VERSION "created by canmatrix"

NS_ :

BS_:

BU_: IPD

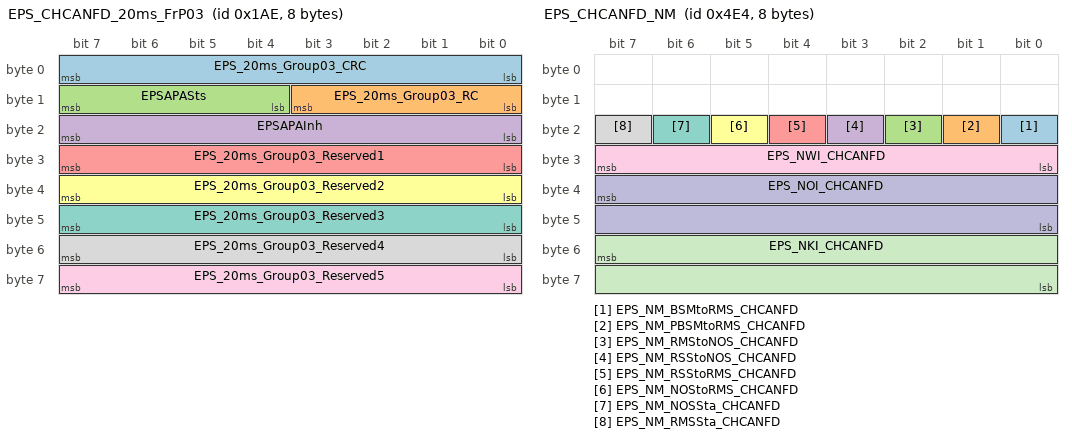
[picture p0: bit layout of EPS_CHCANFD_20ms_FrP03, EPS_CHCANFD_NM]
BO_ 430 EPS_CHCANFD_20ms_FrP03: 8 Vector__XXX
 SG_ EPS_20ms_Group03_CRC : 7|8@0+ (1,0) [0|255] "null" IPD
 SG_ EPS_20ms_Group03_RC : 11|4@0+ (1,0) [0|15] "null" IPD
 SG_ EPSAPASts : 15|4@0+ (1,0) [0|15] "null" IPD
 SG_ EPSAPAInh : 23|8@0+ (1,0) [0|255] "null" IPD
 SG_ EPS_20ms_Group03_Reserved1 : 31|8@0+ (1,0) [0|255] "null" IPD
 SG_ EPS_20ms_Group03_Reserved2 : 39|8@0+ (1,0) [0|255] "null" IPD
 SG_ EPS_20ms_Group03_Reserved3 : 47|8@0+ (1,0) [0|255] "null" IPD
 SG_ EPS_20ms_Group03_Reserved4 : 55|8@0+ (1,0) [0|255] "null" IPD
 SG_ EPS_20ms_Group03_Reserved5 : 63|8@0+ (1,0) [0|255] "null" IPD

BO_ 1681 EPS_CHCANFD_CT_Tx: 8 Vector__XXX
 SG_ EPSCTTX : 7|64@0+ (1,0) [0|18446744073709551615] "null" IPD

BO_ 1252 EPS_CHCANFD_NM: 8 Vector__XXX
 SG_ EPS_NM_BSMtoRMS_CHCANFD : 16|1@0+ (1,0) [0|1] "null" Vector__XXX
 SG_ EPS_NM_PBSMtoRMS_CHCANFD : 17|1@0+ (1,0) [0|1] "null" Vector__XXX
 SG_ EPS_NM_RMStoNOS_CHCANFD : 18|1@0+ (1,0) [0|1] "null" Vector__XXX
 SG_ EPS_NM_RSStoNOS_CHCANFD : 19|1@0+ (1,0) [0|1] "null" Vector__XXX
 SG_ EPS_NM_RSStoRMS_CHCANFD : 20|1@0+ (1,0) [0|1] "null" Vector__XXX
 SG_ EPS_NM_NOStoRMS_CHCANFD : 21|1@0+ (1,0) [0|1] "null" Vector__XXX
 SG_ EPS_NM_NOSSta_CHCANFD : 22|1@0+ (1,0) [0|1] "null" Vector__XXX
 SG_ EPS_NM_RMSSta_CHCANFD : 23|1@0+ (1,0) [0|1] "null" Vector__XXX
 SG_ EPS_NWI_CHCANFD : 31|8@0+ (1,0) [0|255] "null" Vector__XXX
 SG_ EPS_NOI_CHCANFD : 39|16@0+ (1,0) [0|65535] "null" Vector__XXX
 SG_ EPS_NKI_CHCANFD : 55|16@0+ (1,0) [0|65535] "null" Vector__XXX

BO_ 956 FVCM_BKPCANFD_100ms_FrP05: 64 IPD
 SG_ PilotSysMsg : 15|4@0+ (1,0) [0|15] "null" Vector__XXX
 SG_ Lane0_C0 : 23|12@0+ (0.00390625,-8) [-8.00000000|7.99609375] "null" Vector__XXX
 SG_ Lane0_C1 : 27|12@0+ (0.00048828125,-1) [-1.00000000000|0.99951171875] "null" Vector__XXX
 SG_ Lane0_C2 : 47|12@0+ (0.000015259,-0.03124285) [-0.031242850|0.031242755] "null" Vector__XXX
 SG_ Lane0_C3 : 51|12@0+ (4.768E-007,-2.3842E-007) [-2.3842E-007|0.00195225758] "null" Vector__XXX
 SG_ Lane1_C0 : 71|12@0+ (0.00390625,-8) [-8.00000000|7.99609375] "null" Vector__XXX
 SG_ Lane1_C1 : 75|12@0+ (0.00048828125,-1) [-1.00000000000|0.99951171875] "null" Vector__XXX
 SG_ Lane1_C2 : 95|12@0+ (0.000015259,-0.03124285) [-0.031242850|0.031242755] "null" Vector__XXX
 SG_ Lane1_C3 : 99|12@0+ (4.768E-007,-2.3842E-007) [-2.3842E-007|0.00195225758] "null" Vector__XXX
 SG_ Lane2_C0 : 119|12@0+ (0.00390625,-8) [-8.00000000|7.99609375] "null" Vector__XXX
 SG_ Lane2_C1 : 123|12@0+ (0.00048828125,-1) [-1.00000000000|0.99951171875] "null" Vector__XXX
 SG_ Lane2_C2 : 143|12@0+ (0.000015259,-0.03124285) [-0.031242850|0.031242755] "null" Vector__XXX
 SG_ Lane2_C3 : 147|12@0+ (0.0000038147,-0.0078125) [-0.0078125000|0.0078086965] "null" Vector__XXX
 SG_ Lane3_C0 : 167|12@0+ (0.00390625,-8) [-8.00000000|7.99609375] "null" Vector__XXX
 SG_ Lane3_C1 : 171|12@0+ (0.00048828125,-1) [-1.00000000000|0.99951171875] "null" Vector__XXX
 SG_ Lane3_C2 : 191|12@0+ (0.000015259,-0.03124285) [-0.031242850|0.031242755] "null" Vector__XXX
 SG_ Lane3_C3 : 195|12@0+ (0.0000038147,-0.0078125) [-0.0078125000|0.0078086965] "null" Vector__XXX
 SG_ Lane0_ViewRangeStart : 215|8@0+ (0.25,0) [0.00|63.75] "null" Vector__XXX
 SG_ Lane1_ViewRangeStart : 223|8@0+ (0.25,0) [0.00|63.75] "null" Vector__XXX
 SG_ Lane2_ViewRangeStart : 231|8@0+ (0.25,0) [0.00|63.75] "null" Vector__XXX
 SG_ Lane3_ViewRangeStart : 239|8@0+ (0.25,0) [0.00|63.75] "null" Vector__XXX
 SG_ Lane0_ViewRangeEnd : 247|9@0+ (0.25,0) [0.00|127.75] "null" Vector__XXX
 SG_ Lane1_ViewRangeEnd : 248|9@0+ (0.25,0) [0.00|127.75] "null" Vector__XXX
 SG_ Lane0_ExistPrblty : 254|6@0+ (0.015625,0) [0.000000|0.984375] "null" Vector__XXX
 SG_ Lane2_ViewRangeEnd : 271|9@0+ (0.25,0) [0.00|127.75] "null" Vector__XXX
 SG_ Lane3_ViewRangeEnd : 272|9@0+ (0.25,0) [0.00|127.75] "null" Vector__XXX
 SG_ Lane1_ExistPrblty : 278|6@0+ (0.015625,0) [0.000000|0.984375] "null" Vector__XXX
 SG_ Lane0_Part0_SyncFrameIndex : 291|4@0+ (1,0) [0|15] "null" Vector__XXX
 SG_ Lane0_ID : 295|4@0+ (1,0) [0|15] "null" Vector__XXX
 SG_ Lane1_Part0_SyncFrameIndex : 299|4@0+ (1,0) [0|15] "null" Vector__XXX
 SG_ Lane1_ID : 303|4@0+ (1,0) [0|15] "null" Vector__XXX
 SG_ Lane2_Part0_SyncFrameIndex : 307|4@0+ (1,0) [0|15] "null" Vector__XXX
 SG_ Lane2_ID : 311|4@0+ (1,0) [0|15] "null" Vector__XXX
 SG_ Lane3_Part0_SyncFrameIndex : 315|4@0+ (1,0) [0|15] "null" Vector__XXX
 SG_ Lane3_ID : 319|4@0+ (1,0) [0|15] "null" Vector__XXX
 SG_ TLRMsgReq : 321|2@0+ (1,0) [0|3] "null" Vector__XXX
 SG_ Lane0_MarkerColor : 324|3@0+ (1,0) [0|7] "null" Vector__XXX
 SG_ Lane0_location : 327|3@0+ (1,0) [0|7] "null" Vector__XXX
 SG_ TLRSysSts : 329|2@0+ (1,0) [0|3] "null" Vector__XXX
 SG_ Lane1_location : 332|3@0+ (1,0) [0|7] "null" Vector__XXX
 SG_ Lane0_MarkerType : 335|3@0+ (1,0) [0|7] "null" Vector__XXX
 SG_ Lane1_MarkerType : 340|3@0+ (1,0) [0|7] "null" Vector__XXX
 SG_ Lane1_MarkerColor : 343|3@0+ (1,0) [0|7] "null" Vector__XXX
 SG_ Lane2_ExistPrblty : 351|6@0+ (0.015625,0) [0.000000|0.984375] "null" Vector__XXX
 SG_ Lane2_MarkerColor : 356|3@0+ (1,0) [0|7] "null" Vector__XXX
 SG_ Lane2_location : 359|3@0+ (1,0) [0|7] "null" Vector__XXX
 SG_ Lane3_location : 364|3@0+ (1,0) [0|7] "null" Vector__XXX
 SG_ Lane2_MarkerType : 367|3@0+ (1,0) [0|7] "null" Vector__XXX
 SG_ Lane3_ExistPrblty : 375|6@0+ (0.015625,0) [0.000000|0.984375] "null" Vector__XXX
 SG_ Lane3_MarkerType : 380|3@0+ (1,0) [0|7] "null" Vector__XXX
 SG_ Lane3_MarkerColor : 383|3@0+ (1,0) [0|7] "null" Vector__XXX
 SG_ TLRWarning : 388|3@0+ (1,0) [0|7] "null" Vector__XXX
 SG_ TLRMdSwDspCmd : 391|3@0+ (1,0) [0|7] "null" Vector__XXX
 SG_ SpdLmtOfstSetResp : 399|6@0+ (1,-20) [-20|43] "null" Vector__XXX
 SG_ ACCDetObjHdngAng : 495|8@0+ (2,-180) [-180|330] "null" Vector__XXX
 SG_ CCSpdVcCmdCnfm : 503|3@0+ (1,0) [0|7] "null" Vector__XXX

BO_ 163 FVCM_BKPCANFD_10ms_FrP01: 12 IPD
 SG_ FVCM_10ms_Group01_CRC : 7|8@0+ (1,0) [0|255] "null" Vector__XXX
 SG_ FVCM_10ms_Group01_RC : 11|4@0+ (1,0) [0|15] "null" Vector__XXX
 SG_ LKAReqToqSts : 13|2@0+ (1,0) [0|3] "null" Vector__XXX
 SG_ LKAReqAngSts : 15|2@0+ (1,0) [0|3] "null" Vector__XXX
 SG_ LKAReqAng : 23|16@0+ (0.005,-163) [-163.000|164.675] "Degree" Vector__XXX
 SG_ LKAReqToq : 39|11@0+ (0.01,-10.24) [-10.24|10.23] "Nm" Vector__XXX
 SG_ FVCM_10ms_Group01_Reserved1 : 44|5@0+ (1,0) [0|31] "null" Vector__XXX
 SG_ FVCM_10ms_Group01_Reserved2 : 55|8@0+ (1,0) [0|255] "null" Vector__XXX
 SG_ FVCM_10ms_Group01_Reserved3 : 63|8@0+ (1,0) [0|255] "null" Vector__XXX
 SG_ FVCM_10ms_Group01_Reserved4 : 71|8@0+ (1,0) [0|255] "null" Vector__XXX
 SG_ FVCM_10ms_Group01_Reserved5 : 79|8@0+ (1,0) [0|255] "null" Vector__XXX
 SG_ FVCM_10ms_Group01_Reserved6 : 87|8@0+ (1,0) [0|255] "null" Vector__XXX
 SG_ FVCM_10ms_Group01_Reserved7 : 95|8@0+ (1,0) [0|255] "null" Vector__XXX

BO_ 988 IBS_CHCANFD_100ms_FrP15: 8 Vector__XXX
 SG_ IBS_100ms_Group15_CRC : 7|8@0+ (1,0) [0|255] "null" IPD
 SG_ IBS_100ms_Group15_RC : 11|4@0+ (1,0) [0|15] "null" IPD
 SG_ IBS_100ms_Group15_Reserved2 : 12|1@0+ (1,0) [0|1] "null" IPD
 SG_ BrkFltAlrm_GB : 13|1@0+ (1,0) [0|1] "null" IPD
 SG_ IBS_100ms_Group15_Reserved1 : 14|1@0+ (1,0) [0|1] "null" IPD
 SG_ BrkFrc_GB : 15|1@0+ (1,0) [0|1] "null" IPD
 SG_ DistRCAvgDrvnSrc : 16|1@0+ (1,0) [0|1] "null" IPD
 SG_ DistRCAvgDrvnRstOcd : 17|1@0+ (1,0) [0|1] "null" IPD
 SG_ CsbLvlSts : 20|3@0+ (1,0) [0|7] "null" IPD
 SG_ IBSABSlvlResp : 23|3@0+ (1,0) [0|7] "null" IPD
 SG_ DistRCAvgDrvn : 31|13@0+ (0.125,0) [0.000|1023.875] "m" IPD
 SG_ IBS_100ms_Group15_Reserved3 : 33|2@0+ (1,0) [0|3] "null" IPD
 SG_ DistRCAvgDrvnV : 34|1@0+ (1,0) [0|1] "null" IPD
 SG_ IBS_100ms_Group15_Reserved4 : 41|2@0+ (1,0) [0|3] "null" IPD
 SG_ IBSESPlvlResp : 44|3@0+ (1,0) [0|7] "null" IPD
 SG_ IBSTCSlvlResp : 47|3@0+ (1,0) [0|7] "null" IPD
 SG_ IBS_100ms_Group15_Reserved5 : 55|8@0+ (1,0) [0|255] "null" IPD
 SG_ IBS_100ms_Group15_Reserved6 : 63|8@0+ (1,0) [0|255] "null" IPD

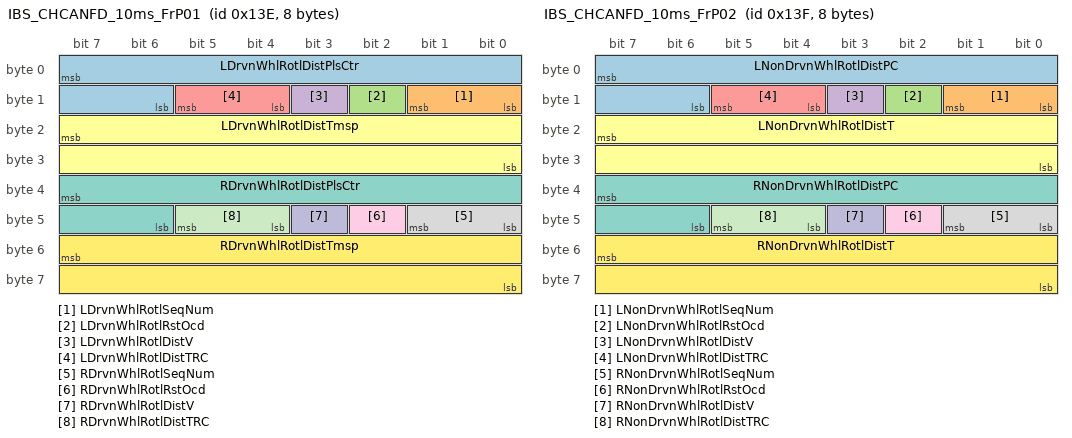
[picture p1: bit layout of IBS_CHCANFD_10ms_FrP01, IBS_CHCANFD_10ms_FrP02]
BO_ 318 IBS_CHCANFD_10ms_FrP01: 8 Vector__XXX
 SG_ LDrvnWhlRotlDistPlsCtr : 7|10@0+ (1,0) [0|1023] "null" IPD
 SG_ LDrvnWhlRotlSeqNum : 9|2@0+ (1,0) [0|3] "null" IPD
 SG_ LDrvnWhlRotlRstOcd : 10|1@0+ (1,0) [0|1] "null" IPD
 SG_ LDrvnWhlRotlDistV : 11|1@0+ (1,0) [0|1] "null" IPD
 SG_ LDrvnWhlRotlDistTRC : 13|2@0+ (1,0) [0|3] "null" IPD
 SG_ LDrvnWhlRotlDistTmsp : 23|16@0+ (1,0) [0|65535] "null" IPD
 SG_ RDrvnWhlRotlDistPlsCtr : 39|10@0+ (1,0) [0|1023] "null" IPD
 SG_ RDrvnWhlRotlSeqNum : 41|2@0+ (1,0) [0|3] "ms" IPD
 SG_ RDrvnWhlRotlRstOcd : 42|1@0+ (1,0) [0|1] "null" IPD
 SG_ RDrvnWhlRotlDistV : 43|1@0+ (1,0) [0|1] "null" IPD
 SG_ RDrvnWhlRotlDistTRC : 45|2@0+ (1,0) [0|3] "ms" IPD
 SG_ RDrvnWhlRotlDistTmsp : 55|16@0+ (1,0) [0|65535] "ms" IPD

BO_ 319 IBS_CHCANFD_10ms_FrP02: 8 Vector__XXX
 SG_ LNonDrvnWhlRotlDistPC : 7|10@0+ (1,0) [0|1023] "null" IPD
 SG_ LNonDrvnWhlRotlSeqNum : 9|2@0+ (1,0) [0|3] "null" IPD
 SG_ LNonDrvnWhlRotlRstOcd : 10|1@0+ (1,0) [0|1] "null" IPD
 SG_ LNonDrvnWhlRotlDistV : 11|1@0+ (1,0) [0|1] "null" IPD
 SG_ LNonDrvnWhlRotlDistTRC : 13|2@0+ (1,0) [0|3] "null" IPD
 SG_ LNonDrvnWhlRotlDistT : 23|16@0+ (1,0) [0|65535] "null" IPD
 SG_ RNonDrvnWhlRotlDistPC : 39|10@0+ (1,0) [0|1023] "null" IPD
 SG_ RNonDrvnWhlRotlSeqNum : 41|2@0+ (1,0) [0|3] "null" IPD
 SG_ RNonDrvnWhlRotlRstOcd : 42|1@0+ (1,0) [0|1] "null" IPD
 SG_ RNonDrvnWhlRotlDistV : 43|1@0+ (1,0) [0|1] "null" IPD
 SG_ RNonDrvnWhlRotlDistTRC : 45|2@0+ (1,0) [0|3] "null" IPD
 SG_ RNonDrvnWhlRotlDistT : 55|16@0+ (1,0) [0|65535] "null" IPD

BO_ 423 IBS_CHCANFD_20ms_FrP07: 8 Vector__XXX
 SG_ IBS_20ms_Group07_CRC : 7|8@0+ (1,0) [0|255] "null" IPD
 SG_ IBS_20ms_Group07_RC : 11|4@0+ (1,0) [0|15] "null" IPD
 SG_ HDCSysSts : 14|3@0+ (1,0) [0|7] "null" IPD
 SG_ ABSIO : 15|1@0+ (1,0) [0|1] "null" IPD
 SG_ VSESysA : 16|1@0+ (1,0) [0|1] "null" IPD
 SG_ BrkSysYlwBrkTlltReq : 17|1@0+ (1,0) [0|1] "null" IPD
 SG_ VSESts : 20|3@0+ (1,0) [0|7] "null" IPD
 SG_ VSEMd : 23|3@0+ (1,0) [0|7] "null" IPD
 SG_ MultColBrkEnbA : 24|1@0+ (1,0) [0|1] "null" IPD
 SG_ EBDFaultSt : 25|1@0+ (1,0) [0|1] "null" IPD
 SG_ TCSOpngSts : 28|3@0+ (1,0) [0|7] "null" IPD
 SG_ TCSOpngMd : 31|3@0+ (1,0) [0|7] "null" IPD
 SG_ BrkSysHillStAstAvlbl : 32|1@0+ (1,0) [0|1] "null" IPD
 SG_ RgtvBrkFnFltSts : 33|1@0+ (1,0) [0|1] "null" IPD
 SG_ MSRF : 34|1@0+ (1,0) [0|1] "null" IPD
 SG_ AutoHoldSysSts : 36|2@0+ (1,0) [0|3] "null" IPD
 SG_ AutoHoldMsg : 39|3@0+ (1,0) [0|7] "null" IPD
 SG_ EBDA : 40|1@0+ (1,0) [0|1] "null" IPD
 SG_ RgtvBrkFnSts : 41|1@0+ (1,0) [0|1] "null" IPD
 SG_ TCSEnbd : 42|1@0+ (1,0) [0|1] "null" IPD
 SG_ HBAActiveSt : 43|1@0+ (1,0) [0|1] "null" IPD
 SG_ TCSA : 44|1@0+ (1,0) [0|1] "null" IPD
 SG_ EnDragToqRducnA : 45|1@0+ (1,0) [0|1] "null" IPD
 SG_ ABSF : 46|1@0+ (1,0) [0|1] "null" IPD
 SG_ ABSA : 47|1@0+ (1,0) [0|1] "null" IPD
 SG_ HBAValidSt : 48|1@0+ (1,0) [0|1] "null" IPD
 SG_ MSRA : 49|1@0+ (1,0) [0|1] "null" IPD
 SG_ EmgcBrkAV : 50|1@0+ (1,0) [0|1] "null" IPD
 SG_ EmgcBrkA : 51|1@0+ (1,0) [0|1] "null" IPD
 SG_ BrkSysRedBrkTlltReq : 52|1@0+ (1,0) [0|1] "null" IPD
 SG_ BrkSysHillStAstSts : 55|3@0+ (1,0) [0|7] "null" IPD
 SG_ AVHSigPdlSts : 57|2@0+ (1,0) [0|3] "null" IPD
 SG_ AutoHoldMdSts : 59|2@0+ (1,0) [0|3] "null" IPD
 SG_ SoftSpSysSts : 61|2@0+ (1,0) [0|3] "null" IPD
 SG_ MulColBrkA : 62|1@0+ (1,0) [0|1] "null" IPD
 SG_ MulColBrkAvlblySts : 63|1@0+ (1,0) [0|1] "null" IPD

BO_ 342 IBS_CHCANFD_20ms_FrP08: 8 Vector__XXX
 SG_ IBS_20ms_Group08_CRC : 7|8@0+ (1,0) [0|255] "null" IPD
 SG_ IBS_20ms_Group08_RC : 11|4@0+ (1,0) [0|15] "null" IPD
 SG_ EPBSts : 13|2@0+ (1,0) [0|3] "null" IPD
 SG_ EPBAppcnSts : 15|2@0+ (1,0) [0|3] "null" IPD
 SG_ EPBCCCanclReqd : 16|1@0+ (1,0) [0|1] "null" IPD
 SG_ EPBSysStsIndReq : 18|2@0+ (1,0) [0|3] "null" IPD
 SG_ EPBSwSts : 20|2@0+ (1,0) [0|3] "null" IPD
 SG_ EPBAvlblySts : 23|3@0+ (1,0) [0|7] "null" IPD
 SG_ EPBSysAudWrnngReq : 25|2@0+ (1,0) [0|3] "null" IPD
 SG_ EPBSwStsV : 26|1@0+ (1,0) [0|1] "null" IPD
 SG_ EPBSysWrnngIndReq : 28|2@0+ (1,0) [0|3] "null" IPD
 SG_ EPBSysDspMsgReq : 31|3@0+ (1,0) [0|7] "null" IPD
 SG_ ChSysTrBrkAxleToqVal : 37|14@0+ (2,0) [0|32766] "Nm" IPD
 SG_ EPBAPAAvlbl : 38|1@0+ (1,0) [0|1] "null" IPD
 SG_ EPBFlrSts : 39|1@0+ (1,0) [0|1] "null" IPD
 SG_ ChSysSecyBrkAxleToqVal : 53|14@0+ (2,0) [0|32766] "Nm" IPD
 SG_ ChSysSecyBrkAxleToqValV : 54|1@0+ (1,0) [0|1] "null" IPD
 SG_ ChSysTrBrkAxleToqValV : 55|1@0+ (1,0) [0|1] "null" IPD

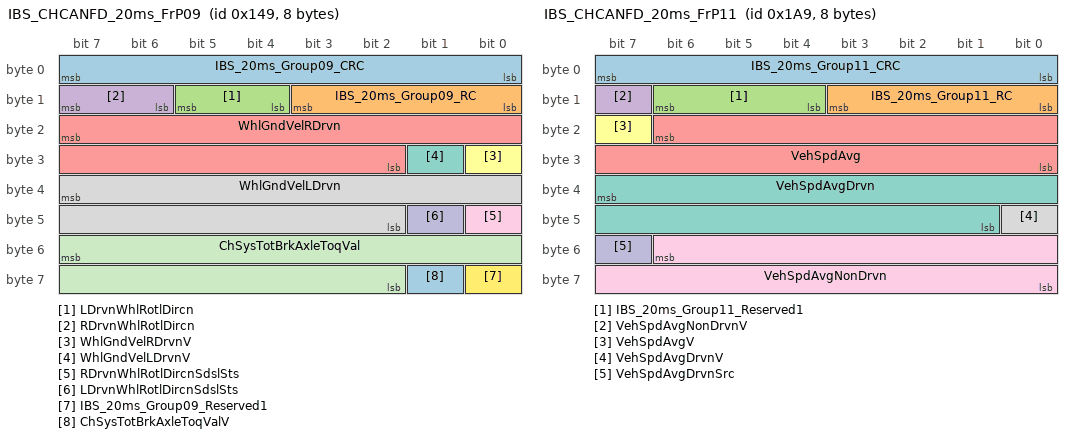
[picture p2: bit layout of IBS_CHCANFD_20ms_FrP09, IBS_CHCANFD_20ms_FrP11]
BO_ 329 IBS_CHCANFD_20ms_FrP09: 8 Vector__XXX
 SG_ IBS_20ms_Group09_CRC : 7|8@0+ (1,0) [0|255] "null" IPD
 SG_ IBS_20ms_Group09_RC : 11|4@0+ (1,0) [0|15] "null" IPD
 SG_ LDrvnWhlRotlDircn : 13|2@0+ (1,0) [0|3] "null" IPD
 SG_ RDrvnWhlRotlDircn : 15|2@0+ (1,0) [0|3] "null" IPD
 SG_ WhlGndVelRDrvn : 23|14@0+ (0.03125,0) [0.00000|511.96875] "kph" IPD
 SG_ WhlGndVelRDrvnV : 24|1@0+ (1,0) [0|1] "null" IPD
 SG_ WhlGndVelLDrvnV : 25|1@0+ (1,0) [0|1] "null" IPD
 SG_ WhlGndVelLDrvn : 39|14@0+ (0.03125,0) [0.00000|511.96875] "kph" IPD
 SG_ RDrvnWhlRotlDircnSdslSts : 40|1@0+ (1,0) [0|1] "null" IPD
 SG_ LDrvnWhlRotlDircnSdslSts : 41|1@0+ (1,0) [0|1] "null" IPD
 SG_ ChSysTotBrkAxleToqVal : 55|14@0+ (2,0) [0|32766] "Nm" IPD
 SG_ IBS_20ms_Group09_Reserved1 : 56|1@0+ (1,0) [0|1] "null" IPD
 SG_ ChSysTotBrkAxleToqValV : 57|1@0+ (1,0) [0|1] "null" IPD

BO_ 425 IBS_CHCANFD_20ms_FrP11: 8 Vector__XXX
 SG_ IBS_20ms_Group11_CRC : 7|8@0+ (1,0) [0|255] "null" IPD
 SG_ IBS_20ms_Group11_RC : 11|4@0+ (1,0) [0|15] "null" IPD
 SG_ IBS_20ms_Group11_Reserved1 : 14|3@0+ (1,0) [0|7] "null" IPD
 SG_ VehSpdAvgNonDrvnV : 15|1@0+ (1,0) [0|1] "null" IPD
 SG_ VehSpdAvg : 22|15@0+ (0.015625,0) [0.000000|511.984375] "km/h" IPD
 SG_ VehSpdAvgV : 23|1@0+ (1,0) [0|1] "null" IPD
 SG_ VehSpdAvgDrvn : 39|15@0+ (0.015625,0) [0.000000|511.984375] "km/h" IPD
 SG_ VehSpdAvgDrvnV : 40|1@0+ (1,0) [0|1] "null" IPD
 SG_ VehSpdAvgNonDrvn : 54|15@0+ (0.015625,0) [0.000000|511.984375] "km/h" IPD
 SG_ VehSpdAvgDrvnSrc : 55|1@0+ (1,0) [0|1] "null" IPD

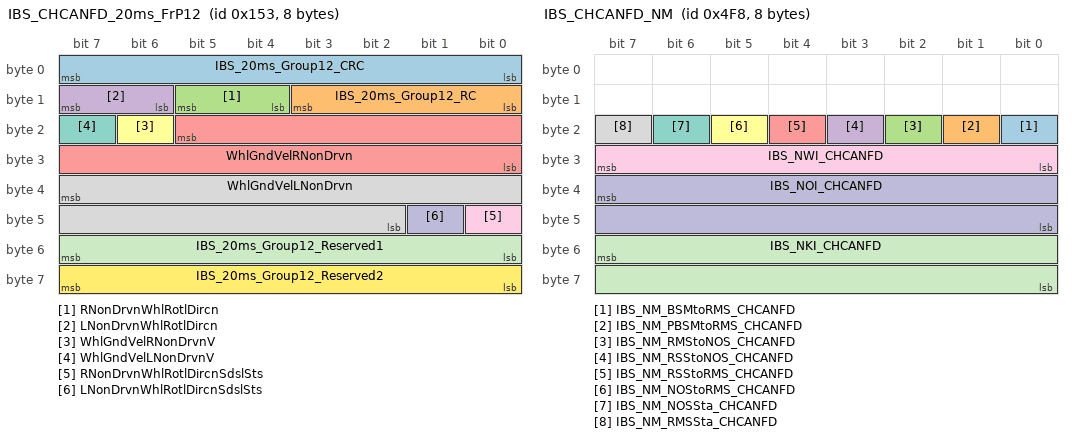
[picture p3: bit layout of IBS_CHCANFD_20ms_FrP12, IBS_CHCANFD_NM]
BO_ 339 IBS_CHCANFD_20ms_FrP12: 8 Vector__XXX
 SG_ IBS_20ms_Group12_CRC : 7|8@0+ (1,0) [0|255] "null" IPD
 SG_ IBS_20ms_Group12_RC : 11|4@0+ (1,0) [0|15] "null" IPD
 SG_ RNonDrvnWhlRotlDircn : 13|2@0+ (1,0) [0|3] "null" IPD
 SG_ LNonDrvnWhlRotlDircn : 15|2@0+ (1,0) [0|3] "null" IPD
 SG_ WhlGndVelRNonDrvn : 21|14@0+ (0.03125,0) [0.00000|511.96875] "kph" IPD
 SG_ WhlGndVelRNonDrvnV : 22|1@0+ (1,0) [0|1] "null" IPD
 SG_ WhlGndVelLNonDrvnV : 23|1@0+ (1,0) [0|1] "null" IPD
 SG_ WhlGndVelLNonDrvn : 39|14@0+ (0.03125,0) [0.00000|511.96875] "kph" IPD
 SG_ RNonDrvnWhlRotlDircnSdslSts : 40|1@0+ (1,0) [0|1] "null" IPD
 SG_ LNonDrvnWhlRotlDircnSdslSts : 41|1@0+ (1,0) [0|1] "null" IPD
 SG_ IBS_20ms_Group12_Reserved1 : 55|8@0+ (1,0) [0|255] "null" IPD
 SG_ IBS_20ms_Group12_Reserved2 : 63|8@0+ (1,0) [0|255] "null" IPD

BO_ 1272 IBS_CHCANFD_NM: 8 Vector__XXX
 SG_ IBS_NM_BSMtoRMS_CHCANFD : 16|1@0+ (1,0) [0|1] "null" Vector__XXX
 SG_ IBS_NM_PBSMtoRMS_CHCANFD : 17|1@0+ (1,0) [0|1] "null" Vector__XXX
 SG_ IBS_NM_RMStoNOS_CHCANFD : 18|1@0+ (1,0) [0|1] "null" Vector__XXX
 SG_ IBS_NM_RSStoNOS_CHCANFD : 19|1@0+ (1,0) [0|1] "null" Vector__XXX
 SG_ IBS_NM_RSStoRMS_CHCANFD : 20|1@0+ (1,0) [0|1] "null" Vector__XXX
 SG_ IBS_NM_NOStoRMS_CHCANFD : 21|1@0+ (1,0) [0|1] "null" Vector__XXX
 SG_ IBS_NM_NOSSta_CHCANFD : 22|1@0+ (1,0) [0|1] "null" Vector__XXX
 SG_ IBS_NM_RMSSta_CHCANFD : 23|1@0+ (1,0) [0|1] "null" Vector__XXX
 SG_ IBS_NWI_CHCANFD : 31|8@0+ (1,0) [0|255] "null" Vector__XXX
 SG_ IBS_NOI_CHCANFD : 39|16@0+ (1,0) [0|65535] "null" Vector__XXX
 SG_ IBS_NKI_CHCANFD : 55|16@0+ (1,0) [0|65535] "null" Vector__XXX

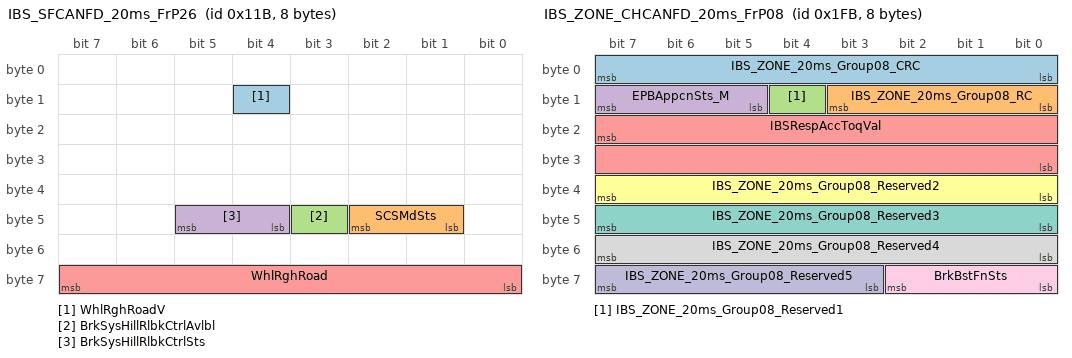
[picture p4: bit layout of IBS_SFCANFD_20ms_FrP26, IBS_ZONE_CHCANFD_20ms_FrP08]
BO_ 283 IBS_SFCANFD_20ms_FrP26: 8 Vector__XXX
 SG_ WhlRghRoadV : 12|1@0+ (1,0) [0|1] "null" IPD
 SG_ SCSMdSts : 42|2@0+ (1,0) [0|3] "null" Vector__XXX
 SG_ BrkSysHillRlbkCtrlAvlbl : 43|1@0+ (1,0) [0|1] "null" Vector__XXX
 SG_ BrkSysHillRlbkCtrlSts : 45|2@0+ (1,0) [0|3] "null" Vector__XXX
 SG_ WhlRghRoad : 63|8@0+ (0.781,0) [0.000|199.155] "null" IPD

BO_ 507 IBS_ZONE_CHCANFD_20ms_FrP08: 8 Vector__XXX
 SG_ IBS_ZONE_20ms_Group08_CRC : 7|8@0+ (1,0) [0|255] "null" IPD
 SG_ IBS_ZONE_20ms_Group08_RC : 11|4@0+ (1,0) [0|15] "null" IPD
 SG_ IBS_ZONE_20ms_Group08_Reserved1 : 12|1@0+ (1,0) [0|1] "null" IPD
 SG_ EPBAppcnSts_M : 15|3@0+ (1,0) [0|7] "null" IPD
 SG_ IBSRespAccToqVal : 23|16@0+ (1,0) [0|65535] "Nm" IPD
 SG_ IBS_ZONE_20ms_Group08_Reserved2 : 39|8@0+ (1,0) [0|255] "null" IPD
 SG_ IBS_ZONE_20ms_Group08_Reserved3 : 47|8@0+ (1,0) [0|255] "null" IPD
 SG_ IBS_ZONE_20ms_Group08_Reserved4 : 55|8@0+ (1,0) [0|255] "null" IPD
 SG_ BrkBstFnSts : 58|3@0+ (1,0) [0|7] "null" IPD
 SG_ IBS_ZONE_20ms_Group08_Reserved5 : 63|5@0+ (1,0) [0|31] "null" IPD

BO_ 382 ICBAD_BKPCANFD_20ms_FrP07: 8 IPD
 SG_ ICBAD_20ms_Group07_CRC : 7|8@0+ (1,0) [0|255] "null" Vector__XXX
 SG_ ICBAD_20ms_Group07_RC : 11|4@0+ (1,0) [0|15] "null" Vector__XXX
 SG_ ACCSdslReq : 12|1@0+ (1,0) [0|1] "null" Vector__XXX
 SG_ ACCGoReq : 13|1@0+ (1,0) [0|1] "null" Vector__XXX
 SG_ ACCAccReqSts_CH : 15|2@0+ (1,0) [0|3] "null" Vector__XXX
 SG_ ACCAccReqVal : 18|11@0+ (0.006,-10.278) [-10.278|2.004] "null" Vector__XXX
 SG_ APAEPBOPReq : 20|2@0+ (1,0) [0|3] "null" Vector__XXX
 SG_ ACCSysFltSts : 23|3@0+ (1,0) [0|7] "null" Vector__XXX
 SG_ AIPkgAPASCSAcclReqVal : 34|11@0+ (0.005,-9.22) [-9.220|1.015] "m/s^2" Vector__XXX
 SG_ ACCSysSts : 37|3@0+ (1,0) [0|7] "null" Vector__XXX
 SG_ APASCSAcclReqSts : 38|1@0+ (1,0) [0|1] "null" Vector__XXX
 SG_ APAEPBOPReqV : 39|1@0+ (1,0) [0|1] "null" Vector__XXX
 SG_ AutodDrvngSysSCSSdslReqV : 48|1@0+ (1,0) [0|1] "null" Vector__XXX
 SG_ AutodDrvngSysSCSSdslReq : 49|1@0+ (1,0) [0|1] "null" Vector__XXX
 SG_ AutodDrvngSysEmgcBrkReqV : 50|1@0+ (1,0) [0|1] "null" Vector__XXX
 SG_ AutodDrvngSysEmgcBrkReq : 51|1@0+ (1,0) [0|1] "null" Vector__XXX
 SG_ ICBAD_20ms_Group07_Reserved1 : 55|4@0+ (1,0) [0|15] "null" Vector__XXX
 SG_ AutodDrvngSysSCSDrvOffReqV : 56|1@0+ (1,0) [0|1] "null" Vector__XXX
 SG_ AutodDrvngSysSCSDrvOffReq : 57|1@0+ (1,0) [0|1] "null" Vector__XXX
 SG_ AutodDrvngSysMdReqV : 58|1@0+ (1,0) [0|1] "null" Vector__XXX
 SG_ AutodDrvngSysMdReq : 59|1@0+ (1,0) [0|1] "null" Vector__XXX
 SG_ AutodDrvngSysFlrStsV : 60|1@0+ (1,0) [0|1] "null" Vector__XXX
 SG_ AutodDrvngSysFlrSts : 63|3@0+ (1,0) [0|7] "null" Vector__XXX

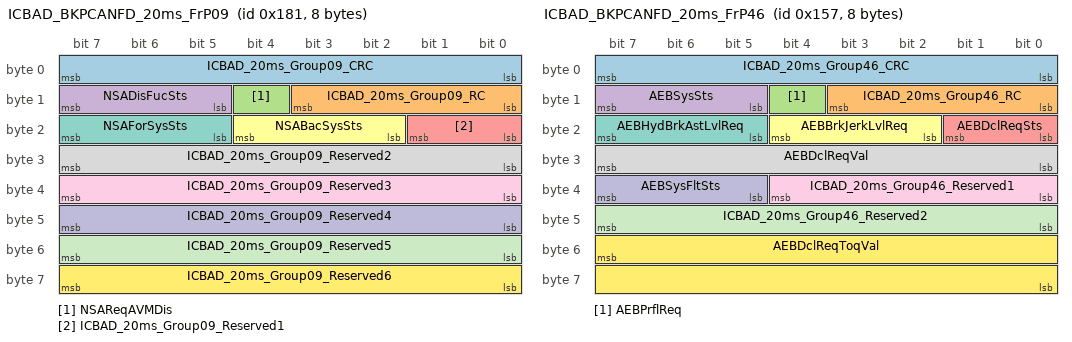
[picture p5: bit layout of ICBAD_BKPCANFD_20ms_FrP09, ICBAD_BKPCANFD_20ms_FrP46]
BO_ 385 ICBAD_BKPCANFD_20ms_FrP09: 8 IPD
 SG_ ICBAD_20ms_Group09_CRC : 7|8@0+ (1,0) [0|255] "null" Vector__XXX
 SG_ ICBAD_20ms_Group09_RC : 11|4@0+ (1,0) [0|15] "null" Vector__XXX
 SG_ NSAReqAVMDis : 12|1@0+ (1,0) [0|1] "null" Vector__XXX
 SG_ NSADisFucSts : 15|3@0+ (1,0) [0|7] "null" Vector__XXX
 SG_ ICBAD_20ms_Group09_Reserved1 : 17|2@0+ (1,0) [0|3] "null" Vector__XXX
 SG_ NSABacSysSts : 20|3@0+ (1,0) [0|7] "null" Vector__XXX
 SG_ NSAForSysSts : 23|3@0+ (1,0) [0|7] "null" Vector__XXX
 SG_ ICBAD_20ms_Group09_Reserved2 : 31|8@0+ (1,0) [0|255] "null" Vector__XXX
 SG_ ICBAD_20ms_Group09_Reserved3 : 39|8@0+ (1,0) [0|255] "null" Vector__XXX
 SG_ ICBAD_20ms_Group09_Reserved4 : 47|8@0+ (1,0) [0|255] "null" Vector__XXX
 SG_ ICBAD_20ms_Group09_Reserved5 : 55|8@0+ (1,0) [0|255] "null" Vector__XXX
 SG_ ICBAD_20ms_Group09_Reserved6 : 63|8@0+ (1,0) [0|255] "null" Vector__XXX

BO_ 343 ICBAD_BKPCANFD_20ms_FrP46: 8 IPD
 SG_ ICBAD_20ms_Group46_CRC : 7|8@0+ (1,0) [0|255] "null" Vector__XXX
 SG_ ICBAD_20ms_Group46_RC : 11|4@0+ (1,0) [0|15] "null" Vector__XXX
 SG_ AEBPrflReq : 12|1@0+ (1,0) [0|1] "null" Vector__XXX
 SG_ AEBSysSts : 15|3@0+ (1,0) [0|7] "null" Vector__XXX
 SG_ AEBDclReqSts : 17|2@0+ (1,0) [0|3] "null" Vector__XXX
 SG_ AEBBrkJerkLvlReq : 20|3@0+ (1,0) [0|7] "null" Vector__XXX
 SG_ AEBHydBrkAstLvlReq : 23|3@0+ (1,0) [0|7] "null" Vector__XXX
 SG_ AEBDclReqVal : 31|8@0+ (0.1,-12.7) [-12.7|12.8] "m/s2" Vector__XXX
 SG_ ICBAD_20ms_Group46_Reserved1 : 36|5@0+ (1,0) [0|31] "null" Vector__XXX
 SG_ AEBSysFltSts : 39|3@0+ (1,0) [0|7] "null" Vector__XXX
 SG_ ICBAD_20ms_Group46_Reserved2 : 47|8@0+ (1,0) [0|255] "null" Vector__XXX
 SG_ AEBDclReqToqVal : 55|16@0+ (1,0) [0|65535] "Nm" Vector__XXX

BO_ 102 ICBAD_CHCANFD_10ms_FrP01: 24 IPD
 SG_ ICBAD_10ms_Group01_CRC : 7|8@0+ (1,0) [0|255] "null" Vector__XXX
 SG_ ICBAD_10ms_Group01_RC : 11|4@0+ (1,0) [0|15] "null" Vector__XXX
 SG_ ICBAD_10ms_Group01_Reserved1 : 15|4@0+ (1,0) [0|15] "null" Vector__XXX
 SG_ PltEPSRdWhlAngReqStsV : 16|1@0+ (1,0) [0|1] "null" Vector__XXX
 SG_ PltEPSRdWhlAngReqSts : 19|3@0+ (1,0) [0|7] "null" Vector__XXX
 SG_ ICBAD_10ms_Group01_Reserved2 : 23|4@0+ (1,0) [0|15] "null" Vector__XXX
 SG_ ICBAD_10ms_Group01_Reserved3 : 31|8@0+ (1,0) [0|255] "null" Vector__XXX
 SG_ ICBAD_10ms_Group01_Reserved4 : 39|8@0+ (1,0) [0|255] "null" Vector__XXX
 SG_ ICBAD_10ms_Group01_Reserved5 : 47|8@0+ (1,0) [0|255] "null" Vector__XXX
 SG_ ICBAD_10ms_Group01_Reserved6 : 55|8@0+ (1,0) [0|255] "null" Vector__XXX
 SG_ ICBAD_10ms_Group01_Reserved7 : 56|1@0+ (1,0) [0|1] "null" Vector__XXX
 SG_ EPSToqAppdCoefnt : 63|7@0+ (0.01,0) [0.00|1.27] "ms" Vector__XXX
 SG_ ICBAD_10ms_Group01_Reserved8 : 71|8@0+ (1,0) [0|255] "null" Vector__XXX
 SG_ ICBAD_10ms_Group01_Reserved9 : 79|8@0+ (1,0) [0|255] "null" Vector__XXX
 SG_ ICBAD_10ms_Group01_Reserved10 : 87|8@0+ (1,0) [0|255] "null" Vector__XXX
 SG_ ICBAD_10ms_Group01_Reserved11 : 95|8@0+ (1,0) [0|255] "null" Vector__XXX
 SG_ ICBAD_10ms_Group01_Reserved12 : 103|8@0+ (1,0) [0|255] "null" Vector__XXX
 SG_ ICBAD_10ms_Group01_Reserved13 : 111|8@0+ (1,0) [0|255] "null" Vector__XXX
 SG_ ICBAD_10ms_Group01_Reserved14 : 119|8@0+ (1,0) [0|255] "null" Vector__XXX
 SG_ ICBAD_10ms_Group01_Reserved15 : 127|8@0+ (1,0) [0|255] "null" Vector__XXX
 SG_ ICBAD_10ms_Group01_Reserved16 : 135|8@0+ (1,0) [0|255] "null" Vector__XXX
 SG_ ICBAD_10ms_Group01_Reserved17 : 143|8@0+ (1,0) [0|255] "null" Vector__XXX
 SG_ ICBAD_10ms_Group01_Reserved18 : 151|8@0+ (1,0) [0|255] "null" Vector__XXX
 SG_ ICBAD_10ms_Group01_Reserved19 : 159|8@0+ (1,0) [0|255] "null" Vector__XXX
 SG_ ICBAD_10ms_Group01_Reserved20 : 167|8@0+ (1,0) [0|255] "null" Vector__XXX
 SG_ ICBAD_10ms_Group01_Reserved21 : 175|8@0+ (1,0) [0|255] "null" Vector__XXX
 SG_ ICBAD_10ms_Group01_Reserved22 : 183|8@0+ (1,0) [0|255] "null" Vector__XXX
 SG_ ICBAD_10ms_Group01_Reserved23 : 191|8@0+ (1,0) [0|255] "null" Vector__XXX

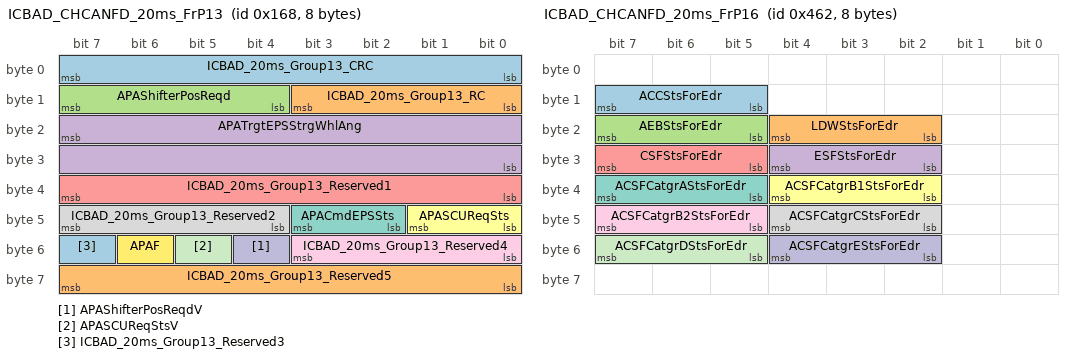
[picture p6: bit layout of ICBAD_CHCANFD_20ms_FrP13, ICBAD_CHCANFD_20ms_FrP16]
BO_ 360 ICBAD_CHCANFD_20ms_FrP13: 8 IPD
 SG_ ICBAD_20ms_Group13_CRC : 7|8@0+ (1,0) [0|255] "null" Vector__XXX
 SG_ ICBAD_20ms_Group13_RC : 11|4@0+ (1,0) [0|15] "null" Vector__XXX
 SG_ APAShifterPosReqd : 15|4@0+ (1,0) [0|15] "null" Vector__XXX
 SG_ APATrgtEPSStrgWhlAng : 23|16@0+ (0.0625,-2048) [-2048.0000|2047.9375] "percent" Vector__XXX
 SG_ ICBAD_20ms_Group13_Reserved1 : 39|8@0+ (1,0) [0|255] "null" Vector__XXX
 SG_ APASCUReqSts : 41|2@0+ (1,0) [0|3] "null" Vector__XXX
 SG_ APACmdEPSSts : 43|2@0+ (1,0) [0|3] "null" Vector__XXX
 SG_ ICBAD_20ms_Group13_Reserved2 : 47|4@0+ (1,0) [0|15] "null" Vector__XXX
 SG_ ICBAD_20ms_Group13_Reserved4 : 51|4@0+ (1,0) [0|15] "null" Vector__XXX
 SG_ APAShifterPosReqdV : 52|1@0+ (1,0) [0|1] "null" Vector__XXX
 SG_ APASCUReqStsV : 53|1@0+ (1,0) [0|1] "null" Vector__XXX
 SG_ APAF : 54|1@0+ (1,0) [0|1] "null" Vector__XXX
 SG_ ICBAD_20ms_Group13_Reserved3 : 55|1@0+ (1,0) [0|1] "null" Vector__XXX
 SG_ ICBAD_20ms_Group13_Reserved5 : 63|8@0+ (1,0) [0|255] "null" Vector__XXX

BO_ 1122 ICBAD_CHCANFD_20ms_FrP16: 8 IPD
 SG_ ACCStsForEdr : 15|3@0+ (1,0) [0|7] "null" Vector__XXX
 SG_ LDWStsForEdr : 20|3@0+ (1,0) [0|7] "null" Vector__XXX
 SG_ AEBStsForEdr : 23|3@0+ (1,0) [0|7] "null" Vector__XXX
 SG_ ESFStsForEdr : 28|3@0+ (1,0) [0|7] "null" Vector__XXX
 SG_ CSFStsForEdr : 31|3@0+ (1,0) [0|7] "null" Vector__XXX
 SG_ ACSFCatgrB1StsForEdr : 36|3@0+ (1,0) [0|7] "null" Vector__XXX
 SG_ ACSFCatgrAStsForEdr : 39|3@0+ (1,0) [0|7] "null" Vector__XXX
 SG_ ACSFCatgrCStsForEdr : 44|3@0+ (1,0) [0|7] "null" Vector__XXX
 SG_ ACSFCatgrB2StsForEdr : 47|3@0+ (1,0) [0|7] "null" Vector__XXX
 SG_ ACSFCatgrEStsForEdr : 52|3@0+ (1,0) [0|7] "null" Vector__XXX
 SG_ ACSFCatgrDStsForEdr : 55|3@0+ (1,0) [0|7] "null" Vector__XXX

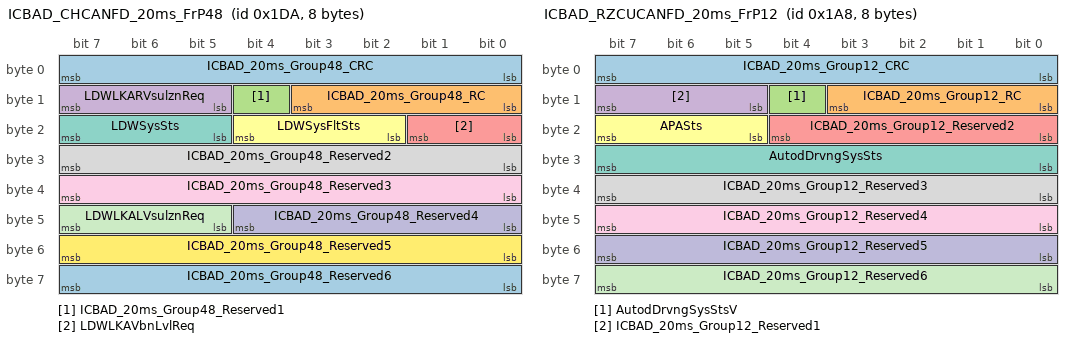
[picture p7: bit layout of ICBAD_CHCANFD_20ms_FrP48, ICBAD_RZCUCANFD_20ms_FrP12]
BO_ 474 ICBAD_CHCANFD_20ms_FrP48: 8 IPD
 SG_ ICBAD_20ms_Group48_CRC : 7|8@0+ (1,0) [0|255] "null" Vector__XXX
 SG_ ICBAD_20ms_Group48_RC : 11|4@0+ (1,0) [0|15] "null" Vector__XXX
 SG_ ICBAD_20ms_Group48_Reserved1 : 12|1@0+ (1,0) [0|1] "null" Vector__XXX
 SG_ LDWLKARVsulznReq : 15|3@0+ (1,0) [0|7] "null" Vector__XXX
 SG_ LDWLKAVbnLvlReq : 17|2@0+ (1,0) [0|3] "null" Vector__XXX
 SG_ LDWSysFltSts : 20|3@0+ (1,0) [0|7] "null" Vector__XXX
 SG_ LDWSysSts : 23|3@0+ (1,0) [0|7] "null" Vector__XXX
 SG_ ICBAD_20ms_Group48_Reserved2 : 31|8@0+ (1,0) [0|255] "null" Vector__XXX
 SG_ ICBAD_20ms_Group48_Reserved3 : 39|8@0+ (1,0) [0|255] "null" Vector__XXX
 SG_ ICBAD_20ms_Group48_Reserved4 : 44|5@0+ (1,0) [0|31] "null" Vector__XXX
 SG_ LDWLKALVsulznReq : 47|3@0+ (1,0) [0|7] "null" Vector__XXX
 SG_ ICBAD_20ms_Group48_Reserved5 : 55|8@0+ (1,0) [0|255] "null" Vector__XXX
 SG_ ICBAD_20ms_Group48_Reserved6 : 63|8@0+ (1,0) [0|255] "null" Vector__XXX

BO_ 47 ICBAD_CHCANFD_Event_FrS03: 16 IPD
 SG_ ToEPSMsgChlg : 7|64@0+ (1,0) [0|18446744073709551615] "null" Vector__XXX

BO_ 424 ICBAD_RZCUCANFD_20ms_FrP12: 8 IPD
 SG_ ICBAD_20ms_Group12_CRC : 7|8@0+ (1,0) [0|255] "null" Vector__XXX
 SG_ ICBAD_20ms_Group12_RC : 11|4@0+ (1,0) [0|15] "null" Vector__XXX
 SG_ AutodDrvngSysStsV : 12|1@0+ (1,0) [0|1] "null" Vector__XXX
 SG_ ICBAD_20ms_Group12_Reserved1 : 15|3@0+ (1,0) [0|7] "null" Vector__XXX
 SG_ ICBAD_20ms_Group12_Reserved2 : 20|5@0+ (1,0) [0|31] "null" Vector__XXX
 SG_ APASts : 23|3@0+ (1,0) [0|7] "null" Vector__XXX
 SG_ AutodDrvngSysSts : 31|8@0+ (1,0) [0|255] "null" Vector__XXX
 SG_ ICBAD_20ms_Group12_Reserved3 : 39|8@0+ (1,0) [0|255] "null" Vector__XXX
 SG_ ICBAD_20ms_Group12_Reserved4 : 47|8@0+ (1,0) [0|255] "null" Vector__XXX
 SG_ ICBAD_20ms_Group12_Reserved5 : 55|8@0+ (1,0) [0|255] "null" Vector__XXX
 SG_ ICBAD_20ms_Group12_Reserved6 : 63|8@0+ (1,0) [0|255] "null" Vector__XXX

BO_ 520 ICBAD_RZCUCANFD_50ms_FrP21: 24 IPD
 SG_ RPShockDistL : 23|10@0+ (0.02,0) [0.00|20.46] "null" Vector__XXX
 SG_ RoadProfileShockLevelL : 29|4@0+ (1,0) [0|15] "null" Vector__XXX
 SG_ RPShockDistR : 39|10@0+ (0.02,0) [0.00|20.46] "null" Vector__XXX
 SG_ RoadProfileShockLevelR : 45|4@0+ (1,0) [0|15] "null" Vector__XXX
 SG_ RoadProfileShockHeightL : 55|9@0- (0.002,0) [-0.512|0.510] "null" Vector__XXX
 SG_ RoadProfileShockDetectedL : 62|1@0+ (1,0) [0|1] "null" Vector__XXX
 SG_ RoadProfileShockHeightR : 71|9@0- (0.002,0) [-0.512|0.510] "null" Vector__XXX
 SG_ RoadProfileShockDetectedR : 78|1@0+ (1,0) [0|1] "null" Vector__XXX
 SG_ RoadProfileShockConfidenceL : 87|7@0+ (0.01,0) [0.00|1.27] "null" Vector__XXX
 SG_ RoadProfileShockConfidenceR : 95|7@0+ (0.01,0) [0.00|1.27] "null" Vector__XXX

BA_DEF_ BO_ "FrameTriggeringName" STRING;
BA_DEF_ BO_ "GenMsgCycleTime" INT 0 65535;
BA_DEF_ BO_ "GenMsgSendType" ENUM  "cyclicX","spontanX","cyclicIfActiveX","spontanWithDelay","cyclicAndSpontanX","cyclicAndSpontanWithDelay","spontanWithRepitition","cyclicIfActiveAndSpontanWD","cyclicIfActiveFast","cyclicWithRepeatOnDemand","none";
BA_DEF_ BO_ "GenMsgStartValue" STRING;
BA_DEF_ BO_ "PduName" STRING;
BA_DEF_ BO_ "VFrameFormat" ENUM  "StandardCAN","ExtendedCAN","reserved","reserved","reserved","reserved","reserved","reserved","reserved","reserved","reserved","reserved","reserved","reserved","StandardCAN_FD","ExtendedCAN_FD";
BA_DEF_ SG_ "CompuMethodName" STRING;
BA_DEF_ SG_ "GenSigStartValue" FLOAT 0 100000000000;
BA_DEF_ SG_ "ISignalName" STRING;
BA_DEF_ SG_ "LongName" STRING;
BA_DEF_ SG_ "SysSignalName" STRING;
BA_DEF_ SG_ "SystemSignalLongSymbol" STRING;
BA_DEF_ BU_ "NWM-Knoten" ENUM  "nein","ja";
BA_DEF_ BU_ "NWM-Stationsadresse" HEX 0 63;
BA_DEF_  "BusType" STRING;
BA_ "NWM-Knoten" BU_ IPD 0;
BA_ "NWM-Stationsadresse" BU_ IPD 0;

BA_ "BusType"   "CAN FD";

BA_ "FrameTriggeringName" BO_ 430 "EPS_CHCANFD_20ms_FrP03";
BA_ "GenMsgCycleTime" BO_ 430 20;
BA_ "GenMsgSendType" BO_ 430 0;
BA_ "GenMsgStartValue" BO_ 430 "007000ffffffffff";
BA_ "PduName" BO_ 430 "EPS_20ms_PDU03";
BA_ "VFrameFormat" BO_ 430 14;
BA_ "FrameTriggeringName" BO_ 1681 "EPS_CHCANFD_CT_Tx";
BA_ "GenMsgSendType" BO_ 1681 1;
BA_ "GenMsgStartValue" BO_ 1681 "0000000000000000";
BA_ "PduName" BO_ 1681 "EPS_CHCANFD_CT_Tx";
BA_ "VFrameFormat" BO_ 1681 14;
BA_ "FrameTriggeringName" BO_ 1252 "EPS_CHCANFD_NM";
BA_ "GenMsgSendType" BO_ 1252 1;
BA_ "GenMsgStartValue" BO_ 1252 "0000000000000000";
BA_ "PduName" BO_ 1252 "NmPDU_CHCANFD_EPS";
BA_ "VFrameFormat" BO_ 1252 14;
BA_ "FrameTriggeringName" BO_ 956 "FVCM_BKPCANFD_100ms_FrP05";
BA_ "GenMsgCycleTime" BO_ 956 100;
BA_ "GenMsgSendType" BO_ 956 0;
BA_ "GenMsgStartValue" BO_ 956 "00000000000000000000000000000000000000000000000000000000000000000000000000000000000000000000000000500000000000000000000000000000";
BA_ "PduName" BO_ 956 "FVCM_100ms_PDU05";
BA_ "VFrameFormat" BO_ 956 14;
BA_ "FrameTriggeringName" BO_ 163 "FVCM_BKPCANFD_10ms_FrP01";
BA_ "GenMsgCycleTime" BO_ 163 10;
BA_ "GenMsgSendType" BO_ 163 0;
BA_ "GenMsgStartValue" BO_ 163 "00007f58801fffffffffffff";
BA_ "PduName" BO_ 163 "FVCM_10ms_PDU01";
BA_ "VFrameFormat" BO_ 163 14;
BA_ "FrameTriggeringName" BO_ 988 "IBS_CHCANFD_100ms_FrP15";
BA_ "GenMsgCycleTime" BO_ 988 100;
BA_ "GenMsgSendType" BO_ 988 0;
BA_ "GenMsgStartValue" BO_ 988 "005000000303ffff";
BA_ "PduName" BO_ 988 "IBS_100ms_PDU15";
BA_ "VFrameFormat" BO_ 988 14;
BA_ "FrameTriggeringName" BO_ 318 "IBS_CHCANFD_10ms_FrP01";
BA_ "GenMsgCycleTime" BO_ 318 10;
BA_ "GenMsgSendType" BO_ 318 0;
BA_ "GenMsgStartValue" BO_ 318 "0000000000000000";
BA_ "PduName" BO_ 318 "IBS_10ms_PDU01";
BA_ "VFrameFormat" BO_ 318 14;
BA_ "FrameTriggeringName" BO_ 319 "IBS_CHCANFD_10ms_FrP02";
BA_ "GenMsgCycleTime" BO_ 319 10;
BA_ "GenMsgSendType" BO_ 319 0;
BA_ "GenMsgStartValue" BO_ 319 "0000000000000000";
BA_ "PduName" BO_ 319 "IBS_10ms_PDU02";
BA_ "VFrameFormat" BO_ 319 14;
BA_ "FrameTriggeringName" BO_ 423 "IBS_CHCANFD_20ms_FrP07";
BA_ "GenMsgCycleTime" BO_ 423 20;
BA_ "GenMsgSendType" BO_ 423 0;
BA_ "GenMsgStartValue" BO_ 423 "0000000000010200";
BA_ "PduName" BO_ 423 "IBS_20ms_PDU07";
BA_ "VFrameFormat" BO_ 423 14;
BA_ "FrameTriggeringName" BO_ 342 "IBS_CHCANFD_20ms_FrP08";
BA_ "GenMsgCycleTime" BO_ 342 20;
BA_ "GenMsgSendType" BO_ 342 0;
BA_ "GenMsgStartValue" BO_ 342 "0000000000000000";
BA_ "PduName" BO_ 342 "IBS_20ms_PDU08";
BA_ "VFrameFormat" BO_ 342 14;
BA_ "FrameTriggeringName" BO_ 329 "IBS_CHCANFD_20ms_FrP09";
BA_ "GenMsgCycleTime" BO_ 329 20;
BA_ "GenMsgSendType" BO_ 329 0;
BA_ "GenMsgStartValue" BO_ 329 "00f0000300000001";
BA_ "PduName" BO_ 329 "IBS_20ms_PDU09";
BA_ "VFrameFormat" BO_ 329 14;
BA_ "FrameTriggeringName" BO_ 425 "IBS_CHCANFD_20ms_FrP11";
BA_ "GenMsgCycleTime" BO_ 425 20;
BA_ "GenMsgSendType" BO_ 425 0;
BA_ "GenMsgStartValue" BO_ 425 "0070000000000000";
BA_ "PduName" BO_ 425 "IBS_20ms_PDU11";
BA_ "VFrameFormat" BO_ 425 14;
BA_ "FrameTriggeringName" BO_ 339 "IBS_CHCANFD_20ms_FrP12";
BA_ "GenMsgCycleTime" BO_ 339 20;
BA_ "GenMsgSendType" BO_ 339 0;
BA_ "GenMsgStartValue" BO_ 339 "00f0c0000000ffff";
BA_ "PduName" BO_ 339 "IBS_20ms_PDU12";
BA_ "VFrameFormat" BO_ 339 14;
BA_ "FrameTriggeringName" BO_ 1272 "IBS_CHCANFD_NM";
BA_ "GenMsgSendType" BO_ 1272 1;
BA_ "GenMsgStartValue" BO_ 1272 "0000000000000000";
BA_ "PduName" BO_ 1272 "NmPDU_CHCANFD_IBS";
BA_ "VFrameFormat" BO_ 1272 14;
BA_ "FrameTriggeringName" BO_ 283 "IBS_SFCANFD_20ms_FrP26";
BA_ "GenMsgCycleTime" BO_ 283 20;
BA_ "GenMsgSendType" BO_ 283 0;
BA_ "GenMsgStartValue" BO_ 283 "0000000000000000";
BA_ "PduName" BO_ 283 "IBS_20ms_PDU26";
BA_ "VFrameFormat" BO_ 283 14;
BA_ "FrameTriggeringName" BO_ 507 "IBS_ZONE_CHCANFD_20ms_FrP08";
BA_ "GenMsgCycleTime" BO_ 507 20;
BA_ "GenMsgSendType" BO_ 507 0;
BA_ "GenMsgStartValue" BO_ 507 "00500000fffffff8";
BA_ "PduName" BO_ 507 "IBS_ZONE_20ms_PDU08";
BA_ "VFrameFormat" BO_ 507 14;
BA_ "FrameTriggeringName" BO_ 382 "ICBAD_BKPCANFD_20ms_FrP07";
BA_ "GenMsgCycleTime" BO_ 382 20;
BA_ "GenMsgSendType" BO_ 382 0;
BA_ "GenMsgStartValue" BO_ 382 "000006b10000f000";
BA_ "PduName" BO_ 382 "ICBAD_20ms_PDU07";
BA_ "VFrameFormat" BO_ 382 14;
BA_ "FrameTriggeringName" BO_ 385 "ICBAD_BKPCANFD_20ms_FrP09";
BA_ "GenMsgCycleTime" BO_ 385 20;
BA_ "GenMsgSendType" BO_ 385 0;
BA_ "GenMsgStartValue" BO_ 385 "000003ffffffffff";
BA_ "PduName" BO_ 385 "ICBAD_20ms_PDU09";
BA_ "VFrameFormat" BO_ 385 14;
BA_ "FrameTriggeringName" BO_ 343 "ICBAD_BKPCANFD_20ms_FrP46";
BA_ "GenMsgCycleTime" BO_ 343 20;
BA_ "GenMsgSendType" BO_ 343 0;
BA_ "GenMsgStartValue" BO_ 343 "0020007f1fff0000";
BA_ "PduName" BO_ 343 "ICBAD_20ms_PDU46";
BA_ "VFrameFormat" BO_ 343 14;
BA_ "FrameTriggeringName" BO_ 102 "ICBAD_CHCANFD_10ms_FrP01";
BA_ "GenMsgCycleTime" BO_ 102 10;
BA_ "GenMsgSendType" BO_ 102 0;
BA_ "GenMsgStartValue" BO_ 102 "00f0f0ffffffff01ffffffffffffffffffffffffffffffff";
BA_ "PduName" BO_ 102 "ICBAD_10ms_PDU01";
BA_ "VFrameFormat" BO_ 102 14;
BA_ "FrameTriggeringName" BO_ 360 "ICBAD_CHCANFD_20ms_FrP13";
BA_ "GenMsgCycleTime" BO_ 360 20;
BA_ "GenMsgSendType" BO_ 360 0;
BA_ "GenMsgStartValue" BO_ 360 "00008000fff08fff";
BA_ "PduName" BO_ 360 "ICBAD_20ms_PDU13";
BA_ "VFrameFormat" BO_ 360 14;
BA_ "FrameTriggeringName" BO_ 1122 "ICBAD_CHCANFD_20ms_FrP16";
BA_ "GenMsgCycleTime" BO_ 1122 20;
BA_ "GenMsgSendType" BO_ 1122 0;
BA_ "GenMsgStartValue" BO_ 1122 "0000000000000000";
BA_ "PduName" BO_ 1122 "ICBAD_20ms_PDU16";
BA_ "VFrameFormat" BO_ 1122 14;
BA_ "FrameTriggeringName" BO_ 474 "ICBAD_CHCANFD_20ms_FrP48";
BA_ "GenMsgCycleTime" BO_ 474 20;
BA_ "GenMsgSendType" BO_ 474 0;
BA_ "GenMsgStartValue" BO_ 474 "001000ffff1fffff";
BA_ "PduName" BO_ 474 "ICBAD_20ms_PDU48";
BA_ "VFrameFormat" BO_ 474 14;
BA_ "FrameTriggeringName" BO_ 47 "ICBAD_CHCANFD_Event_FrS03";
BA_ "GenMsgSendType" BO_ 47 1;
BA_ "GenMsgStartValue" BO_ 47 "00000000000000000000000000000000";
BA_ "PduName" BO_ 47 "ICBAD_Sporadic_PDU03";
BA_ "VFrameFormat" BO_ 47 14;
BA_ "FrameTriggeringName" BO_ 424 "ICBAD_RZCUCANFD_20ms_FrP12";
BA_ "GenMsgCycleTime" BO_ 424 20;
BA_ "GenMsgSendType" BO_ 424 0;
BA_ "GenMsgStartValue" BO_ 424 "00e01f00ffffffff";
BA_ "PduName" BO_ 424 "ICBAD_20ms_PDU12";
BA_ "VFrameFormat" BO_ 424 14;
BA_ "FrameTriggeringName" BO_ 520 "ICBAD_RZCUCANFD_50ms_FrP21";
BA_ "GenMsgCycleTime" BO_ 520 50;
BA_ "GenMsgSendType" BO_ 520 0;
BA_ "GenMsgStartValue" BO_ 520 "000000000000000000000000000000000000000000000000";
BA_ "PduName" BO_ 520 "ICBAD_50ms_PDU21";
BA_ "VFrameFormat" BO_ 520 14;

BA_ "CompuMethodName" SG_ 430 EPS_20ms_Group03_CRC "EPS_20ms_Group03_CRC";
BA_ "ISignalName" SG_ 430 EPS_20ms_Group03_CRC "IEPS_20ms_Group03_CRC";
BA_ "SysSignalName" SG_ 430 EPS_20ms_Group03_CRC "EPS_20ms_Group03_CRC";
BA_ "CompuMethodName" SG_ 430 EPS_20ms_Group03_RC "EPS_20ms_Group03_RC";
BA_ "ISignalName" SG_ 430 EPS_20ms_Group03_RC "IEPS_20ms_Group03_RC";
BA_ "SysSignalName" SG_ 430 EPS_20ms_Group03_RC "EPS_20ms_Group03_RC";
BA_ "CompuMethodName" SG_ 430 EPSAPASts "EPSAPASts";
BA_ "GenSigStartValue" SG_ 430 EPSAPASts 7;
BA_ "ISignalName" SG_ 430 EPSAPASts "IEPSAPASts";
BA_ "LongName" SG_ 430 EPSAPASts "Electric Power Steering Advanced Park Assist Status";
BA_ "SysSignalName" SG_ 430 EPSAPASts "EPSAPASts";
BA_ "CompuMethodName" SG_ 430 EPSAPAInh "EPSAPAInh";
BA_ "ISignalName" SG_ 430 EPSAPAInh "IEPSAPAInh";
BA_ "LongName" SG_ 430 EPSAPAInh "Electric Power Steering Advanced Park Assist Inhibit";
BA_ "SysSignalName" SG_ 430 EPSAPAInh "EPSAPAInh";
BA_ "CompuMethodName" SG_ 430 EPS_20ms_Group03_Reserved1 "EPS_20ms_Group03_Reserved1";
BA_ "GenSigStartValue" SG_ 430 EPS_20ms_Group03_Reserved1 255;
BA_ "ISignalName" SG_ 430 EPS_20ms_Group03_Reserved1 "IEPS_20ms_Group03_Reserved1";
BA_ "SysSignalName" SG_ 430 EPS_20ms_Group03_Reserved1 "EPS_20ms_Group03_Reserved1";
BA_ "CompuMethodName" SG_ 430 EPS_20ms_Group03_Reserved2 "EPS_20ms_Group03_Reserved2";
BA_ "GenSigStartValue" SG_ 430 EPS_20ms_Group03_Reserved2 255;
BA_ "ISignalName" SG_ 430 EPS_20ms_Group03_Reserved2 "IEPS_20ms_Group03_Reserved2";
BA_ "SysSignalName" SG_ 430 EPS_20ms_Group03_Reserved2 "EPS_20ms_Group03_Reserved2";
BA_ "CompuMethodName" SG_ 430 EPS_20ms_Group03_Reserved3 "EPS_20ms_Group03_Reserved3";
BA_ "GenSigStartValue" SG_ 430 EPS_20ms_Group03_Reserved3 255;
BA_ "ISignalName" SG_ 430 EPS_20ms_Group03_Reserved3 "IEPS_20ms_Group03_Reserved3";
BA_ "SysSignalName" SG_ 430 EPS_20ms_Group03_Reserved3 "EPS_20ms_Group03_Reserved3";
BA_ "CompuMethodName" SG_ 430 EPS_20ms_Group03_Reserved4 "EPS_20ms_Group03_Reserved4";
BA_ "GenSigStartValue" SG_ 430 EPS_20ms_Group03_Reserved4 255;
BA_ "ISignalName" SG_ 430 EPS_20ms_Group03_Reserved4 "IEPS_20ms_Group03_Reserved4";
BA_ "SysSignalName" SG_ 430 EPS_20ms_Group03_Reserved4 "EPS_20ms_Group03_Reserved4";
BA_ "CompuMethodName" SG_ 430 EPS_20ms_Group03_Reserved5 "EPS_20ms_Group03_Reserved5";
BA_ "GenSigStartValue" SG_ 430 EPS_20ms_Group03_Reserved5 255;
BA_ "ISignalName" SG_ 430 EPS_20ms_Group03_Reserved5 "IEPS_20ms_Group03_Reserved5";
BA_ "SysSignalName" SG_ 430 EPS_20ms_Group03_Reserved5 "EPS_20ms_Group03_Reserved5";
BA_ "CompuMethodName" SG_ 1681 EPSCTTX "EPSCTTX";
BA_ "ISignalName" SG_ 1681 EPSCTTX "IEPSCTTX";
BA_ "LongName" SG_ 1681 EPSCTTX "Eps Ct Tx";
BA_ "SysSignalName" SG_ 1681 EPSCTTX "EPSCTTX";
BA_ "CompuMethodName" SG_ 1252 EPS_NM_BSMtoRMS_CHCANFD "EPS_NM_BSMtoRMS_CHCANFD";
BA_ "ISignalName" SG_ 1252 EPS_NM_BSMtoRMS_CHCANFD "IEPS_NM_BSMtoRMS_CHCANFD";
BA_ "LongName" SG_ 1252 EPS_NM_BSMtoRMS_CHCANFD "EPS_NM_BSMtoRMS_CHCANFD";
BA_ "SysSignalName" SG_ 1252 EPS_NM_BSMtoRMS_CHCANFD "EPS_NM_BSMtoRMS_CHCANFD";
BA_ "CompuMethodName" SG_ 1252 EPS_NM_PBSMtoRMS_CHCANFD "EPS_NM_PBSMtoRMS_CHCANFD";
BA_ "ISignalName" SG_ 1252 EPS_NM_PBSMtoRMS_CHCANFD "IEPS_NM_PBSMtoRMS_CHCANFD";
BA_ "LongName" SG_ 1252 EPS_NM_PBSMtoRMS_CHCANFD "EPS_NM_PBSMtoRMS_CHCANFD";
BA_ "SysSignalName" SG_ 1252 EPS_NM_PBSMtoRMS_CHCANFD "EPS_NM_PBSMtoRMS_CHCANFD";
BA_ "CompuMethodName" SG_ 1252 EPS_NM_RMStoNOS_CHCANFD "EPS_NM_RMStoNOS_CHCANFD";
BA_ "ISignalName" SG_ 1252 EPS_NM_RMStoNOS_CHCANFD "IEPS_NM_RMStoNOS_CHCANFD";
BA_ "LongName" SG_ 1252 EPS_NM_RMStoNOS_CHCANFD "EPS_NM_RMStoNOS_CHCANFD";
BA_ "SysSignalName" SG_ 1252 EPS_NM_RMStoNOS_CHCANFD "EPS_NM_RMStoNOS_CHCANFD";
BA_ "CompuMethodName" SG_ 1252 EPS_NM_RSStoNOS_CHCANFD "EPS_NM_RSStoNOS_CHCANFD";
BA_ "ISignalName" SG_ 1252 EPS_NM_RSStoNOS_CHCANFD "IEPS_NM_RSStoNOS_CHCANFD";
BA_ "LongName" SG_ 1252 EPS_NM_RSStoNOS_CHCANFD "EPS_NM_RSStoNOS_CHCANFD";
BA_ "SysSignalName" SG_ 1252 EPS_NM_RSStoNOS_CHCANFD "EPS_NM_RSStoNOS_CHCANFD";
BA_ "CompuMethodName" SG_ 1252 EPS_NM_RSStoRMS_CHCANFD "EPS_NM_RSStoRMS_CHCANFD";
BA_ "ISignalName" SG_ 1252 EPS_NM_RSStoRMS_CHCANFD "IEPS_NM_RSStoRMS_CHCANFD";
BA_ "LongName" SG_ 1252 EPS_NM_RSStoRMS_CHCANFD "EPS_NM_RSStoRMS_CHCANFD";
BA_ "SysSignalName" SG_ 1252 EPS_NM_RSStoRMS_CHCANFD "EPS_NM_RSStoRMS_CHCANFD";
BA_ "CompuMethodName" SG_ 1252 EPS_NM_NOStoRMS_CHCANFD "EPS_NM_NOStoRMS_CHCANFD";
BA_ "ISignalName" SG_ 1252 EPS_NM_NOStoRMS_CHCANFD "IEPS_NM_NOStoRMS_CHCANFD";
BA_ "LongName" SG_ 1252 EPS_NM_NOStoRMS_CHCANFD "EPS_NM_NOStoRMS_CHCANFD";
BA_ "SysSignalName" SG_ 1252 EPS_NM_NOStoRMS_CHCANFD "EPS_NM_NOStoRMS_CHCANFD";
BA_ "CompuMethodName" SG_ 1252 EPS_NM_NOSSta_CHCANFD "EPS_NM_NOSSta_CHCANFD";
BA_ "ISignalName" SG_ 1252 EPS_NM_NOSSta_CHCANFD "IEPS_NM_NOSSta_CHCANFD";
BA_ "LongName" SG_ 1252 EPS_NM_NOSSta_CHCANFD "EPS_NM_NOSSta_CHCANFD";
BA_ "SysSignalName" SG_ 1252 EPS_NM_NOSSta_CHCANFD "EPS_NM_NOSSta_CHCANFD";
BA_ "CompuMethodName" SG_ 1252 EPS_NM_RMSSta_CHCANFD "EPS_NM_RMSSta_CHCANFD";
BA_ "ISignalName" SG_ 1252 EPS_NM_RMSSta_CHCANFD "IEPS_NM_RMSSta_CHCANFD";
BA_ "LongName" SG_ 1252 EPS_NM_RMSSta_CHCANFD "EPS_NM_RMSSta_CHCANFD";
BA_ "SysSignalName" SG_ 1252 EPS_NM_RMSSta_CHCANFD "EPS_NM_RMSSta_CHCANFD";
BA_ "CompuMethodName" SG_ 1252 EPS_NWI_CHCANFD "EPS_NWI_CHCANFD";
BA_ "ISignalName" SG_ 1252 EPS_NWI_CHCANFD "IEPS_NWI_CHCANFD";
BA_ "LongName" SG_ 1252 EPS_NWI_CHCANFD "EPS CHCANFD Network_Wakeup_Indication";
BA_ "SysSignalName" SG_ 1252 EPS_NWI_CHCANFD "EPS_NWI_CHCANFD";
BA_ "CompuMethodName" SG_ 1252 EPS_NOI_CHCANFD "EPS_NOI_CHCANFD";
BA_ "ISignalName" SG_ 1252 EPS_NOI_CHCANFD "IEPS_NOI_CHCANFD";
BA_ "LongName" SG_ 1252 EPS_NOI_CHCANFD "EPS CHCANFD Network Operation Indication";
BA_ "SysSignalName" SG_ 1252 EPS_NOI_CHCANFD "EPS_NOI_CHCANFD";
BA_ "CompuMethodName" SG_ 1252 EPS_NKI_CHCANFD "EPS_NKI_CHCANFD";
BA_ "ISignalName" SG_ 1252 EPS_NKI_CHCANFD "IEPS_NKI_CHCANFD";
BA_ "LongName" SG_ 1252 EPS_NKI_CHCANFD "EPS CHCANFD Network Keep Indication";
BA_ "SysSignalName" SG_ 1252 EPS_NKI_CHCANFD "EPS_NKI_CHCANFD";
BA_ "CompuMethodName" SG_ 956 PilotSysMsg "PilotSysMsg";
BA_ "ISignalName" SG_ 956 PilotSysMsg "IPilotSysMsg";
BA_ "LongName" SG_ 956 PilotSysMsg "Pilot System Message";
BA_ "SysSignalName" SG_ 956 PilotSysMsg "PilotSysMsg";
BA_ "CompuMethodName" SG_ 956 Lane0_C0 "Lane0_C0";
BA_ "ISignalName" SG_ 956 Lane0_C0 "ILane0_C0";
BA_ "LongName" SG_ 956 Lane0_C0 "Lane_0_Curve_Parameter_C0";
BA_ "SysSignalName" SG_ 956 Lane0_C0 "Lane0_C0";
BA_ "CompuMethodName" SG_ 956 Lane0_C1 "Lane0_C1";
BA_ "ISignalName" SG_ 956 Lane0_C1 "ILane0_C1";
BA_ "LongName" SG_ 956 Lane0_C1 "Lane_0_Curve_Parameter_C1";
BA_ "SysSignalName" SG_ 956 Lane0_C1 "Lane0_C1";
BA_ "CompuMethodName" SG_ 956 Lane0_C2 "Lane0_C2";
BA_ "ISignalName" SG_ 956 Lane0_C2 "ILane0_C2";
BA_ "LongName" SG_ 956 Lane0_C2 "Lane_0_Curve_Parameter_C2";
BA_ "SysSignalName" SG_ 956 Lane0_C2 "Lane0_C2";
BA_ "CompuMethodName" SG_ 956 Lane0_C3 "Lane0_C3";
BA_ "ISignalName" SG_ 956 Lane0_C3 "ILane0_C3";
BA_ "LongName" SG_ 956 Lane0_C3 "Lane_0_Curve_Parameter_C3";
BA_ "SysSignalName" SG_ 956 Lane0_C3 "Lane0_C3";
BA_ "CompuMethodName" SG_ 956 Lane1_C0 "Lane1_C0";
BA_ "ISignalName" SG_ 956 Lane1_C0 "ILane1_C0";
BA_ "LongName" SG_ 956 Lane1_C0 "Lane_1_Curve_Parameter_C0";
BA_ "SysSignalName" SG_ 956 Lane1_C0 "Lane1_C0";
BA_ "CompuMethodName" SG_ 956 Lane1_C1 "Lane1_C1";
BA_ "ISignalName" SG_ 956 Lane1_C1 "ILane1_C1";
BA_ "LongName" SG_ 956 Lane1_C1 "Lane_1_Curve_Parameter_C1";
BA_ "SysSignalName" SG_ 956 Lane1_C1 "Lane1_C1";
BA_ "CompuMethodName" SG_ 956 Lane1_C2 "Lane1_C2";
BA_ "ISignalName" SG_ 956 Lane1_C2 "ILane1_C2";
BA_ "LongName" SG_ 956 Lane1_C2 "Lane_1_Curve_Parameter_C2";
BA_ "SysSignalName" SG_ 956 Lane1_C2 "Lane1_C2";
BA_ "CompuMethodName" SG_ 956 Lane1_C3 "Lane1_C3";
BA_ "ISignalName" SG_ 956 Lane1_C3 "ILane1_C3";
BA_ "LongName" SG_ 956 Lane1_C3 "Lane_1_Curve_Parameter_C3";
BA_ "SysSignalName" SG_ 956 Lane1_C3 "Lane1_C3";
BA_ "CompuMethodName" SG_ 956 Lane2_C0 "Lane2_C0";
BA_ "ISignalName" SG_ 956 Lane2_C0 "ILane2_C0";
BA_ "LongName" SG_ 956 Lane2_C0 "Lane_2_Curve_Parameter_C0";
BA_ "SysSignalName" SG_ 956 Lane2_C0 "Lane2_C0";
BA_ "CompuMethodName" SG_ 956 Lane2_C1 "Lane2_C1";
BA_ "ISignalName" SG_ 956 Lane2_C1 "ILane2_C1";
BA_ "LongName" SG_ 956 Lane2_C1 "Lane_2_Curve_Parameter_C1";
BA_ "SysSignalName" SG_ 956 Lane2_C1 "Lane2_C1";
BA_ "CompuMethodName" SG_ 956 Lane2_C2 "Lane2_C2";
BA_ "ISignalName" SG_ 956 Lane2_C2 "ILane2_C2";
BA_ "LongName" SG_ 956 Lane2_C2 "Lane_2_Curve_Parameter_C2";
BA_ "SysSignalName" SG_ 956 Lane2_C2 "Lane2_C2";
BA_ "CompuMethodName" SG_ 956 Lane2_C3 "Lane2_C3";
BA_ "ISignalName" SG_ 956 Lane2_C3 "ILane2_C3";
BA_ "LongName" SG_ 956 Lane2_C3 "Lane_2_Curve_Parameter_C3";
BA_ "SysSignalName" SG_ 956 Lane2_C3 "Lane2_C3";
BA_ "CompuMethodName" SG_ 956 Lane3_C0 "Lane3_C0";
BA_ "ISignalName" SG_ 956 Lane3_C0 "ILane3_C0";
BA_ "LongName" SG_ 956 Lane3_C0 "Lane_3_Curve_Parameter_C0";
BA_ "SysSignalName" SG_ 956 Lane3_C0 "Lane3_C0";
BA_ "CompuMethodName" SG_ 956 Lane3_C1 "Lane3_C1";
BA_ "ISignalName" SG_ 956 Lane3_C1 "ILane3_C1";
BA_ "LongName" SG_ 956 Lane3_C1 "Lane_3_Curve_Parameter_C1";
BA_ "SysSignalName" SG_ 956 Lane3_C1 "Lane3_C1";
BA_ "CompuMethodName" SG_ 956 Lane3_C2 "Lane3_C2";
BA_ "ISignalName" SG_ 956 Lane3_C2 "ILane3_C2";
BA_ "LongName" SG_ 956 Lane3_C2 "Lane_3_Curve_Parameter_C2";
BA_ "SysSignalName" SG_ 956 Lane3_C2 "Lane3_C2";
BA_ "CompuMethodName" SG_ 956 Lane3_C3 "Lane3_C3";
BA_ "ISignalName" SG_ 956 Lane3_C3 "ILane3_C3";
BA_ "LongName" SG_ 956 Lane3_C3 "Lane_3_Curve_Parameter_C3";
BA_ "SysSignalName" SG_ 956 Lane3_C3 "Lane3_C3";
BA_ "CompuMethodName" SG_ 956 Lane0_ViewRangeStart "Lane0_ViewRangeStart";
BA_ "ISignalName" SG_ 956 Lane0_ViewRangeStart "ILane0_ViewRangeStart";
BA_ "LongName" SG_ 956 Lane0_ViewRangeStart "Lane_0_Curve_Longitudinal_Distance_Start";
BA_ "SysSignalName" SG_ 956 Lane0_ViewRangeStart "Lane0_ViewRangeStart";
BA_ "CompuMethodName" SG_ 956 Lane1_ViewRangeStart "Lane1_ViewRangeStart";
BA_ "ISignalName" SG_ 956 Lane1_ViewRangeStart "ILane1_ViewRangeStart";
BA_ "LongName" SG_ 956 Lane1_ViewRangeStart "Lane_1_Curve_Longitudinal_Distance_Start";
BA_ "SysSignalName" SG_ 956 Lane1_ViewRangeStart "Lane1_ViewRangeStart";
BA_ "CompuMethodName" SG_ 956 Lane2_ViewRangeStart "Lane2_ViewRangeStart";
BA_ "ISignalName" SG_ 956 Lane2_ViewRangeStart "ILane2_ViewRangeStart";
BA_ "LongName" SG_ 956 Lane2_ViewRangeStart "Lane_2_Curve_Longitudinal_Distance_Start";
BA_ "SysSignalName" SG_ 956 Lane2_ViewRangeStart "Lane2_ViewRangeStart";
BA_ "CompuMethodName" SG_ 956 Lane3_ViewRangeStart "Lane3_ViewRangeStart";
BA_ "ISignalName" SG_ 956 Lane3_ViewRangeStart "ILane3_ViewRangeStart";
BA_ "LongName" SG_ 956 Lane3_ViewRangeStart "Lane_3_Curve_Longitudinal_Distance_Start";
BA_ "SysSignalName" SG_ 956 Lane3_ViewRangeStart "Lane3_ViewRangeStart";
BA_ "CompuMethodName" SG_ 956 Lane0_ViewRangeEnd "Lane0_ViewRangeEnd";
BA_ "ISignalName" SG_ 956 Lane0_ViewRangeEnd "ILane0_ViewRangeEnd";
BA_ "LongName" SG_ 956 Lane0_ViewRangeEnd "Lane_0_Curve_Longitudinal_Distance_Stop";
BA_ "SysSignalName" SG_ 956 Lane0_ViewRangeEnd "Lane0_ViewRangeEnd";
BA_ "CompuMethodName" SG_ 956 Lane1_ViewRangeEnd "Lane1_ViewRangeEnd";
BA_ "ISignalName" SG_ 956 Lane1_ViewRangeEnd "ILane1_ViewRangeEnd";
BA_ "LongName" SG_ 956 Lane1_ViewRangeEnd "Lane_1_Curve_Longitudinal_Distance_Stop";
BA_ "SysSignalName" SG_ 956 Lane1_ViewRangeEnd "Lane1_ViewRangeEnd";
BA_ "CompuMethodName" SG_ 956 Lane0_ExistPrblty "Lane0_ExistPrblty";
BA_ "ISignalName" SG_ 956 Lane0_ExistPrblty "ILane0_ExistPrblty";
BA_ "LongName" SG_ 956 Lane0_ExistPrblty "Lane_0_Exist_Probability";
BA_ "SysSignalName" SG_ 956 Lane0_ExistPrblty "Lane0_ExistPrblty";
BA_ "CompuMethodName" SG_ 956 Lane2_ViewRangeEnd "Lane2_ViewRangeEnd";
BA_ "ISignalName" SG_ 956 Lane2_ViewRangeEnd "ILane2_ViewRangeEnd";
BA_ "LongName" SG_ 956 Lane2_ViewRangeEnd "Lane_2_Curve_Longitudinal_Distance_Stop";
BA_ "SysSignalName" SG_ 956 Lane2_ViewRangeEnd "Lane2_ViewRangeEnd";
BA_ "CompuMethodName" SG_ 956 Lane3_ViewRangeEnd "Lane3_ViewRangeEnd";
BA_ "ISignalName" SG_ 956 Lane3_ViewRangeEnd "ILane3_ViewRangeEnd";
BA_ "LongName" SG_ 956 Lane3_ViewRangeEnd "Lane_3_Curve_Longitudinal_Distance_Stop";
BA_ "SysSignalName" SG_ 956 Lane3_ViewRangeEnd "Lane3_ViewRangeEnd";
BA_ "CompuMethodName" SG_ 956 Lane1_ExistPrblty "Lane1_ExistPrblty";
BA_ "ISignalName" SG_ 956 Lane1_ExistPrblty "ILane1_ExistPrblty";
BA_ "LongName" SG_ 956 Lane1_ExistPrblty "Lane_1_Exist_Probability";
BA_ "SysSignalName" SG_ 956 Lane1_ExistPrblty "Lane1_ExistPrblty";
BA_ "CompuMethodName" SG_ 956 Lane0_Part0_SyncFrameIndex "Lane0_Part0_SyncFrameIndex";
BA_ "ISignalName" SG_ 956 Lane0_Part0_SyncFrameIndex "ILane0_Part0_SyncFrameIndex";
BA_ "LongName" SG_ 956 Lane0_Part0_SyncFrameIndex "Lane_0_Synchronize_Counter";
BA_ "SysSignalName" SG_ 956 Lane0_Part0_SyncFrameIndex "Lane0_Part0_SyncFrameIndex";
BA_ "CompuMethodName" SG_ 956 Lane0_ID "Lane0_ID";
BA_ "ISignalName" SG_ 956 Lane0_ID "ILane0_ID";
BA_ "LongName" SG_ 956 Lane0_ID "Lane_0_Identifier";
BA_ "SysSignalName" SG_ 956 Lane0_ID "Lane0_ID";
BA_ "CompuMethodName" SG_ 956 Lane1_Part0_SyncFrameIndex "Lane1_Part0_SyncFrameIndex";
BA_ "ISignalName" SG_ 956 Lane1_Part0_SyncFrameIndex "ILane1_Part0_SyncFrameIndex";
BA_ "LongName" SG_ 956 Lane1_Part0_SyncFrameIndex "Lane_1_Synchronize_Counter";
BA_ "SysSignalName" SG_ 956 Lane1_Part0_SyncFrameIndex "Lane1_Part0_SyncFrameIndex";
BA_ "CompuMethodName" SG_ 956 Lane1_ID "Lane1_ID";
BA_ "ISignalName" SG_ 956 Lane1_ID "ILane1_ID";
BA_ "LongName" SG_ 956 Lane1_ID "Lane_1_Identifier";
BA_ "SysSignalName" SG_ 956 Lane1_ID "Lane1_ID";
BA_ "CompuMethodName" SG_ 956 Lane2_Part0_SyncFrameIndex "Lane2_Part0_SyncFrameIndex";
BA_ "ISignalName" SG_ 956 Lane2_Part0_SyncFrameIndex "ILane2_Part0_SyncFrameIndex";
BA_ "LongName" SG_ 956 Lane2_Part0_SyncFrameIndex "Lane_2_Synchronize_Counter";
BA_ "SysSignalName" SG_ 956 Lane2_Part0_SyncFrameIndex "Lane2_Part0_SyncFrameIndex";
BA_ "CompuMethodName" SG_ 956 Lane2_ID "Lane2_ID";
BA_ "ISignalName" SG_ 956 Lane2_ID "ILane2_ID";
BA_ "LongName" SG_ 956 Lane2_ID "Lane_2_Identifier";
BA_ "SysSignalName" SG_ 956 Lane2_ID "Lane2_ID";
BA_ "CompuMethodName" SG_ 956 Lane3_Part0_SyncFrameIndex "Lane3_Part0_SyncFrameIndex";
BA_ "ISignalName" SG_ 956 Lane3_Part0_SyncFrameIndex "ILane3_Part0_SyncFrameIndex";
BA_ "LongName" SG_ 956 Lane3_Part0_SyncFrameIndex "Lane_3_Synchronize_Counter";
BA_ "SysSignalName" SG_ 956 Lane3_Part0_SyncFrameIndex "Lane3_Part0_SyncFrameIndex";
BA_ "CompuMethodName" SG_ 956 Lane3_ID "Lane3_ID";
BA_ "ISignalName" SG_ 956 Lane3_ID "ILane3_ID";
BA_ "LongName" SG_ 956 Lane3_ID "Lane_3_Identifier";
BA_ "SysSignalName" SG_ 956 Lane3_ID "Lane3_ID";
BA_ "CompuMethodName" SG_ 956 TLRMsgReq "TLRMsgReq";
BA_ "ISignalName" SG_ 956 TLRMsgReq "ITLRMsgReq";
BA_ "LongName" SG_ 956 TLRMsgReq "Traffic_lights_recognition_Message_Request";
BA_ "SysSignalName" SG_ 956 TLRMsgReq "TLRMsgReq";
BA_ "CompuMethodName" SG_ 956 Lane0_MarkerColor "Lane0_MarkerColor";
BA_ "ISignalName" SG_ 956 Lane0_MarkerColor "ILane0_MarkerColor";
BA_ "LongName" SG_ 956 Lane0_MarkerColor "Lane_0_Line_Color";
BA_ "SysSignalName" SG_ 956 Lane0_MarkerColor "Lane0_MarkerColor";
BA_ "CompuMethodName" SG_ 956 Lane0_location "Lane0_location";
BA_ "ISignalName" SG_ 956 Lane0_location "ILane0_location";
BA_ "LongName" SG_ 956 Lane0_location "Lane_0_Position";
BA_ "SysSignalName" SG_ 956 Lane0_location "Lane0_location";
BA_ "CompuMethodName" SG_ 956 TLRSysSts "TLRSysSts";
BA_ "ISignalName" SG_ 956 TLRSysSts "ITLRSysSts";
BA_ "LongName" SG_ 956 TLRSysSts "Traffic_lights_recognition_System_Status";
BA_ "SysSignalName" SG_ 956 TLRSysSts "TLRSysSts";
BA_ "CompuMethodName" SG_ 956 Lane1_location "Lane1_location";
BA_ "ISignalName" SG_ 956 Lane1_location "ILane1_location";
BA_ "LongName" SG_ 956 Lane1_location "Lane_1_Position";
BA_ "SysSignalName" SG_ 956 Lane1_location "Lane1_location";
BA_ "CompuMethodName" SG_ 956 Lane0_MarkerType "Lane0_MarkerType";
BA_ "ISignalName" SG_ 956 Lane0_MarkerType "ILane0_MarkerType";
BA_ "LongName" SG_ 956 Lane0_MarkerType "Lane_0_Marker_Type";
BA_ "SysSignalName" SG_ 956 Lane0_MarkerType "Lane0_MarkerType";
BA_ "CompuMethodName" SG_ 956 Lane1_MarkerType "Lane1_MarkerType";
BA_ "ISignalName" SG_ 956 Lane1_MarkerType "ILane1_MarkerType";
BA_ "LongName" SG_ 956 Lane1_MarkerType "Lane_1_Marker_Type";
BA_ "SysSignalName" SG_ 956 Lane1_MarkerType "Lane1_MarkerType";
BA_ "CompuMethodName" SG_ 956 Lane1_MarkerColor "Lane1_MarkerColor";
BA_ "ISignalName" SG_ 956 Lane1_MarkerColor "ILane1_MarkerColor";
BA_ "LongName" SG_ 956 Lane1_MarkerColor "Lane_1_Line_Color";
BA_ "SysSignalName" SG_ 956 Lane1_MarkerColor "Lane1_MarkerColor";
BA_ "CompuMethodName" SG_ 956 Lane2_ExistPrblty "Lane2_ExistPrblty";
BA_ "ISignalName" SG_ 956 Lane2_ExistPrblty "ILane2_ExistPrblty";
BA_ "LongName" SG_ 956 Lane2_ExistPrblty "Lane_2_Exist_Probability";
BA_ "SysSignalName" SG_ 956 Lane2_ExistPrblty "Lane2_ExistPrblty";
BA_ "CompuMethodName" SG_ 956 Lane2_MarkerColor "Lane2_MarkerColor";
BA_ "ISignalName" SG_ 956 Lane2_MarkerColor "ILane2_MarkerColor";
BA_ "LongName" SG_ 956 Lane2_MarkerColor "Lane_2_Line_Color";
BA_ "SysSignalName" SG_ 956 Lane2_MarkerColor "Lane2_MarkerColor";
BA_ "CompuMethodName" SG_ 956 Lane2_location "Lane2_location";
BA_ "ISignalName" SG_ 956 Lane2_location "ILane2_location";
BA_ "LongName" SG_ 956 Lane2_location "Lane_2_Position";
BA_ "SysSignalName" SG_ 956 Lane2_location "Lane2_location";
BA_ "CompuMethodName" SG_ 956 Lane3_location "Lane3_location";
BA_ "ISignalName" SG_ 956 Lane3_location "ILane3_location";
BA_ "LongName" SG_ 956 Lane3_location "Lane_3_Position";
BA_ "SysSignalName" SG_ 956 Lane3_location "Lane3_location";
BA_ "CompuMethodName" SG_ 956 Lane2_MarkerType "Lane2_MarkerType";
BA_ "ISignalName" SG_ 956 Lane2_MarkerType "ILane2_MarkerType";
BA_ "LongName" SG_ 956 Lane2_MarkerType "Lane_2_Marker_Type";
BA_ "SysSignalName" SG_ 956 Lane2_MarkerType "Lane2_MarkerType";
BA_ "CompuMethodName" SG_ 956 Lane3_ExistPrblty "Lane3_ExistPrblty";
BA_ "ISignalName" SG_ 956 Lane3_ExistPrblty "ILane3_ExistPrblty";
BA_ "LongName" SG_ 956 Lane3_ExistPrblty "Lane_3_Exist_Probability";
BA_ "SysSignalName" SG_ 956 Lane3_ExistPrblty "Lane3_ExistPrblty";
BA_ "CompuMethodName" SG_ 956 Lane3_MarkerType "Lane3_MarkerType";
BA_ "ISignalName" SG_ 956 Lane3_MarkerType "ILane3_MarkerType";
BA_ "LongName" SG_ 956 Lane3_MarkerType "Lane_3_Marker_Type";
BA_ "SysSignalName" SG_ 956 Lane3_MarkerType "Lane3_MarkerType";
BA_ "CompuMethodName" SG_ 956 Lane3_MarkerColor "Lane3_MarkerColor";
BA_ "ISignalName" SG_ 956 Lane3_MarkerColor "ILane3_MarkerColor";
BA_ "LongName" SG_ 956 Lane3_MarkerColor "Lane_3_Line_Color";
BA_ "SysSignalName" SG_ 956 Lane3_MarkerColor "Lane3_MarkerColor";
BA_ "CompuMethodName" SG_ 956 TLRWarning "TLRWarning";
BA_ "ISignalName" SG_ 956 TLRWarning "ITLRWarning";
BA_ "LongName" SG_ 956 TLRWarning "Traffic_lights_recognition_Warning";
BA_ "SysSignalName" SG_ 956 TLRWarning "TLRWarning";
BA_ "CompuMethodName" SG_ 956 TLRMdSwDspCmd "TLRMdSwDspCmd";
BA_ "ISignalName" SG_ 956 TLRMdSwDspCmd "ITLRMdSwDspCmd";
BA_ "LongName" SG_ 956 TLRMdSwDspCmd "Traffic_lights_recognition_Mode_Switch_Display_Command";
BA_ "SysSignalName" SG_ 956 TLRMdSwDspCmd "TLRMdSwDspCmd";
BA_ "CompuMethodName" SG_ 956 SpdLmtOfstSetResp "SpdLmtOfstSetResp";
BA_ "GenSigStartValue" SG_ 956 SpdLmtOfstSetResp 20;
BA_ "ISignalName" SG_ 956 SpdLmtOfstSetResp "ISpdLmtOfstSetResp";
BA_ "LongName" SG_ 956 SpdLmtOfstSetResp "Speed Limit Offset Set Response";
BA_ "SysSignalName" SG_ 956 SpdLmtOfstSetResp "SpdLmtOfstSetResp";
BA_ "CompuMethodName" SG_ 956 ACCDetObjHdngAng "ACCDetObjHdngAng";
BA_ "ISignalName" SG_ 956 ACCDetObjHdngAng "IACCDetObjHdngAng";
BA_ "LongName" SG_ 956 ACCDetObjHdngAng "Adaptive Cruise Control Detected Object Heading Angle";
BA_ "SysSignalName" SG_ 956 ACCDetObjHdngAng "ACCDetObjHdngAng";
BA_ "CompuMethodName" SG_ 956 CCSpdVcCmdCnfm "CCSpdVcCmdCnfm";
BA_ "ISignalName" SG_ 956 CCSpdVcCmdCnfm "ICCSpdVcCmdCnfm";
BA_ "LongName" SG_ 956 CCSpdVcCmdCnfm "Cruise_Control_Speed_Voice_Command_Confirm";
BA_ "SysSignalName" SG_ 956 CCSpdVcCmdCnfm "CCSpdVcCmdCnfm";
BA_ "CompuMethodName" SG_ 163 FVCM_10ms_Group01_CRC "FVCM_10ms_Group01_CRC";
BA_ "ISignalName" SG_ 163 FVCM_10ms_Group01_CRC "IFVCM_10ms_Group01_CRC";
BA_ "LongName" SG_ 163 FVCM_10ms_Group01_CRC "FVCM_10ms_Group01_CRC";
BA_ "SysSignalName" SG_ 163 FVCM_10ms_Group01_CRC "FVCM_10ms_Group01_CRC";
BA_ "CompuMethodName" SG_ 163 FVCM_10ms_Group01_RC "FVCM_10ms_Group01_RC";
BA_ "ISignalName" SG_ 163 FVCM_10ms_Group01_RC "IFVCM_10ms_Group01_RC";
BA_ "LongName" SG_ 163 FVCM_10ms_Group01_RC "FVCM_10ms_Group01_RC";
BA_ "SysSignalName" SG_ 163 FVCM_10ms_Group01_RC "FVCM_10ms_Group01_RC";
BA_ "CompuMethodName" SG_ 163 LKAReqToqSts "LKAReqToqSts";
BA_ "ISignalName" SG_ 163 LKAReqToqSts "ILKAReqToqSts";
BA_ "LongName" SG_ 163 LKAReqToqSts "Lane_Keeping_Assist_Required_Torque_Status";
BA_ "SysSignalName" SG_ 163 LKAReqToqSts "LKAReqToqSts";
BA_ "CompuMethodName" SG_ 163 LKAReqAngSts "LKAReqAngSts";
BA_ "ISignalName" SG_ 163 LKAReqAngSts "ILKAReqAngSts";
BA_ "LongName" SG_ 163 LKAReqAngSts "Lane_Keeping_Assist_Required_Angle_Status";
BA_ "SysSignalName" SG_ 163 LKAReqAngSts "LKAReqAngSts";
BA_ "CompuMethodName" SG_ 163 LKAReqAng "LKAReqAng";
BA_ "GenSigStartValue" SG_ 163 LKAReqAng 32600;
BA_ "ISignalName" SG_ 163 LKAReqAng "ILKAReqAng";
BA_ "LongName" SG_ 163 LKAReqAng "Lane_Keeping_Assist_Required_Angle";
BA_ "SysSignalName" SG_ 163 LKAReqAng "LKAReqAng";
BA_ "CompuMethodName" SG_ 163 LKAReqToq "LKAReqToq";
BA_ "GenSigStartValue" SG_ 163 LKAReqToq 1024;
BA_ "ISignalName" SG_ 163 LKAReqToq "ILKAReqToq";
BA_ "LongName" SG_ 163 LKAReqToq "Lane_Keeping_Assist_Required_Torque";
BA_ "SysSignalName" SG_ 163 LKAReqToq "LKAReqToq";
BA_ "CompuMethodName" SG_ 163 FVCM_10ms_Group01_Reserved1 "FVCM_10ms_Group01_Reserved1";
BA_ "GenSigStartValue" SG_ 163 FVCM_10ms_Group01_Reserved1 31;
BA_ "ISignalName" SG_ 163 FVCM_10ms_Group01_Reserved1 "IFVCM_10ms_Group01_Reserved1";
BA_ "SysSignalName" SG_ 163 FVCM_10ms_Group01_Reserved1 "FVCM_10ms_Group01_Reserved1";
BA_ "CompuMethodName" SG_ 163 FVCM_10ms_Group01_Reserved2 "FVCM_10ms_Group01_Reserved2";
BA_ "GenSigStartValue" SG_ 163 FVCM_10ms_Group01_Reserved2 255;
BA_ "ISignalName" SG_ 163 FVCM_10ms_Group01_Reserved2 "IFVCM_10ms_Group01_Reserved2";
BA_ "SysSignalName" SG_ 163 FVCM_10ms_Group01_Reserved2 "FVCM_10ms_Group01_Reserved2";
BA_ "CompuMethodName" SG_ 163 FVCM_10ms_Group01_Reserved3 "FVCM_10ms_Group01_Reserved3";
BA_ "GenSigStartValue" SG_ 163 FVCM_10ms_Group01_Reserved3 255;
BA_ "ISignalName" SG_ 163 FVCM_10ms_Group01_Reserved3 "IFVCM_10ms_Group01_Reserved3";
BA_ "SysSignalName" SG_ 163 FVCM_10ms_Group01_Reserved3 "FVCM_10ms_Group01_Reserved3";
BA_ "CompuMethodName" SG_ 163 FVCM_10ms_Group01_Reserved4 "FVCM_10ms_Group01_Reserved4";
BA_ "GenSigStartValue" SG_ 163 FVCM_10ms_Group01_Reserved4 255;
BA_ "ISignalName" SG_ 163 FVCM_10ms_Group01_Reserved4 "IFVCM_10ms_Group01_Reserved4";
BA_ "SysSignalName" SG_ 163 FVCM_10ms_Group01_Reserved4 "FVCM_10ms_Group01_Reserved4";
BA_ "CompuMethodName" SG_ 163 FVCM_10ms_Group01_Reserved5 "FVCM_10ms_Group01_Reserved5";
BA_ "GenSigStartValue" SG_ 163 FVCM_10ms_Group01_Reserved5 255;
BA_ "ISignalName" SG_ 163 FVCM_10ms_Group01_Reserved5 "IFVCM_10ms_Group01_Reserved5";
BA_ "SysSignalName" SG_ 163 FVCM_10ms_Group01_Reserved5 "FVCM_10ms_Group01_Reserved5";
BA_ "CompuMethodName" SG_ 163 FVCM_10ms_Group01_Reserved6 "FVCM_10ms_Group01_Reserved6";
BA_ "GenSigStartValue" SG_ 163 FVCM_10ms_Group01_Reserved6 255;
BA_ "ISignalName" SG_ 163 FVCM_10ms_Group01_Reserved6 "IFVCM_10ms_Group01_Reserved6";
BA_ "SysSignalName" SG_ 163 FVCM_10ms_Group01_Reserved6 "FVCM_10ms_Group01_Reserved6";
BA_ "CompuMethodName" SG_ 163 FVCM_10ms_Group01_Reserved7 "FVCM_10ms_Group01_Reserved7";
BA_ "GenSigStartValue" SG_ 163 FVCM_10ms_Group01_Reserved7 255;
BA_ "ISignalName" SG_ 163 FVCM_10ms_Group01_Reserved7 "IFVCM_10ms_Group01_Reserved7";
BA_ "SysSignalName" SG_ 163 FVCM_10ms_Group01_Reserved7 "FVCM_10ms_Group01_Reserved7";
BA_ "CompuMethodName" SG_ 988 IBS_100ms_Group15_CRC "IBS_100ms_Group15_CRC";
BA_ "ISignalName" SG_ 988 IBS_100ms_Group15_CRC "IIBS_100ms_Group15_CRC";
BA_ "LongName" SG_ 988 IBS_100ms_Group15_CRC "IBS_100ms_Group15_CRC";
BA_ "SysSignalName" SG_ 988 IBS_100ms_Group15_CRC "IBS_100ms_Group15_CRC";
BA_ "CompuMethodName" SG_ 988 IBS_100ms_Group15_RC "IBS_100ms_Group15_RC";
BA_ "ISignalName" SG_ 988 IBS_100ms_Group15_RC "IIBS_100ms_Group15_RC";
BA_ "LongName" SG_ 988 IBS_100ms_Group15_RC "IBS_100ms_Group15_RC";
BA_ "SysSignalName" SG_ 988 IBS_100ms_Group15_RC "IBS_100ms_Group15_RC";
BA_ "CompuMethodName" SG_ 988 IBS_100ms_Group15_Reserved2 "IBS_100ms_Group15_Reserved2";
BA_ "GenSigStartValue" SG_ 988 IBS_100ms_Group15_Reserved2 1;
BA_ "ISignalName" SG_ 988 IBS_100ms_Group15_Reserved2 "IIBS_100ms_Group15_Reserved2";
BA_ "SysSignalName" SG_ 988 IBS_100ms_Group15_Reserved2 "IBS_100ms_Group15_Reserved2";
BA_ "CompuMethodName" SG_ 988 BrkFltAlrm_GB "BrkFltAlrm_GB";
BA_ "ISignalName" SG_ 988 BrkFltAlrm_GB "IBrkFltAlrm_GB";
BA_ "LongName" SG_ 988 BrkFltAlrm_GB "Brake system Alarm GB";
BA_ "SysSignalName" SG_ 988 BrkFltAlrm_GB "BrkFltAlrm_GB";
BA_ "CompuMethodName" SG_ 988 IBS_100ms_Group15_Reserved1 "IBS_100ms_Group15_Reserved1";
BA_ "GenSigStartValue" SG_ 988 IBS_100ms_Group15_Reserved1 1;
BA_ "ISignalName" SG_ 988 IBS_100ms_Group15_Reserved1 "IIBS_100ms_Group15_Reserved1";
BA_ "SysSignalName" SG_ 988 IBS_100ms_Group15_Reserved1 "IBS_100ms_Group15_Reserved1";
BA_ "CompuMethodName" SG_ 988 BrkFrc_GB "BrkFrc_GB";
BA_ "ISignalName" SG_ 988 BrkFrc_GB "IBrkFrc_GB";
BA_ "LongName" SG_ 988 BrkFrc_GB "Brake system Force status GB";
BA_ "SysSignalName" SG_ 988 BrkFrc_GB "BrkFrc_GB";
BA_ "CompuMethodName" SG_ 988 DistRCAvgDrvnSrc "DistRCAvgDrvnSrc";
BA_ "ISignalName" SG_ 988 DistRCAvgDrvnSrc "IDistRCAvgDrvnSrc";
BA_ "LongName" SG_ 988 DistRCAvgDrvnSrc "Distance Rolling Count Average Driven Source";
BA_ "SysSignalName" SG_ 988 DistRCAvgDrvnSrc "DistRCAvgDrvnSrc";
BA_ "CompuMethodName" SG_ 988 DistRCAvgDrvnRstOcd "DistRCAvgDrvnRstOcd";
BA_ "ISignalName" SG_ 988 DistRCAvgDrvnRstOcd "IDistRCAvgDrvnRstOcd";
BA_ "LongName" SG_ 988 DistRCAvgDrvnRstOcd "Distance Rolling Count Average Driven Reset Occurred";
BA_ "SysSignalName" SG_ 988 DistRCAvgDrvnRstOcd "DistRCAvgDrvnRstOcd";
BA_ "CompuMethodName" SG_ 988 CsbLvlSts "CsbLvlSts";
BA_ "ISignalName" SG_ 988 CsbLvlSts "ICsbLvlSts";
BA_ "LongName" SG_ 988 CsbLvlSts "Comfort Stop Brake Level Status";
BA_ "SysSignalName" SG_ 988 CsbLvlSts "CsbLvlSts";
BA_ "CompuMethodName" SG_ 988 IBSABSlvlResp "IBSABSlvlResp";
BA_ "ISignalName" SG_ 988 IBSABSlvlResp "IIBSABSlvlResp";
BA_ "LongName" SG_ 988 IBSABSlvlResp "Integrated Brake Sysytem Anti-Brake Sysytem level Response";
BA_ "SysSignalName" SG_ 988 IBSABSlvlResp "IBSABSlvlResp";
BA_ "CompuMethodName" SG_ 988 DistRCAvgDrvn "DistRCAvgDrvn";
BA_ "ISignalName" SG_ 988 DistRCAvgDrvn "IDistRCAvgDrvn";
BA_ "LongName" SG_ 988 DistRCAvgDrvn "Distance Rolling Count Average Driven";
BA_ "SysSignalName" SG_ 988 DistRCAvgDrvn "DistRCAvgDrvn";
BA_ "CompuMethodName" SG_ 988 IBS_100ms_Group15_Reserved3 "IBS_100ms_Group15_Reserved3";
BA_ "GenSigStartValue" SG_ 988 IBS_100ms_Group15_Reserved3 3;
BA_ "ISignalName" SG_ 988 IBS_100ms_Group15_Reserved3 "IIBS_100ms_Group15_Reserved3";
BA_ "SysSignalName" SG_ 988 IBS_100ms_Group15_Reserved3 "IBS_100ms_Group15_Reserved3";
BA_ "CompuMethodName" SG_ 988 DistRCAvgDrvnV "DistRCAvgDrvnV";
BA_ "ISignalName" SG_ 988 DistRCAvgDrvnV "IDistRCAvgDrvnV";
BA_ "LongName" SG_ 988 DistRCAvgDrvnV "Distance Rolling Count Average Driven Validity";
BA_ "SysSignalName" SG_ 988 DistRCAvgDrvnV "DistRCAvgDrvnV";
BA_ "CompuMethodName" SG_ 988 IBS_100ms_Group15_Reserved4 "IBS_100ms_Group15_Reserved4";
BA_ "GenSigStartValue" SG_ 988 IBS_100ms_Group15_Reserved4 3;
BA_ "ISignalName" SG_ 988 IBS_100ms_Group15_Reserved4 "IIBS_100ms_Group15_Reserved4";
BA_ "SysSignalName" SG_ 988 IBS_100ms_Group15_Reserved4 "IBS_100ms_Group15_Reserved4";
BA_ "CompuMethodName" SG_ 988 IBSESPlvlResp "IBSESPlvlResp";
BA_ "ISignalName" SG_ 988 IBSESPlvlResp "IIBSESPlvlResp";
BA_ "LongName" SG_ 988 IBSESPlvlResp "Integrated Brake Sysytem Electic Stability Program level Response";
BA_ "SysSignalName" SG_ 988 IBSESPlvlResp "IBSESPlvlResp";
BA_ "CompuMethodName" SG_ 988 IBSTCSlvlResp "IBSTCSlvlResp";
BA_ "ISignalName" SG_ 988 IBSTCSlvlResp "IIBSTCSlvlResp";
BA_ "LongName" SG_ 988 IBSTCSlvlResp "Integrated Brake Sysytem Traction Control System level Response";
BA_ "SysSignalName" SG_ 988 IBSTCSlvlResp "IBSTCSlvlResp";
BA_ "CompuMethodName" SG_ 988 IBS_100ms_Group15_Reserved5 "IBS_100ms_Group15_Reserved5";
BA_ "GenSigStartValue" SG_ 988 IBS_100ms_Group15_Reserved5 255;
BA_ "ISignalName" SG_ 988 IBS_100ms_Group15_Reserved5 "IIBS_100ms_Group15_Reserved5";
BA_ "SysSignalName" SG_ 988 IBS_100ms_Group15_Reserved5 "IBS_100ms_Group15_Reserved5";
BA_ "CompuMethodName" SG_ 988 IBS_100ms_Group15_Reserved6 "IBS_100ms_Group15_Reserved6";
BA_ "GenSigStartValue" SG_ 988 IBS_100ms_Group15_Reserved6 255;
BA_ "ISignalName" SG_ 988 IBS_100ms_Group15_Reserved6 "IIBS_100ms_Group15_Reserved6";
BA_ "SysSignalName" SG_ 988 IBS_100ms_Group15_Reserved6 "IBS_100ms_Group15_Reserved6";
BA_ "CompuMethodName" SG_ 318 LDrvnWhlRotlDistPlsCtr "LDrvnWhlRotlDistPlsCtr";
BA_ "ISignalName" SG_ 318 LDrvnWhlRotlDistPlsCtr "ILDrvnWhlRotlDistPlsCtr";
BA_ "LongName" SG_ 318 LDrvnWhlRotlDistPlsCtr "Left Driven Wheel Rotational Distance Pulse Counter";
BA_ "SysSignalName" SG_ 318 LDrvnWhlRotlDistPlsCtr "LDrvnWhlRotlDistPlsCtr";
BA_ "CompuMethodName" SG_ 318 LDrvnWhlRotlSeqNum "LDrvnWhlRotlSeqNum";
BA_ "ISignalName" SG_ 318 LDrvnWhlRotlSeqNum "ILDrvnWhlRotlSeqNum";
BA_ "LongName" SG_ 318 LDrvnWhlRotlSeqNum "Left Driven Wheel Rotational Sequence Number";
BA_ "SysSignalName" SG_ 318 LDrvnWhlRotlSeqNum "LDrvnWhlRotlSeqNum";
BA_ "CompuMethodName" SG_ 318 LDrvnWhlRotlRstOcd "LDrvnWhlRotlRstOcd";
BA_ "ISignalName" SG_ 318 LDrvnWhlRotlRstOcd "ILDrvnWhlRotlRstOcd";
BA_ "LongName" SG_ 318 LDrvnWhlRotlRstOcd "Left Driven Wheel Rotational Reset Occurred";
BA_ "SysSignalName" SG_ 318 LDrvnWhlRotlRstOcd "LDrvnWhlRotlRstOcd";
BA_ "CompuMethodName" SG_ 318 LDrvnWhlRotlDistV "LDrvnWhlRotlDistV";
BA_ "ISignalName" SG_ 318 LDrvnWhlRotlDistV "ILDrvnWhlRotlDistV";
BA_ "LongName" SG_ 318 LDrvnWhlRotlDistV "Left Driven Wheel Rotational Distance Validity";
BA_ "SysSignalName" SG_ 318 LDrvnWhlRotlDistV "LDrvnWhlRotlDistV";
BA_ "CompuMethodName" SG_ 318 LDrvnWhlRotlDistTRC "LDrvnWhlRotlDistTRC";
BA_ "ISignalName" SG_ 318 LDrvnWhlRotlDistTRC "ILDrvnWhlRotlDistTRC";
BA_ "LongName" SG_ 318 LDrvnWhlRotlDistTRC "Left Driven Wheel Rotational Distance Timestamp Rollover Counter";
BA_ "SysSignalName" SG_ 318 LDrvnWhlRotlDistTRC "LDrvnWhlRotlDistTRC";
BA_ "CompuMethodName" SG_ 318 LDrvnWhlRotlDistTmsp "LDrvnWhlRotlDistTmsp";
BA_ "ISignalName" SG_ 318 LDrvnWhlRotlDistTmsp "ILDrvnWhlRotlDistTmsp";
BA_ "LongName" SG_ 318 LDrvnWhlRotlDistTmsp "Left Driven Wheel Rotational Distance Timestamp";
BA_ "SysSignalName" SG_ 318 LDrvnWhlRotlDistTmsp "LDrvnWhlRotlDistTmsp";
BA_ "CompuMethodName" SG_ 318 RDrvnWhlRotlDistPlsCtr "RDrvnWhlRotlDistPlsCtr";
BA_ "ISignalName" SG_ 318 RDrvnWhlRotlDistPlsCtr "IRDrvnWhlRotlDistPlsCtr";
BA_ "LongName" SG_ 318 RDrvnWhlRotlDistPlsCtr "Right Driven Wheel Rotational Distance Pulse Counter";
BA_ "SysSignalName" SG_ 318 RDrvnWhlRotlDistPlsCtr "RDrvnWhlRotlDistPlsCtr";
BA_ "CompuMethodName" SG_ 318 RDrvnWhlRotlSeqNum "RDrvnWhlRotlSeqNum";
BA_ "ISignalName" SG_ 318 RDrvnWhlRotlSeqNum "IRDrvnWhlRotlSeqNum";
BA_ "LongName" SG_ 318 RDrvnWhlRotlSeqNum "Right Driven Wheel Rotational Sequence Number";
BA_ "SysSignalName" SG_ 318 RDrvnWhlRotlSeqNum "RDrvnWhlRotlSeqNum";
BA_ "CompuMethodName" SG_ 318 RDrvnWhlRotlRstOcd "RDrvnWhlRotlRstOcd";
BA_ "ISignalName" SG_ 318 RDrvnWhlRotlRstOcd "IRDrvnWhlRotlRstOcd";
BA_ "LongName" SG_ 318 RDrvnWhlRotlRstOcd "Right Driven Wheel Rotational Reset Occurred";
BA_ "SysSignalName" SG_ 318 RDrvnWhlRotlRstOcd "RDrvnWhlRotlRstOcd";
BA_ "CompuMethodName" SG_ 318 RDrvnWhlRotlDistV "RDrvnWhlRotlDistV";
BA_ "ISignalName" SG_ 318 RDrvnWhlRotlDistV "IRDrvnWhlRotlDistV";
BA_ "LongName" SG_ 318 RDrvnWhlRotlDistV "Right Driven Wheel Rotational Distance Validity";
BA_ "SysSignalName" SG_ 318 RDrvnWhlRotlDistV "RDrvnWhlRotlDistV";
BA_ "CompuMethodName" SG_ 318 RDrvnWhlRotlDistTRC "RDrvnWhlRotlDistTRC";
BA_ "ISignalName" SG_ 318 RDrvnWhlRotlDistTRC "IRDrvnWhlRotlDistTRC";
BA_ "LongName" SG_ 318 RDrvnWhlRotlDistTRC "Right Driven Wheel Rotational Distance Timestamp Rollover Counter";
BA_ "SysSignalName" SG_ 318 RDrvnWhlRotlDistTRC "RDrvnWhlRotlDistTRC";
BA_ "CompuMethodName" SG_ 318 RDrvnWhlRotlDistTmsp "RDrvnWhlRotlDistTmsp";
BA_ "ISignalName" SG_ 318 RDrvnWhlRotlDistTmsp "IRDrvnWhlRotlDistTmsp";
BA_ "LongName" SG_ 318 RDrvnWhlRotlDistTmsp "Right Driven Wheel Rotational Distance Timestamp";
BA_ "SysSignalName" SG_ 318 RDrvnWhlRotlDistTmsp "RDrvnWhlRotlDistTmsp";
BA_ "CompuMethodName" SG_ 319 LNonDrvnWhlRotlDistPC "LNonDrvnWhlRotlDistPC";
BA_ "ISignalName" SG_ 319 LNonDrvnWhlRotlDistPC "ILNonDrvnWhlRotlDistPC";
BA_ "LongName" SG_ 319 LNonDrvnWhlRotlDistPC "Left Non Driven Wheel Rotational Distance Pulse Counter";
BA_ "SysSignalName" SG_ 319 LNonDrvnWhlRotlDistPC "LNonDrvnWhlRotlDistPC";
BA_ "CompuMethodName" SG_ 319 LNonDrvnWhlRotlSeqNum "LNonDrvnWhlRotlSeqNum";
BA_ "ISignalName" SG_ 319 LNonDrvnWhlRotlSeqNum "ILNonDrvnWhlRotlSeqNum";
BA_ "LongName" SG_ 319 LNonDrvnWhlRotlSeqNum "Left Non Driven Wheel Rotational Sequence Number";
BA_ "SysSignalName" SG_ 319 LNonDrvnWhlRotlSeqNum "LNonDrvnWhlRotlSeqNum";
BA_ "CompuMethodName" SG_ 319 LNonDrvnWhlRotlRstOcd "LNonDrvnWhlRotlRstOcd";
BA_ "ISignalName" SG_ 319 LNonDrvnWhlRotlRstOcd "ILNonDrvnWhlRotlRstOcd";
BA_ "LongName" SG_ 319 LNonDrvnWhlRotlRstOcd "Left Non Driven Wheel Rotational Reset Occurred";
BA_ "SysSignalName" SG_ 319 LNonDrvnWhlRotlRstOcd "LNonDrvnWhlRotlRstOcd";
BA_ "CompuMethodName" SG_ 319 LNonDrvnWhlRotlDistV "LNonDrvnWhlRotlDistV";
BA_ "ISignalName" SG_ 319 LNonDrvnWhlRotlDistV "ILNonDrvnWhlRotlDistV";
BA_ "LongName" SG_ 319 LNonDrvnWhlRotlDistV "Left Non Driven Wheel Rotational Distance Validity";
BA_ "SysSignalName" SG_ 319 LNonDrvnWhlRotlDistV "LNonDrvnWhlRotlDistV";
BA_ "CompuMethodName" SG_ 319 LNonDrvnWhlRotlDistTRC "LNonDrvnWhlRotlDistTRC";
BA_ "ISignalName" SG_ 319 LNonDrvnWhlRotlDistTRC "ILNonDrvnWhlRotlDistTRC";
BA_ "LongName" SG_ 319 LNonDrvnWhlRotlDistTRC "Left Non Driven Wheel Rotational Distance Timestamp Rollover Counter";
BA_ "SysSignalName" SG_ 319 LNonDrvnWhlRotlDistTRC "LNonDrvnWhlRotlDistTRC";
BA_ "CompuMethodName" SG_ 319 LNonDrvnWhlRotlDistT "LNonDrvnWhlRotlDistT";
BA_ "ISignalName" SG_ 319 LNonDrvnWhlRotlDistT "ILNonDrvnWhlRotlDistT";
BA_ "LongName" SG_ 319 LNonDrvnWhlRotlDistT "Left Non Driven Wheel Rotational Distance Timestamp";
BA_ "SysSignalName" SG_ 319 LNonDrvnWhlRotlDistT "LNonDrvnWhlRotlDistT";
BA_ "CompuMethodName" SG_ 319 RNonDrvnWhlRotlDistPC "RNonDrvnWhlRotlDistPC";
BA_ "ISignalName" SG_ 319 RNonDrvnWhlRotlDistPC "IRNonDrvnWhlRotlDistPC";
BA_ "LongName" SG_ 319 RNonDrvnWhlRotlDistPC "Right Non Driven Wheel Rotational Distance Pulse Counter";
BA_ "SysSignalName" SG_ 319 RNonDrvnWhlRotlDistPC "RNonDrvnWhlRotlDistPC";
BA_ "CompuMethodName" SG_ 319 RNonDrvnWhlRotlSeqNum "RNonDrvnWhlRotlSeqNum";
BA_ "ISignalName" SG_ 319 RNonDrvnWhlRotlSeqNum "IRNonDrvnWhlRotlSeqNum";
BA_ "LongName" SG_ 319 RNonDrvnWhlRotlSeqNum "Right Non Driven Wheel Rotational Sequence Number";
BA_ "SysSignalName" SG_ 319 RNonDrvnWhlRotlSeqNum "RNonDrvnWhlRotlSeqNum";
BA_ "CompuMethodName" SG_ 319 RNonDrvnWhlRotlRstOcd "RNonDrvnWhlRotlRstOcd";
BA_ "ISignalName" SG_ 319 RNonDrvnWhlRotlRstOcd "IRNonDrvnWhlRotlRstOcd";
BA_ "LongName" SG_ 319 RNonDrvnWhlRotlRstOcd "Right Non Driven Wheel Rotational Reset Occurred";
BA_ "SysSignalName" SG_ 319 RNonDrvnWhlRotlRstOcd "RNonDrvnWhlRotlRstOcd";
BA_ "CompuMethodName" SG_ 319 RNonDrvnWhlRotlDistV "RNonDrvnWhlRotlDistV";
BA_ "ISignalName" SG_ 319 RNonDrvnWhlRotlDistV "IRNonDrvnWhlRotlDistV";
BA_ "LongName" SG_ 319 RNonDrvnWhlRotlDistV "Right Non Driven Wheel Rotational Distance Validity";
BA_ "SysSignalName" SG_ 319 RNonDrvnWhlRotlDistV "RNonDrvnWhlRotlDistV";
BA_ "CompuMethodName" SG_ 319 RNonDrvnWhlRotlDistTRC "RNonDrvnWhlRotlDistTRC";
BA_ "ISignalName" SG_ 319 RNonDrvnWhlRotlDistTRC "IRNonDrvnWhlRotlDistTRC";
BA_ "LongName" SG_ 319 RNonDrvnWhlRotlDistTRC "Right Non Driven Wheel Rotational Distance Timestamp Rollover Counter";
BA_ "SysSignalName" SG_ 319 RNonDrvnWhlRotlDistTRC "RNonDrvnWhlRotlDistTRC";
BA_ "CompuMethodName" SG_ 319 RNonDrvnWhlRotlDistT "RNonDrvnWhlRotlDistT";
BA_ "ISignalName" SG_ 319 RNonDrvnWhlRotlDistT "IRNonDrvnWhlRotlDistT";
BA_ "LongName" SG_ 319 RNonDrvnWhlRotlDistT "Right Non Driven Wheel Rotational Distance Timestamp";
BA_ "SysSignalName" SG_ 319 RNonDrvnWhlRotlDistT "RNonDrvnWhlRotlDistT";
BA_ "CompuMethodName" SG_ 423 IBS_20ms_Group07_CRC "IBS_20ms_Group07_CRC";
BA_ "ISignalName" SG_ 423 IBS_20ms_Group07_CRC "IIBS_20ms_Group07_CRC";
BA_ "LongName" SG_ 423 IBS_20ms_Group07_CRC "IBS_20ms_Group07_CRC";
BA_ "SysSignalName" SG_ 423 IBS_20ms_Group07_CRC "IBS_20ms_Group07_CRC";
BA_ "CompuMethodName" SG_ 423 IBS_20ms_Group07_RC "IBS_20ms_Group07_RC";
BA_ "ISignalName" SG_ 423 IBS_20ms_Group07_RC "IIBS_20ms_Group07_RC";
BA_ "LongName" SG_ 423 IBS_20ms_Group07_RC "IBS_20ms_Group07_RC";
BA_ "SysSignalName" SG_ 423 IBS_20ms_Group07_RC "IBS_20ms_Group07_RC";
BA_ "CompuMethodName" SG_ 423 HDCSysSts "HDCSysSts";
BA_ "ISignalName" SG_ 423 HDCSysSts "IHDCSysSts";
BA_ "LongName" SG_ 423 HDCSysSts "Hill Descent Control System Status";
BA_ "SysSignalName" SG_ 423 HDCSysSts "HDCSysSts";
BA_ "CompuMethodName" SG_ 423 ABSIO "ABSIO";
BA_ "ISignalName" SG_ 423 ABSIO "IABSIO";
BA_ "LongName" SG_ 423 ABSIO "Antilock Brake System Indication On";
BA_ "SysSignalName" SG_ 423 ABSIO "ABSIO";
BA_ "CompuMethodName" SG_ 423 VSESysA "VSESysA";
BA_ "ISignalName" SG_ 423 VSESysA "IVSESysA";
BA_ "LongName" SG_ 423 VSESysA "Vehicle Stability Enhancement System Active";
BA_ "SysSignalName" SG_ 423 VSESysA "VSESysA";
BA_ "CompuMethodName" SG_ 423 BrkSysYlwBrkTlltReq "BrkSysYlwBrkTlltReq";
BA_ "ISignalName" SG_ 423 BrkSysYlwBrkTlltReq "IBrkSysYlwBrkTlltReq";
BA_ "LongName" SG_ 423 BrkSysYlwBrkTlltReq "Brake System Yellow Brake Telltale Request";
BA_ "SysSignalName" SG_ 423 BrkSysYlwBrkTlltReq "BrkSysYlwBrkTlltReq";
BA_ "CompuMethodName" SG_ 423 VSESts "VSESts";
BA_ "ISignalName" SG_ 423 VSESts "IVSESts";
BA_ "LongName" SG_ 423 VSESts "Vehicle Stability Enhancement Status";
BA_ "SysSignalName" SG_ 423 VSESts "VSESts";
BA_ "CompuMethodName" SG_ 423 VSEMd "VSEMd";
BA_ "ISignalName" SG_ 423 VSEMd "IVSEMd";
BA_ "LongName" SG_ 423 VSEMd "Vehicle Stability Enhancement Mode";
BA_ "SysSignalName" SG_ 423 VSEMd "VSEMd";
BA_ "CompuMethodName" SG_ 423 MultColBrkEnbA "MultColBrkEnbA";
BA_ "ISignalName" SG_ 423 MultColBrkEnbA "IMultColBrkEnbA";
BA_ "LongName" SG_ 423 MultColBrkEnbA "Multiturn Collision Brake Enable Active";
BA_ "SysSignalName" SG_ 423 MultColBrkEnbA "MultColBrkEnbA";
BA_ "CompuMethodName" SG_ 423 EBDFaultSt "EBDFaultSt";
BA_ "ISignalName" SG_ 423 EBDFaultSt "IEBDFaultSt";
BA_ "LongName" SG_ 423 EBDFaultSt "Electronic Brake Distribution Fault Status";
BA_ "SysSignalName" SG_ 423 EBDFaultSt "EBDFaultSt";
BA_ "CompuMethodName" SG_ 423 TCSOpngSts "TCSOpngSts";
BA_ "ISignalName" SG_ 423 TCSOpngSts "ITCSOpngSts";
BA_ "LongName" SG_ 423 TCSOpngSts "Traction Control System Operating Status";
BA_ "SysSignalName" SG_ 423 TCSOpngSts "TCSOpngSts";
BA_ "CompuMethodName" SG_ 423 TCSOpngMd "TCSOpngMd";
BA_ "ISignalName" SG_ 423 TCSOpngMd "ITCSOpngMd";
BA_ "LongName" SG_ 423 TCSOpngMd "Traction Control System Operating Mode";
BA_ "SysSignalName" SG_ 423 TCSOpngMd "TCSOpngMd";
BA_ "CompuMethodName" SG_ 423 BrkSysHillStAstAvlbl "BrkSysHillStAstAvlbl";
BA_ "ISignalName" SG_ 423 BrkSysHillStAstAvlbl "IBrkSysHillStAstAvlbl";
BA_ "LongName" SG_ 423 BrkSysHillStAstAvlbl "Brake System Hill Start Assist Available";
BA_ "SysSignalName" SG_ 423 BrkSysHillStAstAvlbl "BrkSysHillStAstAvlbl";
BA_ "CompuMethodName" SG_ 423 RgtvBrkFnFltSts "RgtvBrkFnFltSts";
BA_ "ISignalName" SG_ 423 RgtvBrkFnFltSts "IRgtvBrkFnFltSts";
BA_ "LongName" SG_ 423 RgtvBrkFnFltSts "Regenerative Brake Function Fault Status";
BA_ "SysSignalName" SG_ 423 RgtvBrkFnFltSts "RgtvBrkFnFltSts";
BA_ "CompuMethodName" SG_ 423 MSRF "MSRF";
BA_ "ISignalName" SG_ 423 MSRF "IMSRF";
BA_ "LongName" SG_ 423 MSRF "Motor Slide Retainer Fault";
BA_ "SysSignalName" SG_ 423 MSRF "MSRF";
BA_ "CompuMethodName" SG_ 423 AutoHoldSysSts "AutoHoldSysSts";
BA_ "ISignalName" SG_ 423 AutoHoldSysSts "IAutoHoldSysSts";
BA_ "LongName" SG_ 423 AutoHoldSysSts "Auto Hold System Status";
BA_ "SysSignalName" SG_ 423 AutoHoldSysSts "AutoHoldSysSts";
BA_ "CompuMethodName" SG_ 423 AutoHoldMsg "AutoHoldMsg";
BA_ "ISignalName" SG_ 423 AutoHoldMsg "IAutoHoldMsg";
BA_ "LongName" SG_ 423 AutoHoldMsg "Auto Hold Message";
BA_ "SysSignalName" SG_ 423 AutoHoldMsg "AutoHoldMsg";
BA_ "CompuMethodName" SG_ 423 EBDA "EBDA";
BA_ "GenSigStartValue" SG_ 423 EBDA 1;
BA_ "ISignalName" SG_ 423 EBDA "IEBDA";
BA_ "LongName" SG_ 423 EBDA "Electronic Brake Distribution Active";
BA_ "SysSignalName" SG_ 423 EBDA "EBDA";
BA_ "CompuMethodName" SG_ 423 RgtvBrkFnSts "RgtvBrkFnSts";
BA_ "ISignalName" SG_ 423 RgtvBrkFnSts "IRgtvBrkFnSts";
BA_ "LongName" SG_ 423 RgtvBrkFnSts "Regenerative Brake Function Status";
BA_ "SysSignalName" SG_ 423 RgtvBrkFnSts "RgtvBrkFnSts";
BA_ "CompuMethodName" SG_ 423 TCSEnbd "TCSEnbd";
BA_ "ISignalName" SG_ 423 TCSEnbd "ITCSEnbd";
BA_ "LongName" SG_ 423 TCSEnbd "Traction Control System Enabled";
BA_ "SysSignalName" SG_ 423 TCSEnbd "TCSEnbd";
BA_ "CompuMethodName" SG_ 423 HBAActiveSt "HBAActiveSt";
BA_ "ISignalName" SG_ 423 HBAActiveSt "IHBAActiveSt";
BA_ "LongName" SG_ 423 HBAActiveSt "Hydraulic Brake Assist Active Status";
BA_ "SysSignalName" SG_ 423 HBAActiveSt "HBAActiveSt";
BA_ "CompuMethodName" SG_ 423 TCSA "TCSA";
BA_ "ISignalName" SG_ 423 TCSA "ITCSA";
BA_ "LongName" SG_ 423 TCSA "Traction Control System Active";
BA_ "SysSignalName" SG_ 423 TCSA "TCSA";
BA_ "CompuMethodName" SG_ 423 EnDragToqRducnA "EnDragToqRducnA";
BA_ "ISignalName" SG_ 423 EnDragToqRducnA "IEnDragToqRducnA";
BA_ "LongName" SG_ 423 EnDragToqRducnA "Engine Drag Torque Reduction Active";
BA_ "SysSignalName" SG_ 423 EnDragToqRducnA "EnDragToqRducnA";
BA_ "CompuMethodName" SG_ 423 ABSF "ABSF";
BA_ "ISignalName" SG_ 423 ABSF "IABSF";
BA_ "LongName" SG_ 423 ABSF "Antilock Brake System Fault";
BA_ "SysSignalName" SG_ 423 ABSF "ABSF";
BA_ "CompuMethodName" SG_ 423 ABSA "ABSA";
BA_ "ISignalName" SG_ 423 ABSA "IABSA";
BA_ "LongName" SG_ 423 ABSA "Antilock Brake System Active";
BA_ "SysSignalName" SG_ 423 ABSA "ABSA";
BA_ "CompuMethodName" SG_ 423 HBAValidSt "HBAValidSt";
BA_ "ISignalName" SG_ 423 HBAValidSt "IHBAValidSt";
BA_ "LongName" SG_ 423 HBAValidSt "Hydraulic Brake Assist Validity Status";
BA_ "SysSignalName" SG_ 423 HBAValidSt "HBAValidSt";
BA_ "CompuMethodName" SG_ 423 MSRA "MSRA";
BA_ "GenSigStartValue" SG_ 423 MSRA 1;
BA_ "ISignalName" SG_ 423 MSRA "IMSRA";
BA_ "LongName" SG_ 423 MSRA "Motor Slide Retainer Active";
BA_ "SysSignalName" SG_ 423 MSRA "MSRA";
BA_ "CompuMethodName" SG_ 423 EmgcBrkAV "EmgcBrkAV";
BA_ "ISignalName" SG_ 423 EmgcBrkAV "IEmgcBrkAV";
BA_ "LongName" SG_ 423 EmgcBrkAV "Emergency Brake Active Validity";
BA_ "SysSignalName" SG_ 423 EmgcBrkAV "EmgcBrkAV";
BA_ "CompuMethodName" SG_ 423 EmgcBrkA "EmgcBrkA";
BA_ "ISignalName" SG_ 423 EmgcBrkA "IEmgcBrkA";
BA_ "LongName" SG_ 423 EmgcBrkA "Emergency Brake Active";
BA_ "SysSignalName" SG_ 423 EmgcBrkA "EmgcBrkA";
BA_ "CompuMethodName" SG_ 423 BrkSysRedBrkTlltReq "BrkSysRedBrkTlltReq";
BA_ "ISignalName" SG_ 423 BrkSysRedBrkTlltReq "IBrkSysRedBrkTlltReq";
BA_ "LongName" SG_ 423 BrkSysRedBrkTlltReq "Brake System Red Brake Telltale Request";
BA_ "SysSignalName" SG_ 423 BrkSysRedBrkTlltReq "BrkSysRedBrkTlltReq";
BA_ "CompuMethodName" SG_ 423 BrkSysHillStAstSts "BrkSysHillStAstSts";
BA_ "ISignalName" SG_ 423 BrkSysHillStAstSts "IBrkSysHillStAstSts";
BA_ "LongName" SG_ 423 BrkSysHillStAstSts "Brake System Hill Start Assist Status";
BA_ "SysSignalName" SG_ 423 BrkSysHillStAstSts "BrkSysHillStAstSts";
BA_ "CompuMethodName" SG_ 423 AVHSigPdlSts "AVHSigPdlSts";
BA_ "ISignalName" SG_ 423 AVHSigPdlSts "IAVHSigPdlSts";
BA_ "LongName" SG_ 423 AVHSigPdlSts "AVH Signal Pedal Status";
BA_ "SysSignalName" SG_ 423 AVHSigPdlSts "AVHSigPdlSts";
BA_ "CompuMethodName" SG_ 423 AutoHoldMdSts "AutoHoldMdSts";
BA_ "ISignalName" SG_ 423 AutoHoldMdSts "IAutoHoldMdSts";
BA_ "LongName" SG_ 423 AutoHoldMdSts "Auto Hold Mode Status";
BA_ "SysSignalName" SG_ 423 AutoHoldMdSts "AutoHoldMdSts";
BA_ "CompuMethodName" SG_ 423 SoftSpSysSts "SoftSpSysSts";
BA_ "ISignalName" SG_ 423 SoftSpSysSts "ISoftSpSysSts";
BA_ "LongName" SG_ 423 SoftSpSysSts "Soft Stop System Status";
BA_ "SysSignalName" SG_ 423 SoftSpSysSts "SoftSpSysSts";
BA_ "CompuMethodName" SG_ 423 MulColBrkA "MulColBrkA";
BA_ "ISignalName" SG_ 423 MulColBrkA "IMulColBrkA";
BA_ "LongName" SG_ 423 MulColBrkA "Multi Collision Brake Active";
BA_ "SysSignalName" SG_ 423 MulColBrkA "MulColBrkA";
BA_ "CompuMethodName" SG_ 423 MulColBrkAvlblySts "MulColBrkAvlblySts";
BA_ "ISignalName" SG_ 423 MulColBrkAvlblySts "IMulColBrkAvlblySts";
BA_ "LongName" SG_ 423 MulColBrkAvlblySts "Multi Collision Brake Availability Status";
BA_ "SysSignalName" SG_ 423 MulColBrkAvlblySts "MulColBrkAvlblySts";
BA_ "CompuMethodName" SG_ 342 IBS_20ms_Group08_CRC "IBS_20ms_Group08_CRC";
BA_ "ISignalName" SG_ 342 IBS_20ms_Group08_CRC "IIBS_20ms_Group08_CRC";
BA_ "LongName" SG_ 342 IBS_20ms_Group08_CRC "IBS_20ms_Group08_CRC";
BA_ "SysSignalName" SG_ 342 IBS_20ms_Group08_CRC "IBS_20ms_Group08_CRC";
BA_ "CompuMethodName" SG_ 342 IBS_20ms_Group08_RC "IBS_20ms_Group08_RC";
BA_ "ISignalName" SG_ 342 IBS_20ms_Group08_RC "IIBS_20ms_Group08_RC";
BA_ "LongName" SG_ 342 IBS_20ms_Group08_RC "IBS_20ms_Group08_RC";
BA_ "SysSignalName" SG_ 342 IBS_20ms_Group08_RC "IBS_20ms_Group08_RC";
BA_ "CompuMethodName" SG_ 342 EPBSts "EPBSts";
BA_ "ISignalName" SG_ 342 EPBSts "IEPBSts";
BA_ "LongName" SG_ 342 EPBSts "Electric Park Brake Status";
BA_ "SysSignalName" SG_ 342 EPBSts "EPBSts";
BA_ "CompuMethodName" SG_ 342 EPBAppcnSts "EPBAppcnSts";
BA_ "ISignalName" SG_ 342 EPBAppcnSts "IEPBAppcnSts";
BA_ "LongName" SG_ 342 EPBAppcnSts "Electric Park Brake Application Status";
BA_ "SysSignalName" SG_ 342 EPBAppcnSts "EPBAppcnSts";
BA_ "CompuMethodName" SG_ 342 EPBCCCanclReqd "EPBCCCanclReqd";
BA_ "ISignalName" SG_ 342 EPBCCCanclReqd "IEPBCCCanclReqd";
BA_ "LongName" SG_ 342 EPBCCCanclReqd "Electric Park Brake Cruise Control Cancel Requested";
BA_ "SysSignalName" SG_ 342 EPBCCCanclReqd "EPBCCCanclReqd";
BA_ "CompuMethodName" SG_ 342 EPBSysStsIndReq "EPBSysStsIndReq";
BA_ "ISignalName" SG_ 342 EPBSysStsIndReq "IEPBSysStsIndReq";
BA_ "LongName" SG_ 342 EPBSysStsIndReq "Electric Park Brake System Status Indication Request";
BA_ "SysSignalName" SG_ 342 EPBSysStsIndReq "EPBSysStsIndReq";
BA_ "CompuMethodName" SG_ 342 EPBSwSts "EPBSwSts";
BA_ "ISignalName" SG_ 342 EPBSwSts "IEPBSwSts";
BA_ "LongName" SG_ 342 EPBSwSts "Electric Park Brake Switch Status";
BA_ "SysSignalName" SG_ 342 EPBSwSts "EPBSwSts";
BA_ "CompuMethodName" SG_ 342 EPBAvlblySts "EPBAvlblySts";
BA_ "ISignalName" SG_ 342 EPBAvlblySts "IEPBAvlblySts";
BA_ "LongName" SG_ 342 EPBAvlblySts "Electric Park Brake Availability Status";
BA_ "SysSignalName" SG_ 342 EPBAvlblySts "EPBAvlblySts";
BA_ "CompuMethodName" SG_ 342 EPBSysAudWrnngReq "EPBSysAudWrnngReq";
BA_ "ISignalName" SG_ 342 EPBSysAudWrnngReq "IEPBSysAudWrnngReq";
BA_ "LongName" SG_ 342 EPBSysAudWrnngReq "Electric Park Brake System Audible Warning Request";
BA_ "SysSignalName" SG_ 342 EPBSysAudWrnngReq "EPBSysAudWrnngReq";
BA_ "CompuMethodName" SG_ 342 EPBSwStsV "EPBSwStsV";
BA_ "ISignalName" SG_ 342 EPBSwStsV "IEPBSwStsV";
BA_ "LongName" SG_ 342 EPBSwStsV "Electric Park Brake Switch Status Validity";
BA_ "SysSignalName" SG_ 342 EPBSwStsV "EPBSwStsV";
BA_ "CompuMethodName" SG_ 342 EPBSysWrnngIndReq "EPBSysWrnngIndReq";
BA_ "ISignalName" SG_ 342 EPBSysWrnngIndReq "IEPBSysWrnngIndReq";
BA_ "LongName" SG_ 342 EPBSysWrnngIndReq "Electric Park Brake System Warning Indication Request";
BA_ "SysSignalName" SG_ 342 EPBSysWrnngIndReq "EPBSysWrnngIndReq";
BA_ "CompuMethodName" SG_ 342 EPBSysDspMsgReq "EPBSysDspMsgReq";
BA_ "ISignalName" SG_ 342 EPBSysDspMsgReq "IEPBSysDspMsgReq";
BA_ "LongName" SG_ 342 EPBSysDspMsgReq "Electric Park Brake System Display Message Request";
BA_ "SysSignalName" SG_ 342 EPBSysDspMsgReq "EPBSysDspMsgReq";
BA_ "CompuMethodName" SG_ 342 ChSysTrBrkAxleToqVal "ChSysTrBrkAxleToqVal";
BA_ "ISignalName" SG_ 342 ChSysTrBrkAxleToqVal "IChSysTrBrkAxleToqVal";
BA_ "LongName" SG_ 342 ChSysTrBrkAxleToqVal "Chassis System transmission Brake Axle Torque Value";
BA_ "SysSignalName" SG_ 342 ChSysTrBrkAxleToqVal "ChSysTrBrkAxleToqVal";
BA_ "CompuMethodName" SG_ 342 EPBAPAAvlbl "EPBAPAAvlbl";
BA_ "ISignalName" SG_ 342 EPBAPAAvlbl "IEPBAPAAvlbl";
BA_ "LongName" SG_ 342 EPBAPAAvlbl "Electric Park Brake Auto Parking Assist Available";
BA_ "SysSignalName" SG_ 342 EPBAPAAvlbl "EPBAPAAvlbl";
BA_ "CompuMethodName" SG_ 342 EPBFlrSts "EPBFlrSts";
BA_ "ISignalName" SG_ 342 EPBFlrSts "IEPBFlrSts";
BA_ "LongName" SG_ 342 EPBFlrSts "Electric Park Brake Failure Status";
BA_ "SysSignalName" SG_ 342 EPBFlrSts "EPBFlrSts";
BA_ "CompuMethodName" SG_ 342 ChSysSecyBrkAxleToqVal "ChSysSecyBrkAxleToqVal";
BA_ "ISignalName" SG_ 342 ChSysSecyBrkAxleToqVal "IChSysSecyBrkAxleToqVal";
BA_ "LongName" SG_ 342 ChSysSecyBrkAxleToqVal "Chassis System Secondly Brake Axle Torque Value";
BA_ "SysSignalName" SG_ 342 ChSysSecyBrkAxleToqVal "ChSysSecyBrkAxleToqVal";
BA_ "CompuMethodName" SG_ 342 ChSysSecyBrkAxleToqValV "ChSysSecyBrkAxleToqValV";
BA_ "ISignalName" SG_ 342 ChSysSecyBrkAxleToqValV "IChSysSecyBrkAxleToqValV";
BA_ "LongName" SG_ 342 ChSysSecyBrkAxleToqValV "Chassis System Secondly Brake Axle Torque Value Valid";
BA_ "SysSignalName" SG_ 342 ChSysSecyBrkAxleToqValV "ChSysSecyBrkAxleToqValV";
BA_ "CompuMethodName" SG_ 342 ChSysTrBrkAxleToqValV "ChSysTrBrkAxleToqValV";
BA_ "ISignalName" SG_ 342 ChSysTrBrkAxleToqValV "IChSysTrBrkAxleToqValV";
BA_ "LongName" SG_ 342 ChSysTrBrkAxleToqValV "Chassis System transmission Brake Axle Torque Value Valid";
BA_ "SysSignalName" SG_ 342 ChSysTrBrkAxleToqValV "ChSysTrBrkAxleToqValV";
BA_ "CompuMethodName" SG_ 329 IBS_20ms_Group09_CRC "IBS_20ms_Group09_CRC";
BA_ "ISignalName" SG_ 329 IBS_20ms_Group09_CRC "IIBS_20ms_Group09_CRC";
BA_ "LongName" SG_ 329 IBS_20ms_Group09_CRC "IBS_20ms_Group09_CRC";
BA_ "SysSignalName" SG_ 329 IBS_20ms_Group09_CRC "IBS_20ms_Group09_CRC";
BA_ "CompuMethodName" SG_ 329 IBS_20ms_Group09_RC "IBS_20ms_Group09_RC";
BA_ "ISignalName" SG_ 329 IBS_20ms_Group09_RC "IIBS_20ms_Group09_RC";
BA_ "LongName" SG_ 329 IBS_20ms_Group09_RC "IBS_20ms_Group09_RC";
BA_ "SysSignalName" SG_ 329 IBS_20ms_Group09_RC "IBS_20ms_Group09_RC";
BA_ "CompuMethodName" SG_ 329 LDrvnWhlRotlDircn "LDrvnWhlRotlDircn";
BA_ "GenSigStartValue" SG_ 329 LDrvnWhlRotlDircn 3;
BA_ "ISignalName" SG_ 329 LDrvnWhlRotlDircn "ILDrvnWhlRotlDircn";
BA_ "LongName" SG_ 329 LDrvnWhlRotlDircn "Left Driven Wheel Rotational Direction";
BA_ "SysSignalName" SG_ 329 LDrvnWhlRotlDircn "LDrvnWhlRotlDircn";
BA_ "CompuMethodName" SG_ 329 RDrvnWhlRotlDircn "RDrvnWhlRotlDircn";
BA_ "GenSigStartValue" SG_ 329 RDrvnWhlRotlDircn 3;
BA_ "ISignalName" SG_ 329 RDrvnWhlRotlDircn "IRDrvnWhlRotlDircn";
BA_ "LongName" SG_ 329 RDrvnWhlRotlDircn "Right Driven Wheel Rotational Direction";
BA_ "SysSignalName" SG_ 329 RDrvnWhlRotlDircn "RDrvnWhlRotlDircn";
BA_ "CompuMethodName" SG_ 329 WhlGndVelRDrvn "WhlGndVelRDrvn";
BA_ "ISignalName" SG_ 329 WhlGndVelRDrvn "IWhlGndVelRDrvn";
BA_ "LongName" SG_ 329 WhlGndVelRDrvn "Wheel_Ground_Velocity_Right_Driven";
BA_ "SysSignalName" SG_ 329 WhlGndVelRDrvn "WhlGndVelRDrvn";
BA_ "CompuMethodName" SG_ 329 WhlGndVelRDrvnV "WhlGndVelRDrvnV";
BA_ "GenSigStartValue" SG_ 329 WhlGndVelRDrvnV 1;
BA_ "ISignalName" SG_ 329 WhlGndVelRDrvnV "IWhlGndVelRDrvnV";
BA_ "LongName" SG_ 329 WhlGndVelRDrvnV "Wheel_Ground_Velocity_Right_Driven_Validity";
BA_ "SysSignalName" SG_ 329 WhlGndVelRDrvnV "WhlGndVelRDrvnV";
BA_ "CompuMethodName" SG_ 329 WhlGndVelLDrvnV "WhlGndVelLDrvnV";
BA_ "GenSigStartValue" SG_ 329 WhlGndVelLDrvnV 1;
BA_ "ISignalName" SG_ 329 WhlGndVelLDrvnV "IWhlGndVelLDrvnV";
BA_ "LongName" SG_ 329 WhlGndVelLDrvnV "Wheel_Ground_Velocity_Left_Driven_Validity";
BA_ "SysSignalName" SG_ 329 WhlGndVelLDrvnV "WhlGndVelLDrvnV";
BA_ "CompuMethodName" SG_ 329 WhlGndVelLDrvn "WhlGndVelLDrvn";
BA_ "ISignalName" SG_ 329 WhlGndVelLDrvn "IWhlGndVelLDrvn";
BA_ "LongName" SG_ 329 WhlGndVelLDrvn "Wheel_Ground_Velocity_Left_Driven";
BA_ "SysSignalName" SG_ 329 WhlGndVelLDrvn "WhlGndVelLDrvn";
BA_ "CompuMethodName" SG_ 329 RDrvnWhlRotlDircnSdslSts "RDrvnWhlRotlDircnSdslSts";
BA_ "ISignalName" SG_ 329 RDrvnWhlRotlDircnSdslSts "IRDrvnWhlRotlDircnSdslSts";
BA_ "LongName" SG_ 329 RDrvnWhlRotlDircnSdslSts "Right Driven Wheel Rotational Direction Standstill Status";
BA_ "SysSignalName" SG_ 329 RDrvnWhlRotlDircnSdslSts "RDrvnWhlRotlDircnSdslSts";
BA_ "CompuMethodName" SG_ 329 LDrvnWhlRotlDircnSdslSts "LDrvnWhlRotlDircnSdslSts";
BA_ "ISignalName" SG_ 329 LDrvnWhlRotlDircnSdslSts "ILDrvnWhlRotlDircnSdslSts";
BA_ "LongName" SG_ 329 LDrvnWhlRotlDircnSdslSts "Left Driven Wheel Rotational Direction Standstill Status";
BA_ "SysSignalName" SG_ 329 LDrvnWhlRotlDircnSdslSts "LDrvnWhlRotlDircnSdslSts";
BA_ "CompuMethodName" SG_ 329 ChSysTotBrkAxleToqVal "ChSysTotBrkAxleToqVal";
BA_ "ISignalName" SG_ 329 ChSysTotBrkAxleToqVal "IChSysTotBrkAxleToqVal";
BA_ "LongName" SG_ 329 ChSysTotBrkAxleToqVal "Chassis System Total Brake Axle Torque Value";
BA_ "SysSignalName" SG_ 329 ChSysTotBrkAxleToqVal "ChSysTotBrkAxleToqVal";
BA_ "CompuMethodName" SG_ 329 IBS_20ms_Group09_Reserved1 "IBS_20ms_Group09_Reserved1";
BA_ "GenSigStartValue" SG_ 329 IBS_20ms_Group09_Reserved1 1;
BA_ "ISignalName" SG_ 329 IBS_20ms_Group09_Reserved1 "IIBS_20ms_Group09_Reserved1";
BA_ "SysSignalName" SG_ 329 IBS_20ms_Group09_Reserved1 "IBS_20ms_Group09_Reserved1";
BA_ "CompuMethodName" SG_ 329 ChSysTotBrkAxleToqValV "ChSysTotBrkAxleToqValV";
BA_ "ISignalName" SG_ 329 ChSysTotBrkAxleToqValV "IChSysTotBrkAxleToqValV";
BA_ "LongName" SG_ 329 ChSysTotBrkAxleToqValV "Chassis System Total Brake Axle Torque Value Valid";
BA_ "SysSignalName" SG_ 329 ChSysTotBrkAxleToqValV "ChSysTotBrkAxleToqValV";
BA_ "CompuMethodName" SG_ 425 IBS_20ms_Group11_CRC "IBS_20ms_Group11_CRC";
BA_ "ISignalName" SG_ 425 IBS_20ms_Group11_CRC "IIBS_20ms_Group11_CRC";
BA_ "LongName" SG_ 425 IBS_20ms_Group11_CRC "IBS_20ms_Group11_CRC";
BA_ "SysSignalName" SG_ 425 IBS_20ms_Group11_CRC "IBS_20ms_Group11_CRC";
BA_ "CompuMethodName" SG_ 425 IBS_20ms_Group11_RC "IBS_20ms_Group11_RC";
BA_ "ISignalName" SG_ 425 IBS_20ms_Group11_RC "IIBS_20ms_Group11_RC";
BA_ "LongName" SG_ 425 IBS_20ms_Group11_RC "IBS_20ms_Group11_RC";
BA_ "SysSignalName" SG_ 425 IBS_20ms_Group11_RC "IBS_20ms_Group11_RC";
BA_ "CompuMethodName" SG_ 425 IBS_20ms_Group11_Reserved1 "IBS_20ms_Group11_Reserved1";
BA_ "GenSigStartValue" SG_ 425 IBS_20ms_Group11_Reserved1 7;
BA_ "ISignalName" SG_ 425 IBS_20ms_Group11_Reserved1 "IIBS_20ms_Group11_Reserved1";
BA_ "SysSignalName" SG_ 425 IBS_20ms_Group11_Reserved1 "IBS_20ms_Group11_Reserved1";
BA_ "CompuMethodName" SG_ 425 VehSpdAvgNonDrvnV "VehSpdAvgNonDrvnV";
BA_ "ISignalName" SG_ 425 VehSpdAvgNonDrvnV "IVehSpdAvgNonDrvnV";
BA_ "LongName" SG_ 425 VehSpdAvgNonDrvnV "Vehicle Speed Average Non Driven Validity";
BA_ "SysSignalName" SG_ 425 VehSpdAvgNonDrvnV "VehSpdAvgNonDrvnV";
BA_ "CompuMethodName" SG_ 425 VehSpdAvg "VehSpdAvg";
BA_ "ISignalName" SG_ 425 VehSpdAvg "IVehSpdAvg";
BA_ "LongName" SG_ 425 VehSpdAvg "Vehicle_Speed_Average";
BA_ "SysSignalName" SG_ 425 VehSpdAvg "VehSpdAvg";
BA_ "CompuMethodName" SG_ 425 VehSpdAvgV "VehSpdAvgV";
BA_ "ISignalName" SG_ 425 VehSpdAvgV "IVehSpdAvgV";
BA_ "LongName" SG_ 425 VehSpdAvgV "Vehicle_Speed_Average_Validity";
BA_ "SysSignalName" SG_ 425 VehSpdAvgV "VehSpdAvgV";
BA_ "CompuMethodName" SG_ 425 VehSpdAvgDrvn "VehSpdAvgDrvn";
BA_ "ISignalName" SG_ 425 VehSpdAvgDrvn "IVehSpdAvgDrvn";
BA_ "LongName" SG_ 425 VehSpdAvgDrvn "Vehicle Speed Average Driven";
BA_ "SysSignalName" SG_ 425 VehSpdAvgDrvn "VehSpdAvgDrvn";
BA_ "CompuMethodName" SG_ 425 VehSpdAvgDrvnV "VehSpdAvgDrvnV";
BA_ "ISignalName" SG_ 425 VehSpdAvgDrvnV "IVehSpdAvgDrvnV";
BA_ "LongName" SG_ 425 VehSpdAvgDrvnV "Vehicle Speed Average Driven Validity";
BA_ "SysSignalName" SG_ 425 VehSpdAvgDrvnV "VehSpdAvgDrvnV";
BA_ "CompuMethodName" SG_ 425 VehSpdAvgNonDrvn "VehSpdAvgNonDrvn";
BA_ "ISignalName" SG_ 425 VehSpdAvgNonDrvn "IVehSpdAvgNonDrvn";
BA_ "LongName" SG_ 425 VehSpdAvgNonDrvn "Vehicle Speed Average Non Driven";
BA_ "SysSignalName" SG_ 425 VehSpdAvgNonDrvn "VehSpdAvgNonDrvn";
BA_ "CompuMethodName" SG_ 425 VehSpdAvgDrvnSrc "VehSpdAvgDrvnSrc";
BA_ "ISignalName" SG_ 425 VehSpdAvgDrvnSrc "IVehSpdAvgDrvnSrc";
BA_ "LongName" SG_ 425 VehSpdAvgDrvnSrc "Vehicle Speed Average Driven Source";
BA_ "SysSignalName" SG_ 425 VehSpdAvgDrvnSrc "VehSpdAvgDrvnSrc";
BA_ "CompuMethodName" SG_ 339 IBS_20ms_Group12_CRC "IBS_20ms_Group12_CRC";
BA_ "ISignalName" SG_ 339 IBS_20ms_Group12_CRC "IIBS_20ms_Group12_CRC";
BA_ "LongName" SG_ 339 IBS_20ms_Group12_CRC "IBS_20ms_Group12_CRC";
BA_ "SysSignalName" SG_ 339 IBS_20ms_Group12_CRC "IBS_20ms_Group12_CRC";
BA_ "CompuMethodName" SG_ 339 IBS_20ms_Group12_RC "IBS_20ms_Group12_RC";
BA_ "ISignalName" SG_ 339 IBS_20ms_Group12_RC "IIBS_20ms_Group12_RC";
BA_ "LongName" SG_ 339 IBS_20ms_Group12_RC "IBS_20ms_Group12_RC";
BA_ "SysSignalName" SG_ 339 IBS_20ms_Group12_RC "IBS_20ms_Group12_RC";
BA_ "CompuMethodName" SG_ 339 RNonDrvnWhlRotlDircn "RNonDrvnWhlRotlDircn";
BA_ "GenSigStartValue" SG_ 339 RNonDrvnWhlRotlDircn 3;
BA_ "ISignalName" SG_ 339 RNonDrvnWhlRotlDircn "IRNonDrvnWhlRotlDircn";
BA_ "LongName" SG_ 339 RNonDrvnWhlRotlDircn "Right Non Driven Wheel Rotational Direction";
BA_ "SysSignalName" SG_ 339 RNonDrvnWhlRotlDircn "RNonDrvnWhlRotlDircn";
BA_ "CompuMethodName" SG_ 339 LNonDrvnWhlRotlDircn "LNonDrvnWhlRotlDircn";
BA_ "GenSigStartValue" SG_ 339 LNonDrvnWhlRotlDircn 3;
BA_ "ISignalName" SG_ 339 LNonDrvnWhlRotlDircn "ILNonDrvnWhlRotlDircn";
BA_ "LongName" SG_ 339 LNonDrvnWhlRotlDircn "Left Non Driven Wheel Rotational Direction";
BA_ "SysSignalName" SG_ 339 LNonDrvnWhlRotlDircn "LNonDrvnWhlRotlDircn";
BA_ "CompuMethodName" SG_ 339 WhlGndVelRNonDrvn "WhlGndVelRNonDrvn";
BA_ "ISignalName" SG_ 339 WhlGndVelRNonDrvn "IWhlGndVelRNonDrvn";
BA_ "LongName" SG_ 339 WhlGndVelRNonDrvn "Wheel_Ground_Velocity_Right_Non_Driven";
BA_ "SysSignalName" SG_ 339 WhlGndVelRNonDrvn "WhlGndVelRNonDrvn";
BA_ "CompuMethodName" SG_ 339 WhlGndVelRNonDrvnV "WhlGndVelRNonDrvnV";
BA_ "GenSigStartValue" SG_ 339 WhlGndVelRNonDrvnV 1;
BA_ "ISignalName" SG_ 339 WhlGndVelRNonDrvnV "IWhlGndVelRNonDrvnV";
BA_ "LongName" SG_ 339 WhlGndVelRNonDrvnV "Wheel_Ground_Velocity_Right_Non_Driven_Validity";
BA_ "SysSignalName" SG_ 339 WhlGndVelRNonDrvnV "WhlGndVelRNonDrvnV";
BA_ "CompuMethodName" SG_ 339 WhlGndVelLNonDrvnV "WhlGndVelLNonDrvnV";
BA_ "GenSigStartValue" SG_ 339 WhlGndVelLNonDrvnV 1;
BA_ "ISignalName" SG_ 339 WhlGndVelLNonDrvnV "IWhlGndVelLNonDrvnV";
BA_ "LongName" SG_ 339 WhlGndVelLNonDrvnV "Wheel_Ground_Velocity_Left_Non_Driven_Validity";
BA_ "SysSignalName" SG_ 339 WhlGndVelLNonDrvnV "WhlGndVelLNonDrvnV";
BA_ "CompuMethodName" SG_ 339 WhlGndVelLNonDrvn "WhlGndVelLNonDrvn";
BA_ "ISignalName" SG_ 339 WhlGndVelLNonDrvn "IWhlGndVelLNonDrvn";
BA_ "LongName" SG_ 339 WhlGndVelLNonDrvn "Wheel_Ground_Velocity_Left_Non_Driven";
BA_ "SysSignalName" SG_ 339 WhlGndVelLNonDrvn "WhlGndVelLNonDrvn";
BA_ "CompuMethodName" SG_ 339 RNonDrvnWhlRotlDircnSdslSts "RNonDrvnWhlRotlDircnSdslSts";
BA_ "ISignalName" SG_ 339 RNonDrvnWhlRotlDircnSdslSts "IRNonDrvnWhlRotlDircnSdslSts";
BA_ "LongName" SG_ 339 RNonDrvnWhlRotlDircnSdslSts "Right Non Driven Wheel Rotational Direction Standstill Status";
BA_ "SysSignalName" SG_ 339 RNonDrvnWhlRotlDircnSdslSts "RNonDrvnWhlRotlDircnSdslSts";
BA_ "CompuMethodName" SG_ 339 LNonDrvnWhlRotlDircnSdslSts "LNonDrvnWhlRotlDircnSdslSts";
BA_ "ISignalName" SG_ 339 LNonDrvnWhlRotlDircnSdslSts "ILNonDrvnWhlRotlDircnSdslSts";
BA_ "LongName" SG_ 339 LNonDrvnWhlRotlDircnSdslSts "Left Non Driven Wheel Rotational Direction Standstill Status";
BA_ "SysSignalName" SG_ 339 LNonDrvnWhlRotlDircnSdslSts "LNonDrvnWhlRotlDircnSdslSts";
BA_ "CompuMethodName" SG_ 339 IBS_20ms_Group12_Reserved1 "IBS_20ms_Group12_Reserved1";
BA_ "GenSigStartValue" SG_ 339 IBS_20ms_Group12_Reserved1 255;
BA_ "ISignalName" SG_ 339 IBS_20ms_Group12_Reserved1 "IIBS_20ms_Group12_Reserved1";
BA_ "SysSignalName" SG_ 339 IBS_20ms_Group12_Reserved1 "IBS_20ms_Group12_Reserved1";
BA_ "CompuMethodName" SG_ 339 IBS_20ms_Group12_Reserved2 "IBS_20ms_Group12_Reserved2";
BA_ "GenSigStartValue" SG_ 339 IBS_20ms_Group12_Reserved2 255;
BA_ "ISignalName" SG_ 339 IBS_20ms_Group12_Reserved2 "IIBS_20ms_Group12_Reserved2";
BA_ "SysSignalName" SG_ 339 IBS_20ms_Group12_Reserved2 "IBS_20ms_Group12_Reserved2";
BA_ "CompuMethodName" SG_ 1272 IBS_NM_BSMtoRMS_CHCANFD "IBS_NM_BSMtoRMS_CHCANFD";
BA_ "ISignalName" SG_ 1272 IBS_NM_BSMtoRMS_CHCANFD "IIBS_NM_BSMtoRMS_CHCANFD";
BA_ "LongName" SG_ 1272 IBS_NM_BSMtoRMS_CHCANFD "IBS_NM_BSMtoRMS_CHCANFD";
BA_ "SysSignalName" SG_ 1272 IBS_NM_BSMtoRMS_CHCANFD "IBS_NM_BSMtoRMS_CHCANFD";
BA_ "CompuMethodName" SG_ 1272 IBS_NM_PBSMtoRMS_CHCANFD "IBS_NM_PBSMtoRMS_CHCANFD";
BA_ "ISignalName" SG_ 1272 IBS_NM_PBSMtoRMS_CHCANFD "IIBS_NM_PBSMtoRMS_CHCANFD";
BA_ "LongName" SG_ 1272 IBS_NM_PBSMtoRMS_CHCANFD "IBS_NM_PBSMtoRMS_CHCANFD";
BA_ "SysSignalName" SG_ 1272 IBS_NM_PBSMtoRMS_CHCANFD "IBS_NM_PBSMtoRMS_CHCANFD";
BA_ "CompuMethodName" SG_ 1272 IBS_NM_RMStoNOS_CHCANFD "IBS_NM_RMStoNOS_CHCANFD";
BA_ "ISignalName" SG_ 1272 IBS_NM_RMStoNOS_CHCANFD "IIBS_NM_RMStoNOS_CHCANFD";
BA_ "LongName" SG_ 1272 IBS_NM_RMStoNOS_CHCANFD "IBS_NM_RMStoNOS_CHCANFD";
BA_ "SysSignalName" SG_ 1272 IBS_NM_RMStoNOS_CHCANFD "IBS_NM_RMStoNOS_CHCANFD";
BA_ "CompuMethodName" SG_ 1272 IBS_NM_RSStoNOS_CHCANFD "IBS_NM_RSStoNOS_CHCANFD";
BA_ "ISignalName" SG_ 1272 IBS_NM_RSStoNOS_CHCANFD "IIBS_NM_RSStoNOS_CHCANFD";
BA_ "LongName" SG_ 1272 IBS_NM_RSStoNOS_CHCANFD "IBS_NM_RSStoNOS_CHCANFD";
BA_ "SysSignalName" SG_ 1272 IBS_NM_RSStoNOS_CHCANFD "IBS_NM_RSStoNOS_CHCANFD";
BA_ "CompuMethodName" SG_ 1272 IBS_NM_RSStoRMS_CHCANFD "IBS_NM_RSStoRMS_CHCANFD";
BA_ "ISignalName" SG_ 1272 IBS_NM_RSStoRMS_CHCANFD "IIBS_NM_RSStoRMS_CHCANFD";
BA_ "LongName" SG_ 1272 IBS_NM_RSStoRMS_CHCANFD "IBS_NM_RSStoRMS_CHCANFD";
BA_ "SysSignalName" SG_ 1272 IBS_NM_RSStoRMS_CHCANFD "IBS_NM_RSStoRMS_CHCANFD";
BA_ "CompuMethodName" SG_ 1272 IBS_NM_NOStoRMS_CHCANFD "IBS_NM_NOStoRMS_CHCANFD";
BA_ "ISignalName" SG_ 1272 IBS_NM_NOStoRMS_CHCANFD "IIBS_NM_NOStoRMS_CHCANFD";
BA_ "LongName" SG_ 1272 IBS_NM_NOStoRMS_CHCANFD "IBS_NM_NOStoRMS_CHCANFD";
BA_ "SysSignalName" SG_ 1272 IBS_NM_NOStoRMS_CHCANFD "IBS_NM_NOStoRMS_CHCANFD";
BA_ "CompuMethodName" SG_ 1272 IBS_NM_NOSSta_CHCANFD "IBS_NM_NOSSta_CHCANFD";
BA_ "ISignalName" SG_ 1272 IBS_NM_NOSSta_CHCANFD "IIBS_NM_NOSSta_CHCANFD";
BA_ "LongName" SG_ 1272 IBS_NM_NOSSta_CHCANFD "IBS_NM_NOSSta_CHCANFD";
BA_ "SysSignalName" SG_ 1272 IBS_NM_NOSSta_CHCANFD "IBS_NM_NOSSta_CHCANFD";
BA_ "CompuMethodName" SG_ 1272 IBS_NM_RMSSta_CHCANFD "IBS_NM_RMSSta_CHCANFD";
BA_ "ISignalName" SG_ 1272 IBS_NM_RMSSta_CHCANFD "IIBS_NM_RMSSta_CHCANFD";
BA_ "LongName" SG_ 1272 IBS_NM_RMSSta_CHCANFD "IBS_NM_RMSSta_CHCANFD";
BA_ "SysSignalName" SG_ 1272 IBS_NM_RMSSta_CHCANFD "IBS_NM_RMSSta_CHCANFD";
BA_ "CompuMethodName" SG_ 1272 IBS_NWI_CHCANFD "IBS_NWI_CHCANFD";
BA_ "ISignalName" SG_ 1272 IBS_NWI_CHCANFD "IIBS_NWI_CHCANFD";
BA_ "LongName" SG_ 1272 IBS_NWI_CHCANFD "IBS CHCANFD Network_Wakeup_Indication";
BA_ "SysSignalName" SG_ 1272 IBS_NWI_CHCANFD "IBS_NWI_CHCANFD";
BA_ "CompuMethodName" SG_ 1272 IBS_NOI_CHCANFD "IBS_NOI_CHCANFD";
BA_ "ISignalName" SG_ 1272 IBS_NOI_CHCANFD "IIBS_NOI_CHCANFD";
BA_ "LongName" SG_ 1272 IBS_NOI_CHCANFD "IBS CHCANFD Network Operation Indication";
BA_ "SysSignalName" SG_ 1272 IBS_NOI_CHCANFD "IBS_NOI_CHCANFD";
BA_ "CompuMethodName" SG_ 1272 IBS_NKI_CHCANFD "IBS_NKI_CHCANFD";
BA_ "ISignalName" SG_ 1272 IBS_NKI_CHCANFD "IIBS_NKI_CHCANFD";
BA_ "LongName" SG_ 1272 IBS_NKI_CHCANFD "IBS CHCANFD Network Keep Indication";
BA_ "SysSignalName" SG_ 1272 IBS_NKI_CHCANFD "IBS_NKI_CHCANFD";
BA_ "CompuMethodName" SG_ 283 WhlRghRoadV "WhlRghRoadV";
BA_ "ISignalName" SG_ 283 WhlRghRoadV "IWhlRghRoadV";
BA_ "LongName" SG_ 283 WhlRghRoadV "Wheel Rough Road Validity";
BA_ "SysSignalName" SG_ 283 WhlRghRoadV "WhlRghRoadV";
BA_ "CompuMethodName" SG_ 283 SCSMdSts "SCSMdSts";
BA_ "ISignalName" SG_ 283 SCSMdSts "ISCSMdSts";
BA_ "SysSignalName" SG_ 283 SCSMdSts "SCSMdSts";
BA_ "CompuMethodName" SG_ 283 BrkSysHillRlbkCtrlAvlbl "BrkSysHillRlbkCtrlAvlbl";
BA_ "ISignalName" SG_ 283 BrkSysHillRlbkCtrlAvlbl "IBrkSysHillRlbkCtrlAvlbl";
BA_ "LongName" SG_ 283 BrkSysHillRlbkCtrlAvlbl "Brake System Hill Rollback Control Available";
BA_ "SysSignalName" SG_ 283 BrkSysHillRlbkCtrlAvlbl "BrkSysHillRlbkCtrlAvlbl";
BA_ "CompuMethodName" SG_ 283 BrkSysHillRlbkCtrlSts "BrkSysHillRlbkCtrlSts";
BA_ "ISignalName" SG_ 283 BrkSysHillRlbkCtrlSts "IBrkSysHillRlbkCtrlSts";
BA_ "LongName" SG_ 283 BrkSysHillRlbkCtrlSts "Brake System Hill Rollback Control Status";
BA_ "SysSignalName" SG_ 283 BrkSysHillRlbkCtrlSts "BrkSysHillRlbkCtrlSts";
BA_ "CompuMethodName" SG_ 283 WhlRghRoad "WhlRghRoad";
BA_ "ISignalName" SG_ 283 WhlRghRoad "IWhlRghRoad";
BA_ "LongName" SG_ 283 WhlRghRoad "Wheel Rough Road";
BA_ "SysSignalName" SG_ 283 WhlRghRoad "WhlRghRoad";
BA_ "CompuMethodName" SG_ 507 IBS_ZONE_20ms_Group08_CRC "IBS_ZONE_20ms_Group08_CRC";
BA_ "ISignalName" SG_ 507 IBS_ZONE_20ms_Group08_CRC "IIBS_ZONE_20ms_Group08_CRC";
BA_ "LongName" SG_ 507 IBS_ZONE_20ms_Group08_CRC "IBS_ZONE_20ms_Group08_CRC";
BA_ "SysSignalName" SG_ 507 IBS_ZONE_20ms_Group08_CRC "IBS_ZONE_20ms_Group08_CRC";
BA_ "CompuMethodName" SG_ 507 IBS_ZONE_20ms_Group08_RC "IBS_ZONE_20ms_Group08_RC";
BA_ "ISignalName" SG_ 507 IBS_ZONE_20ms_Group08_RC "IIBS_ZONE_20ms_Group08_RC";
BA_ "LongName" SG_ 507 IBS_ZONE_20ms_Group08_RC "IBS_ZONE_20ms_Group08_RC";
BA_ "SysSignalName" SG_ 507 IBS_ZONE_20ms_Group08_RC "IBS_ZONE_20ms_Group08_RC";
BA_ "CompuMethodName" SG_ 507 IBS_ZONE_20ms_Group08_Reserved1 "IBS_ZONE_20ms_Group08_Reserved1";
BA_ "GenSigStartValue" SG_ 507 IBS_ZONE_20ms_Group08_Reserved1 1;
BA_ "ISignalName" SG_ 507 IBS_ZONE_20ms_Group08_Reserved1 "IIBS_ZONE_20ms_Group08_Reserved1";
BA_ "SysSignalName" SG_ 507 IBS_ZONE_20ms_Group08_Reserved1 "IBS_ZONE_20ms_Group08_Reserved1";
BA_ "CompuMethodName" SG_ 507 EPBAppcnSts_M "EPBAppcnSts_M";
BA_ "GenSigStartValue" SG_ 507 EPBAppcnSts_M 2;
BA_ "ISignalName" SG_ 507 EPBAppcnSts_M "IEPBAppcnSts_M";
BA_ "LongName" SG_ 507 EPBAppcnSts_M "Electric Park Brake Application Status Master";
BA_ "SysSignalName" SG_ 507 EPBAppcnSts_M "EPBAppcnSts_M";
BA_ "CompuMethodName" SG_ 507 IBSRespAccToqVal "IBSRespAccToqVal";
BA_ "ISignalName" SG_ 507 IBSRespAccToqVal "IIBSRespAccToqVal";
BA_ "LongName" SG_ 507 IBSRespAccToqVal "IBS Response Acceleration Request Torque Value";
BA_ "SysSignalName" SG_ 507 IBSRespAccToqVal "IBSRespAccToqVal";
BA_ "CompuMethodName" SG_ 507 IBS_ZONE_20ms_Group08_Reserved2 "IBS_ZONE_20ms_Group08_Reserved2";
BA_ "GenSigStartValue" SG_ 507 IBS_ZONE_20ms_Group08_Reserved2 255;
BA_ "ISignalName" SG_ 507 IBS_ZONE_20ms_Group08_Reserved2 "IIBS_ZONE_20ms_Group08_Reserved2";
BA_ "SysSignalName" SG_ 507 IBS_ZONE_20ms_Group08_Reserved2 "IBS_ZONE_20ms_Group08_Reserved2";
BA_ "CompuMethodName" SG_ 507 IBS_ZONE_20ms_Group08_Reserved3 "IBS_ZONE_20ms_Group08_Reserved3";
BA_ "GenSigStartValue" SG_ 507 IBS_ZONE_20ms_Group08_Reserved3 255;
BA_ "ISignalName" SG_ 507 IBS_ZONE_20ms_Group08_Reserved3 "IIBS_ZONE_20ms_Group08_Reserved3";
BA_ "SysSignalName" SG_ 507 IBS_ZONE_20ms_Group08_Reserved3 "IBS_ZONE_20ms_Group08_Reserved3";
BA_ "CompuMethodName" SG_ 507 IBS_ZONE_20ms_Group08_Reserved4 "IBS_ZONE_20ms_Group08_Reserved4";
BA_ "GenSigStartValue" SG_ 507 IBS_ZONE_20ms_Group08_Reserved4 255;
BA_ "ISignalName" SG_ 507 IBS_ZONE_20ms_Group08_Reserved4 "IIBS_ZONE_20ms_Group08_Reserved4";
BA_ "SysSignalName" SG_ 507 IBS_ZONE_20ms_Group08_Reserved4 "IBS_ZONE_20ms_Group08_Reserved4";
BA_ "CompuMethodName" SG_ 507 BrkBstFnSts "BrkBstFnSts";
BA_ "ISignalName" SG_ 507 BrkBstFnSts "IBrkBstFnSts";
BA_ "LongName" SG_ 507 BrkBstFnSts "Brake Boost Function Status";
BA_ "SysSignalName" SG_ 507 BrkBstFnSts "BrkBstFnSts";
BA_ "CompuMethodName" SG_ 507 IBS_ZONE_20ms_Group08_Reserved5 "IBS_ZONE_20ms_Group08_Reserved5";
BA_ "GenSigStartValue" SG_ 507 IBS_ZONE_20ms_Group08_Reserved5 31;
BA_ "ISignalName" SG_ 507 IBS_ZONE_20ms_Group08_Reserved5 "IIBS_ZONE_20ms_Group08_Reserved5";
BA_ "SysSignalName" SG_ 507 IBS_ZONE_20ms_Group08_Reserved5 "IBS_ZONE_20ms_Group08_Reserved5";
BA_ "CompuMethodName" SG_ 382 ICBAD_20ms_Group07_CRC "ICBAD_20ms_Group07_CRC";
BA_ "ISignalName" SG_ 382 ICBAD_20ms_Group07_CRC "IICBAD_20ms_Group07_CRC";
BA_ "LongName" SG_ 382 ICBAD_20ms_Group07_CRC "ICBAD_20ms_Group07_CRC";
BA_ "SysSignalName" SG_ 382 ICBAD_20ms_Group07_CRC "ICBAD_20ms_Group07_CRC";
BA_ "CompuMethodName" SG_ 382 ICBAD_20ms_Group07_RC "ICBAD_20ms_Group07_RC";
BA_ "ISignalName" SG_ 382 ICBAD_20ms_Group07_RC "IICBAD_20ms_Group07_RC";
BA_ "LongName" SG_ 382 ICBAD_20ms_Group07_RC "ICBAD_20ms_Group07_RC";
BA_ "SysSignalName" SG_ 382 ICBAD_20ms_Group07_RC "ICBAD_20ms_Group07_RC";
BA_ "CompuMethodName" SG_ 382 ACCSdslReq "ACCSdslReq";
BA_ "ISignalName" SG_ 382 ACCSdslReq "IACCSdslReq";
BA_ "LongName" SG_ 382 ACCSdslReq "Adaptive Cruise Control Standstill Request";
BA_ "SysSignalName" SG_ 382 ACCSdslReq "ACCSdslReq";
BA_ "CompuMethodName" SG_ 382 ACCGoReq "ACCGoReq";
BA_ "ISignalName" SG_ 382 ACCGoReq "IACCGoReq";
BA_ "LongName" SG_ 382 ACCGoReq "Adaptive Cruise Control Go Request";
BA_ "SysSignalName" SG_ 382 ACCGoReq "ACCGoReq";
BA_ "CompuMethodName" SG_ 382 ACCAccReqSts_CH "ACCAccReqSts_CH";
BA_ "ISignalName" SG_ 382 ACCAccReqSts_CH "IACCAccReqSts_CH";
BA_ "LongName" SG_ 382 ACCAccReqSts_CH "Adaptive Cruise Control Acceleration Request Status";
BA_ "SysSignalName" SG_ 382 ACCAccReqSts_CH "ACCAccReqSts_CH";
BA_ "CompuMethodName" SG_ 382 ACCAccReqVal "ACCAccReqVal";
BA_ "GenSigStartValue" SG_ 382 ACCAccReqVal 1713;
BA_ "ISignalName" SG_ 382 ACCAccReqVal "IACCAccReqVal";
BA_ "LongName" SG_ 382 ACCAccReqVal "Adaptive Cruise Control Acceleration Request Value";
BA_ "SysSignalName" SG_ 382 ACCAccReqVal "ACCAccReqVal";
BA_ "CompuMethodName" SG_ 382 APAEPBOPReq "APAEPBOPReq";
BA_ "ISignalName" SG_ 382 APAEPBOPReq "IAPAEPBOPReq";
BA_ "LongName" SG_ 382 APAEPBOPReq "Advanced Park Assist Electric Park Brake Operation Request";
BA_ "SysSignalName" SG_ 382 APAEPBOPReq "APAEPBOPReq";
BA_ "CompuMethodName" SG_ 382 ACCSysFltSts "ACCSysFltSts";
BA_ "ISignalName" SG_ 382 ACCSysFltSts "IACCSysFltSts";
BA_ "LongName" SG_ 382 ACCSysFltSts "Adaptive Cruise Control System Fault Status";
BA_ "SysSignalName" SG_ 382 ACCSysFltSts "ACCSysFltSts";
BA_ "CompuMethodName" SG_ 382 AIPkgAPASCSAcclReqVal "AIPkgAPASCSAcclReqVal";
BA_ "ISignalName" SG_ 382 AIPkgAPASCSAcclReqVal "IAIPkgAPASCSAcclReqVal";
BA_ "LongName" SG_ 382 AIPkgAPASCSAcclReqVal "Ai Parking APA Acceleration Request Value";
BA_ "SysSignalName" SG_ 382 AIPkgAPASCSAcclReqVal "AIPkgAPASCSAcclReqVal";
BA_ "CompuMethodName" SG_ 382 ACCSysSts "ACCSysSts";
BA_ "ISignalName" SG_ 382 ACCSysSts "IACCSysSts";
BA_ "LongName" SG_ 382 ACCSysSts "Adaptive Cruise Control System Status";
BA_ "SysSignalName" SG_ 382 ACCSysSts "ACCSysSts";
BA_ "CompuMethodName" SG_ 382 APASCSAcclReqSts "APASCSAcclReqSts";
BA_ "ISignalName" SG_ 382 APASCSAcclReqSts "IAPASCSAcclReqSts";
BA_ "LongName" SG_ 382 APASCSAcclReqSts "Advanced Park Assist Stability Control System Acceleration Request Status";
BA_ "SysSignalName" SG_ 382 APASCSAcclReqSts "APASCSAcclReqSts";
BA_ "CompuMethodName" SG_ 382 APAEPBOPReqV "APAEPBOPReqV";
BA_ "ISignalName" SG_ 382 APAEPBOPReqV "IAPAEPBOPReqV";
BA_ "LongName" SG_ 382 APAEPBOPReqV "Advanced Park Assist Electric Park Brake Operation Request Validity";
BA_ "SysSignalName" SG_ 382 APAEPBOPReqV "APAEPBOPReqV";
BA_ "CompuMethodName" SG_ 382 AutodDrvngSysSCSSdslReqV "AutodDrvngSysSCSSdslReqV";
BA_ "ISignalName" SG_ 382 AutodDrvngSysSCSSdslReqV "IAutodDrvngSysSCSSdslReqV";
BA_ "LongName" SG_ 382 AutodDrvngSysSCSSdslReqV "Automated Driving System Stability Control System Standstill Request Validity";
BA_ "SysSignalName" SG_ 382 AutodDrvngSysSCSSdslReqV "AutodDrvngSysSCSSdslReqV";
BA_ "CompuMethodName" SG_ 382 AutodDrvngSysSCSSdslReq "AutodDrvngSysSCSSdslReq";
BA_ "ISignalName" SG_ 382 AutodDrvngSysSCSSdslReq "IAutodDrvngSysSCSSdslReq";
BA_ "LongName" SG_ 382 AutodDrvngSysSCSSdslReq "Automated Driving System Stability Control System Standstill Request";
BA_ "SysSignalName" SG_ 382 AutodDrvngSysSCSSdslReq "AutodDrvngSysSCSSdslReq";
BA_ "CompuMethodName" SG_ 382 AutodDrvngSysEmgcBrkReqV "AutodDrvngSysEmgcBrkReqV";
BA_ "ISignalName" SG_ 382 AutodDrvngSysEmgcBrkReqV "IAutodDrvngSysEmgcBrkReqV";
BA_ "LongName" SG_ 382 AutodDrvngSysEmgcBrkReqV "Automated_Driving_System_Emergency_Brake_Request_Validity";
BA_ "SysSignalName" SG_ 382 AutodDrvngSysEmgcBrkReqV "AutodDrvngSysEmgcBrkReqV";
BA_ "CompuMethodName" SG_ 382 AutodDrvngSysEmgcBrkReq "AutodDrvngSysEmgcBrkReq";
BA_ "ISignalName" SG_ 382 AutodDrvngSysEmgcBrkReq "IAutodDrvngSysEmgcBrkReq";
BA_ "LongName" SG_ 382 AutodDrvngSysEmgcBrkReq "Automated_Driving_System_Emergency_Brake_Request";
BA_ "SysSignalName" SG_ 382 AutodDrvngSysEmgcBrkReq "AutodDrvngSysEmgcBrkReq";
BA_ "CompuMethodName" SG_ 382 ICBAD_20ms_Group07_Reserved1 "ICBAD_20ms_Group07_Reserved1";
BA_ "GenSigStartValue" SG_ 382 ICBAD_20ms_Group07_Reserved1 15;
BA_ "ISignalName" SG_ 382 ICBAD_20ms_Group07_Reserved1 "IICBAD_20ms_Group07_Reserved1";
BA_ "SysSignalName" SG_ 382 ICBAD_20ms_Group07_Reserved1 "ICBAD_20ms_Group07_Reserved1";
BA_ "CompuMethodName" SG_ 382 AutodDrvngSysSCSDrvOffReqV "AutodDrvngSysSCSDrvOffReqV";
BA_ "ISignalName" SG_ 382 AutodDrvngSysSCSDrvOffReqV "IAutodDrvngSysSCSDrvOffReqV";
BA_ "LongName" SG_ 382 AutodDrvngSysSCSDrvOffReqV "Automated Driving System Stability Control System Drive Off Request Validity";
BA_ "SysSignalName" SG_ 382 AutodDrvngSysSCSDrvOffReqV "AutodDrvngSysSCSDrvOffReqV";
BA_ "CompuMethodName" SG_ 382 AutodDrvngSysSCSDrvOffReq "AutodDrvngSysSCSDrvOffReq";
BA_ "ISignalName" SG_ 382 AutodDrvngSysSCSDrvOffReq "IAutodDrvngSysSCSDrvOffReq";
BA_ "LongName" SG_ 382 AutodDrvngSysSCSDrvOffReq "Automated Driving System Stability Control System Drive Off Request";
BA_ "SysSignalName" SG_ 382 AutodDrvngSysSCSDrvOffReq "AutodDrvngSysSCSDrvOffReq";
BA_ "CompuMethodName" SG_ 382 AutodDrvngSysMdReqV "AutodDrvngSysMdReqV";
BA_ "ISignalName" SG_ 382 AutodDrvngSysMdReqV "IAutodDrvngSysMdReqV";
BA_ "LongName" SG_ 382 AutodDrvngSysMdReqV "Automated Driving System Mode Request Validity";
BA_ "SysSignalName" SG_ 382 AutodDrvngSysMdReqV "AutodDrvngSysMdReqV";
BA_ "CompuMethodName" SG_ 382 AutodDrvngSysMdReq "AutodDrvngSysMdReq";
BA_ "ISignalName" SG_ 382 AutodDrvngSysMdReq "IAutodDrvngSysMdReq";
BA_ "LongName" SG_ 382 AutodDrvngSysMdReq "Automated Driving System Mode Request";
BA_ "SysSignalName" SG_ 382 AutodDrvngSysMdReq "AutodDrvngSysMdReq";
BA_ "CompuMethodName" SG_ 382 AutodDrvngSysFlrStsV "AutodDrvngSysFlrStsV";
BA_ "ISignalName" SG_ 382 AutodDrvngSysFlrStsV "IAutodDrvngSysFlrStsV";
BA_ "LongName" SG_ 382 AutodDrvngSysFlrStsV "Automated Driving System Failure Status Validity";
BA_ "SysSignalName" SG_ 382 AutodDrvngSysFlrStsV "AutodDrvngSysFlrStsV";
BA_ "CompuMethodName" SG_ 382 AutodDrvngSysFlrSts "AutodDrvngSysFlrSts";
BA_ "ISignalName" SG_ 382 AutodDrvngSysFlrSts "IAutodDrvngSysFlrSts";
BA_ "LongName" SG_ 382 AutodDrvngSysFlrSts "Automated Driving System Failure Status";
BA_ "SysSignalName" SG_ 382 AutodDrvngSysFlrSts "AutodDrvngSysFlrSts";
BA_ "CompuMethodName" SG_ 385 ICBAD_20ms_Group09_CRC "ICBAD_20ms_Group09_CRC";
BA_ "ISignalName" SG_ 385 ICBAD_20ms_Group09_CRC "IICBAD_20ms_Group09_CRC";
BA_ "LongName" SG_ 385 ICBAD_20ms_Group09_CRC "ICBAD_20ms_Group09_CRC";
BA_ "SysSignalName" SG_ 385 ICBAD_20ms_Group09_CRC "ICBAD_20ms_Group09_CRC";
BA_ "CompuMethodName" SG_ 385 ICBAD_20ms_Group09_RC "ICBAD_20ms_Group09_RC";
BA_ "ISignalName" SG_ 385 ICBAD_20ms_Group09_RC "IICBAD_20ms_Group09_RC";
BA_ "LongName" SG_ 385 ICBAD_20ms_Group09_RC "ICBAD_20ms_Group09_RC";
BA_ "SysSignalName" SG_ 385 ICBAD_20ms_Group09_RC "ICBAD_20ms_Group09_RC";
BA_ "CompuMethodName" SG_ 385 NSAReqAVMDis "NSAReqAVMDis";
BA_ "ISignalName" SG_ 385 NSAReqAVMDis "INSAReqAVMDis";
BA_ "LongName" SG_ 385 NSAReqAVMDis "NSA Request AVM Display";
BA_ "SysSignalName" SG_ 385 NSAReqAVMDis "NSAReqAVMDis";
BA_ "CompuMethodName" SG_ 385 NSADisFucSts "NSADisFucSts";
BA_ "ISignalName" SG_ 385 NSADisFucSts "INSADisFucSts";
BA_ "LongName" SG_ 385 NSADisFucSts "NSA Display Function Status";
BA_ "SysSignalName" SG_ 385 NSADisFucSts "NSADisFucSts";
BA_ "CompuMethodName" SG_ 385 ICBAD_20ms_Group09_Reserved1 "ICBAD_20ms_Group09_Reserved1";
BA_ "GenSigStartValue" SG_ 385 ICBAD_20ms_Group09_Reserved1 3;
BA_ "ISignalName" SG_ 385 ICBAD_20ms_Group09_Reserved1 "IICBAD_20ms_Group09_Reserved1";
BA_ "SysSignalName" SG_ 385 ICBAD_20ms_Group09_Reserved1 "ICBAD_20ms_Group09_Reserved1";
BA_ "CompuMethodName" SG_ 385 NSABacSysSts "NSABacSysSts";
BA_ "ISignalName" SG_ 385 NSABacSysSts "INSABacSysSts";
BA_ "LongName" SG_ 385 NSABacSysSts "NSA Backward Systerm Status";
BA_ "SysSignalName" SG_ 385 NSABacSysSts "NSABacSysSts";
BA_ "CompuMethodName" SG_ 385 NSAForSysSts "NSAForSysSts";
BA_ "ISignalName" SG_ 385 NSAForSysSts "INSAForSysSts";
BA_ "LongName" SG_ 385 NSAForSysSts "NSA Forward Systerm Status";
BA_ "SysSignalName" SG_ 385 NSAForSysSts "NSAForSysSts";
BA_ "CompuMethodName" SG_ 385 ICBAD_20ms_Group09_Reserved2 "ICBAD_20ms_Group09_Reserved2";
BA_ "GenSigStartValue" SG_ 385 ICBAD_20ms_Group09_Reserved2 255;
BA_ "ISignalName" SG_ 385 ICBAD_20ms_Group09_Reserved2 "IICBAD_20ms_Group09_Reserved2";
BA_ "SysSignalName" SG_ 385 ICBAD_20ms_Group09_Reserved2 "ICBAD_20ms_Group09_Reserved2";
BA_ "CompuMethodName" SG_ 385 ICBAD_20ms_Group09_Reserved3 "ICBAD_20ms_Group09_Reserved3";
BA_ "GenSigStartValue" SG_ 385 ICBAD_20ms_Group09_Reserved3 255;
BA_ "ISignalName" SG_ 385 ICBAD_20ms_Group09_Reserved3 "IICBAD_20ms_Group09_Reserved3";
BA_ "SysSignalName" SG_ 385 ICBAD_20ms_Group09_Reserved3 "ICBAD_20ms_Group09_Reserved3";
BA_ "CompuMethodName" SG_ 385 ICBAD_20ms_Group09_Reserved4 "ICBAD_20ms_Group09_Reserved4";
BA_ "GenSigStartValue" SG_ 385 ICBAD_20ms_Group09_Reserved4 255;
BA_ "ISignalName" SG_ 385 ICBAD_20ms_Group09_Reserved4 "IICBAD_20ms_Group09_Reserved4";
BA_ "SysSignalName" SG_ 385 ICBAD_20ms_Group09_Reserved4 "ICBAD_20ms_Group09_Reserved4";
BA_ "CompuMethodName" SG_ 385 ICBAD_20ms_Group09_Reserved5 "ICBAD_20ms_Group09_Reserved5";
BA_ "GenSigStartValue" SG_ 385 ICBAD_20ms_Group09_Reserved5 255;
BA_ "ISignalName" SG_ 385 ICBAD_20ms_Group09_Reserved5 "IICBAD_20ms_Group09_Reserved5";
BA_ "SysSignalName" SG_ 385 ICBAD_20ms_Group09_Reserved5 "ICBAD_20ms_Group09_Reserved5";
BA_ "CompuMethodName" SG_ 385 ICBAD_20ms_Group09_Reserved6 "ICBAD_20ms_Group09_Reserved6";
BA_ "GenSigStartValue" SG_ 385 ICBAD_20ms_Group09_Reserved6 255;
BA_ "ISignalName" SG_ 385 ICBAD_20ms_Group09_Reserved6 "IICBAD_20ms_Group09_Reserved6";
BA_ "SysSignalName" SG_ 385 ICBAD_20ms_Group09_Reserved6 "ICBAD_20ms_Group09_Reserved6";
BA_ "CompuMethodName" SG_ 343 ICBAD_20ms_Group46_CRC "ICBAD_20ms_Group46_CRC";
BA_ "ISignalName" SG_ 343 ICBAD_20ms_Group46_CRC "IICBAD_20ms_Group46_CRC";
BA_ "LongName" SG_ 343 ICBAD_20ms_Group46_CRC "ICBAD_20ms_Group46_CRC";
BA_ "SysSignalName" SG_ 343 ICBAD_20ms_Group46_CRC "ICBAD_20ms_Group46_CRC";
BA_ "CompuMethodName" SG_ 343 ICBAD_20ms_Group46_RC "ICBAD_20ms_Group46_RC";
BA_ "ISignalName" SG_ 343 ICBAD_20ms_Group46_RC "IICBAD_20ms_Group46_RC";
BA_ "LongName" SG_ 343 ICBAD_20ms_Group46_RC "ICBAD_20ms_Group46_RC";
BA_ "SysSignalName" SG_ 343 ICBAD_20ms_Group46_RC "ICBAD_20ms_Group46_RC";
BA_ "CompuMethodName" SG_ 343 AEBPrflReq "AEBPrflReq";
BA_ "ISignalName" SG_ 343 AEBPrflReq "IAEBPrflReq";
BA_ "LongName" SG_ 343 AEBPrflReq "Autonomous Emergency Braking Prefill Request";
BA_ "SysSignalName" SG_ 343 AEBPrflReq "AEBPrflReq";
BA_ "CompuMethodName" SG_ 343 AEBSysSts "AEBSysSts";
BA_ "GenSigStartValue" SG_ 343 AEBSysSts 1;
BA_ "ISignalName" SG_ 343 AEBSysSts "IAEBSysSts";
BA_ "LongName" SG_ 343 AEBSysSts "Autonomous Emergency Braking System Status";
BA_ "SysSignalName" SG_ 343 AEBSysSts "AEBSysSts";
BA_ "CompuMethodName" SG_ 343 AEBDclReqSts "AEBDclReqSts";
BA_ "ISignalName" SG_ 343 AEBDclReqSts "IAEBDclReqSts";
BA_ "LongName" SG_ 343 AEBDclReqSts "Autonomous Emergency Braking Deceleration Request Status";
BA_ "SysSignalName" SG_ 343 AEBDclReqSts "AEBDclReqSts";
BA_ "CompuMethodName" SG_ 343 AEBBrkJerkLvlReq "AEBBrkJerkLvlReq";
BA_ "ISignalName" SG_ 343 AEBBrkJerkLvlReq "IAEBBrkJerkLvlReq";
BA_ "LongName" SG_ 343 AEBBrkJerkLvlReq "Autonomous Emergency Braking Brake Jerk Level Request";
BA_ "SysSignalName" SG_ 343 AEBBrkJerkLvlReq "AEBBrkJerkLvlReq";
BA_ "CompuMethodName" SG_ 343 AEBHydBrkAstLvlReq "AEBHydBrkAstLvlReq";
BA_ "ISignalName" SG_ 343 AEBHydBrkAstLvlReq "IAEBHydBrkAstLvlReq";
BA_ "LongName" SG_ 343 AEBHydBrkAstLvlReq "Autonomous Emergency Braking Hydraulic Brake Assist Level Request";
BA_ "SysSignalName" SG_ 343 AEBHydBrkAstLvlReq "AEBHydBrkAstLvlReq";
BA_ "CompuMethodName" SG_ 343 AEBDclReqVal "AEBDclReqVal";
BA_ "GenSigStartValue" SG_ 343 AEBDclReqVal 127;
BA_ "ISignalName" SG_ 343 AEBDclReqVal "IAEBDclReqVal";
BA_ "LongName" SG_ 343 AEBDclReqVal "Autonomous Emergency Braking Deceleration Request Value";
BA_ "SysSignalName" SG_ 343 AEBDclReqVal "AEBDclReqVal";
BA_ "CompuMethodName" SG_ 343 ICBAD_20ms_Group46_Reserved1 "ICBAD_20ms_Group46_Reserved1";
BA_ "GenSigStartValue" SG_ 343 ICBAD_20ms_Group46_Reserved1 31;
BA_ "ISignalName" SG_ 343 ICBAD_20ms_Group46_Reserved1 "IICBAD_20ms_Group46_Reserved1";
BA_ "SysSignalName" SG_ 343 ICBAD_20ms_Group46_Reserved1 "ICBAD_20ms_Group46_Reserved1";
BA_ "CompuMethodName" SG_ 343 AEBSysFltSts "AEBSysFltSts";
BA_ "ISignalName" SG_ 343 AEBSysFltSts "IAEBSysFltSts";
BA_ "LongName" SG_ 343 AEBSysFltSts "Autonomous Emergency Braking System Fault Status";
BA_ "SysSignalName" SG_ 343 AEBSysFltSts "AEBSysFltSts";
BA_ "CompuMethodName" SG_ 343 ICBAD_20ms_Group46_Reserved2 "ICBAD_20ms_Group46_Reserved2";
BA_ "GenSigStartValue" SG_ 343 ICBAD_20ms_Group46_Reserved2 255;
BA_ "ISignalName" SG_ 343 ICBAD_20ms_Group46_Reserved2 "IICBAD_20ms_Group46_Reserved2";
BA_ "SysSignalName" SG_ 343 ICBAD_20ms_Group46_Reserved2 "ICBAD_20ms_Group46_Reserved2";
BA_ "CompuMethodName" SG_ 343 AEBDclReqToqVal "AEBDclReqToqVal";
BA_ "ISignalName" SG_ 343 AEBDclReqToqVal "IAEBDclReqToqVal";
BA_ "LongName" SG_ 343 AEBDclReqToqVal "Autonomous Emergency Braking Deceleration Request Torque Value";
BA_ "SysSignalName" SG_ 343 AEBDclReqToqVal "AEBDclReqToqVal";
BA_ "CompuMethodName" SG_ 102 ICBAD_10ms_Group01_CRC "ICBAD_10ms_Group01_CRC";
BA_ "ISignalName" SG_ 102 ICBAD_10ms_Group01_CRC "IICBAD_10ms_Group01_CRC";
BA_ "LongName" SG_ 102 ICBAD_10ms_Group01_CRC "ICBAD_10ms_Group01_CRC";
BA_ "SysSignalName" SG_ 102 ICBAD_10ms_Group01_CRC "ICBAD_10ms_Group01_CRC";
BA_ "CompuMethodName" SG_ 102 ICBAD_10ms_Group01_RC "ICBAD_10ms_Group01_RC";
BA_ "ISignalName" SG_ 102 ICBAD_10ms_Group01_RC "IICBAD_10ms_Group01_RC";
BA_ "LongName" SG_ 102 ICBAD_10ms_Group01_RC "ICBAD_10ms_Group01_RC";
BA_ "SysSignalName" SG_ 102 ICBAD_10ms_Group01_RC "ICBAD_10ms_Group01_RC";
BA_ "CompuMethodName" SG_ 102 ICBAD_10ms_Group01_Reserved1 "ICBAD_10ms_Group01_Reserved1";
BA_ "GenSigStartValue" SG_ 102 ICBAD_10ms_Group01_Reserved1 15;
BA_ "ISignalName" SG_ 102 ICBAD_10ms_Group01_Reserved1 "IICBAD_10ms_Group01_Reserved1";
BA_ "SysSignalName" SG_ 102 ICBAD_10ms_Group01_Reserved1 "ICBAD_10ms_Group01_Reserved1";
BA_ "CompuMethodName" SG_ 102 PltEPSRdWhlAngReqStsV "PltEPSRdWhlAngReqStsV";
BA_ "ISignalName" SG_ 102 PltEPSRdWhlAngReqStsV "IPltEPSRdWhlAngReqStsV";
BA_ "LongName" SG_ 102 PltEPSRdWhlAngReqStsV "Pilot Electric Power Steering Road Wheel Angle Request Status Valid";
BA_ "SysSignalName" SG_ 102 PltEPSRdWhlAngReqStsV "PltEPSRdWhlAngReqStsV";
BA_ "CompuMethodName" SG_ 102 PltEPSRdWhlAngReqSts "PltEPSRdWhlAngReqSts";
BA_ "ISignalName" SG_ 102 PltEPSRdWhlAngReqSts "IPltEPSRdWhlAngReqSts";
BA_ "LongName" SG_ 102 PltEPSRdWhlAngReqSts "Pilot Electric Power Steering Road Wheel Angle Request Status";
BA_ "SysSignalName" SG_ 102 PltEPSRdWhlAngReqSts "PltEPSRdWhlAngReqSts";
BA_ "CompuMethodName" SG_ 102 ICBAD_10ms_Group01_Reserved2 "ICBAD_10ms_Group01_Reserved2";
BA_ "GenSigStartValue" SG_ 102 ICBAD_10ms_Group01_Reserved2 15;
BA_ "ISignalName" SG_ 102 ICBAD_10ms_Group01_Reserved2 "IICBAD_10ms_Group01_Reserved2";
BA_ "SysSignalName" SG_ 102 ICBAD_10ms_Group01_Reserved2 "ICBAD_10ms_Group01_Reserved2";
BA_ "CompuMethodName" SG_ 102 ICBAD_10ms_Group01_Reserved3 "ICBAD_10ms_Group01_Reserved3";
BA_ "GenSigStartValue" SG_ 102 ICBAD_10ms_Group01_Reserved3 255;
BA_ "ISignalName" SG_ 102 ICBAD_10ms_Group01_Reserved3 "IICBAD_10ms_Group01_Reserved3";
BA_ "SysSignalName" SG_ 102 ICBAD_10ms_Group01_Reserved3 "ICBAD_10ms_Group01_Reserved3";
BA_ "CompuMethodName" SG_ 102 ICBAD_10ms_Group01_Reserved4 "ICBAD_10ms_Group01_Reserved4";
BA_ "GenSigStartValue" SG_ 102 ICBAD_10ms_Group01_Reserved4 255;
BA_ "ISignalName" SG_ 102 ICBAD_10ms_Group01_Reserved4 "IICBAD_10ms_Group01_Reserved4";
BA_ "SysSignalName" SG_ 102 ICBAD_10ms_Group01_Reserved4 "ICBAD_10ms_Group01_Reserved4";
BA_ "CompuMethodName" SG_ 102 ICBAD_10ms_Group01_Reserved5 "ICBAD_10ms_Group01_Reserved5";
BA_ "GenSigStartValue" SG_ 102 ICBAD_10ms_Group01_Reserved5 255;
BA_ "ISignalName" SG_ 102 ICBAD_10ms_Group01_Reserved5 "IICBAD_10ms_Group01_Reserved5";
BA_ "SysSignalName" SG_ 102 ICBAD_10ms_Group01_Reserved5 "ICBAD_10ms_Group01_Reserved5";
BA_ "CompuMethodName" SG_ 102 ICBAD_10ms_Group01_Reserved6 "ICBAD_10ms_Group01_Reserved6";
BA_ "GenSigStartValue" SG_ 102 ICBAD_10ms_Group01_Reserved6 255;
BA_ "ISignalName" SG_ 102 ICBAD_10ms_Group01_Reserved6 "IICBAD_10ms_Group01_Reserved6";
BA_ "SysSignalName" SG_ 102 ICBAD_10ms_Group01_Reserved6 "ICBAD_10ms_Group01_Reserved6";
BA_ "CompuMethodName" SG_ 102 ICBAD_10ms_Group01_Reserved7 "ICBAD_10ms_Group01_Reserved7";
BA_ "GenSigStartValue" SG_ 102 ICBAD_10ms_Group01_Reserved7 1;
BA_ "ISignalName" SG_ 102 ICBAD_10ms_Group01_Reserved7 "IICBAD_10ms_Group01_Reserved7";
BA_ "SysSignalName" SG_ 102 ICBAD_10ms_Group01_Reserved7 "ICBAD_10ms_Group01_Reserved7";
BA_ "CompuMethodName" SG_ 102 EPSToqAppdCoefnt "EPSToqAppdCoefnt";
BA_ "ISignalName" SG_ 102 EPSToqAppdCoefnt "IEPSToqAppdCoefnt";
BA_ "LongName" SG_ 102 EPSToqAppdCoefnt "Electric Power Steering Torque Applied Coefficient";
BA_ "SysSignalName" SG_ 102 EPSToqAppdCoefnt "EPSToqAppdCoefnt";
BA_ "CompuMethodName" SG_ 102 ICBAD_10ms_Group01_Reserved8 "ICBAD_10ms_Group01_Reserved8";
BA_ "GenSigStartValue" SG_ 102 ICBAD_10ms_Group01_Reserved8 255;
BA_ "ISignalName" SG_ 102 ICBAD_10ms_Group01_Reserved8 "IICBAD_10ms_Group01_Reserved8";
BA_ "SysSignalName" SG_ 102 ICBAD_10ms_Group01_Reserved8 "ICBAD_10ms_Group01_Reserved8";
BA_ "CompuMethodName" SG_ 102 ICBAD_10ms_Group01_Reserved9 "ICBAD_10ms_Group01_Reserved9";
BA_ "GenSigStartValue" SG_ 102 ICBAD_10ms_Group01_Reserved9 255;
BA_ "ISignalName" SG_ 102 ICBAD_10ms_Group01_Reserved9 "IICBAD_10ms_Group01_Reserved9";
BA_ "SysSignalName" SG_ 102 ICBAD_10ms_Group01_Reserved9 "ICBAD_10ms_Group01_Reserved9";
BA_ "CompuMethodName" SG_ 102 ICBAD_10ms_Group01_Reserved10 "ICBAD_10ms_Group01_Reserved10";
BA_ "GenSigStartValue" SG_ 102 ICBAD_10ms_Group01_Reserved10 255;
BA_ "ISignalName" SG_ 102 ICBAD_10ms_Group01_Reserved10 "IICBAD_10ms_Group01_Reserved10";
BA_ "SysSignalName" SG_ 102 ICBAD_10ms_Group01_Reserved10 "ICBAD_10ms_Group01_Reserved10";
BA_ "CompuMethodName" SG_ 102 ICBAD_10ms_Group01_Reserved11 "ICBAD_10ms_Group01_Reserved11";
BA_ "GenSigStartValue" SG_ 102 ICBAD_10ms_Group01_Reserved11 255;
BA_ "ISignalName" SG_ 102 ICBAD_10ms_Group01_Reserved11 "IICBAD_10ms_Group01_Reserved11";
BA_ "SysSignalName" SG_ 102 ICBAD_10ms_Group01_Reserved11 "ICBAD_10ms_Group01_Reserved11";
BA_ "CompuMethodName" SG_ 102 ICBAD_10ms_Group01_Reserved12 "ICBAD_10ms_Group01_Reserved12";
BA_ "GenSigStartValue" SG_ 102 ICBAD_10ms_Group01_Reserved12 255;
BA_ "ISignalName" SG_ 102 ICBAD_10ms_Group01_Reserved12 "IICBAD_10ms_Group01_Reserved12";
BA_ "SysSignalName" SG_ 102 ICBAD_10ms_Group01_Reserved12 "ICBAD_10ms_Group01_Reserved12";
BA_ "CompuMethodName" SG_ 102 ICBAD_10ms_Group01_Reserved13 "ICBAD_10ms_Group01_Reserved13";
BA_ "GenSigStartValue" SG_ 102 ICBAD_10ms_Group01_Reserved13 255;
BA_ "ISignalName" SG_ 102 ICBAD_10ms_Group01_Reserved13 "IICBAD_10ms_Group01_Reserved13";
BA_ "SysSignalName" SG_ 102 ICBAD_10ms_Group01_Reserved13 "ICBAD_10ms_Group01_Reserved13";
BA_ "CompuMethodName" SG_ 102 ICBAD_10ms_Group01_Reserved14 "ICBAD_10ms_Group01_Reserved14";
BA_ "GenSigStartValue" SG_ 102 ICBAD_10ms_Group01_Reserved14 255;
BA_ "ISignalName" SG_ 102 ICBAD_10ms_Group01_Reserved14 "IICBAD_10ms_Group01_Reserved14";
BA_ "SysSignalName" SG_ 102 ICBAD_10ms_Group01_Reserved14 "ICBAD_10ms_Group01_Reserved14";
BA_ "CompuMethodName" SG_ 102 ICBAD_10ms_Group01_Reserved15 "ICBAD_10ms_Group01_Reserved15";
BA_ "GenSigStartValue" SG_ 102 ICBAD_10ms_Group01_Reserved15 255;
BA_ "ISignalName" SG_ 102 ICBAD_10ms_Group01_Reserved15 "IICBAD_10ms_Group01_Reserved15";
BA_ "SysSignalName" SG_ 102 ICBAD_10ms_Group01_Reserved15 "ICBAD_10ms_Group01_Reserved15";
BA_ "CompuMethodName" SG_ 102 ICBAD_10ms_Group01_Reserved16 "ICBAD_10ms_Group01_Reserved16";
BA_ "GenSigStartValue" SG_ 102 ICBAD_10ms_Group01_Reserved16 255;
BA_ "ISignalName" SG_ 102 ICBAD_10ms_Group01_Reserved16 "IICBAD_10ms_Group01_Reserved16";
BA_ "SysSignalName" SG_ 102 ICBAD_10ms_Group01_Reserved16 "ICBAD_10ms_Group01_Reserved16";
BA_ "CompuMethodName" SG_ 102 ICBAD_10ms_Group01_Reserved17 "ICBAD_10ms_Group01_Reserved17";
BA_ "GenSigStartValue" SG_ 102 ICBAD_10ms_Group01_Reserved17 255;
BA_ "ISignalName" SG_ 102 ICBAD_10ms_Group01_Reserved17 "IICBAD_10ms_Group01_Reserved17";
BA_ "SysSignalName" SG_ 102 ICBAD_10ms_Group01_Reserved17 "ICBAD_10ms_Group01_Reserved17";
BA_ "CompuMethodName" SG_ 102 ICBAD_10ms_Group01_Reserved18 "ICBAD_10ms_Group01_Reserved18";
BA_ "GenSigStartValue" SG_ 102 ICBAD_10ms_Group01_Reserved18 255;
BA_ "ISignalName" SG_ 102 ICBAD_10ms_Group01_Reserved18 "IICBAD_10ms_Group01_Reserved18";
BA_ "SysSignalName" SG_ 102 ICBAD_10ms_Group01_Reserved18 "ICBAD_10ms_Group01_Reserved18";
BA_ "CompuMethodName" SG_ 102 ICBAD_10ms_Group01_Reserved19 "ICBAD_10ms_Group01_Reserved19";
BA_ "GenSigStartValue" SG_ 102 ICBAD_10ms_Group01_Reserved19 255;
BA_ "ISignalName" SG_ 102 ICBAD_10ms_Group01_Reserved19 "IICBAD_10ms_Group01_Reserved19";
BA_ "SysSignalName" SG_ 102 ICBAD_10ms_Group01_Reserved19 "ICBAD_10ms_Group01_Reserved19";
BA_ "CompuMethodName" SG_ 102 ICBAD_10ms_Group01_Reserved20 "ICBAD_10ms_Group01_Reserved20";
BA_ "GenSigStartValue" SG_ 102 ICBAD_10ms_Group01_Reserved20 255;
BA_ "ISignalName" SG_ 102 ICBAD_10ms_Group01_Reserved20 "IICBAD_10ms_Group01_Reserved20";
BA_ "SysSignalName" SG_ 102 ICBAD_10ms_Group01_Reserved20 "ICBAD_10ms_Group01_Reserved20";
BA_ "CompuMethodName" SG_ 102 ICBAD_10ms_Group01_Reserved21 "ICBAD_10ms_Group01_Reserved21";
BA_ "GenSigStartValue" SG_ 102 ICBAD_10ms_Group01_Reserved21 255;
BA_ "ISignalName" SG_ 102 ICBAD_10ms_Group01_Reserved21 "IICBAD_10ms_Group01_Reserved21";
BA_ "SysSignalName" SG_ 102 ICBAD_10ms_Group01_Reserved21 "ICBAD_10ms_Group01_Reserved21";
BA_ "CompuMethodName" SG_ 102 ICBAD_10ms_Group01_Reserved22 "ICBAD_10ms_Group01_Reserved22";
BA_ "GenSigStartValue" SG_ 102 ICBAD_10ms_Group01_Reserved22 255;
BA_ "ISignalName" SG_ 102 ICBAD_10ms_Group01_Reserved22 "IICBAD_10ms_Group01_Reserved22";
BA_ "SysSignalName" SG_ 102 ICBAD_10ms_Group01_Reserved22 "ICBAD_10ms_Group01_Reserved22";
BA_ "CompuMethodName" SG_ 102 ICBAD_10ms_Group01_Reserved23 "ICBAD_10ms_Group01_Reserved23";
BA_ "GenSigStartValue" SG_ 102 ICBAD_10ms_Group01_Reserved23 255;
BA_ "ISignalName" SG_ 102 ICBAD_10ms_Group01_Reserved23 "IICBAD_10ms_Group01_Reserved23";
BA_ "SysSignalName" SG_ 102 ICBAD_10ms_Group01_Reserved23 "ICBAD_10ms_Group01_Reserved23";
BA_ "CompuMethodName" SG_ 360 ICBAD_20ms_Group13_CRC "ICBAD_20ms_Group13_CRC";
BA_ "ISignalName" SG_ 360 ICBAD_20ms_Group13_CRC "IICBAD_20ms_Group13_CRC";
BA_ "LongName" SG_ 360 ICBAD_20ms_Group13_CRC "ICBAD_20ms_Group13_CRC";
BA_ "SysSignalName" SG_ 360 ICBAD_20ms_Group13_CRC "ICBAD_20ms_Group13_CRC";
BA_ "CompuMethodName" SG_ 360 ICBAD_20ms_Group13_RC "ICBAD_20ms_Group13_RC";
BA_ "ISignalName" SG_ 360 ICBAD_20ms_Group13_RC "IICBAD_20ms_Group13_RC";
BA_ "LongName" SG_ 360 ICBAD_20ms_Group13_RC "ICBAD_20ms_Group13_RC";
BA_ "SysSignalName" SG_ 360 ICBAD_20ms_Group13_RC "ICBAD_20ms_Group13_RC";
BA_ "CompuMethodName" SG_ 360 APAShifterPosReqd "APAShifterPosReqd";
BA_ "ISignalName" SG_ 360 APAShifterPosReqd "IAPAShifterPosReqd";
BA_ "LongName" SG_ 360 APAShifterPosReqd "Advanced Park Assist Shifter Position Requested";
BA_ "SysSignalName" SG_ 360 APAShifterPosReqd "APAShifterPosReqd";
BA_ "CompuMethodName" SG_ 360 APATrgtEPSStrgWhlAng "APATrgtEPSStrgWhlAng";
BA_ "GenSigStartValue" SG_ 360 APATrgtEPSStrgWhlAng 32768;
BA_ "ISignalName" SG_ 360 APATrgtEPSStrgWhlAng "IAPATrgtEPSStrgWhlAng";
BA_ "LongName" SG_ 360 APATrgtEPSStrgWhlAng "Advanced Park Assist Target Electric Power Steering Steering Wheel Angle";
BA_ "SysSignalName" SG_ 360 APATrgtEPSStrgWhlAng "APATrgtEPSStrgWhlAng";
BA_ "CompuMethodName" SG_ 360 ICBAD_20ms_Group13_Reserved1 "ICBAD_20ms_Group13_Reserved1";
BA_ "GenSigStartValue" SG_ 360 ICBAD_20ms_Group13_Reserved1 255;
BA_ "ISignalName" SG_ 360 ICBAD_20ms_Group13_Reserved1 "IICBAD_20ms_Group13_Reserved1";
BA_ "SysSignalName" SG_ 360 ICBAD_20ms_Group13_Reserved1 "ICBAD_20ms_Group13_Reserved1";
BA_ "CompuMethodName" SG_ 360 APASCUReqSts "APASCUReqSts";
BA_ "ISignalName" SG_ 360 APASCUReqSts "IAPASCUReqSts";
BA_ "LongName" SG_ 360 APASCUReqSts "Advanced Park Assist Shifter Control Unit Request Status";
BA_ "SysSignalName" SG_ 360 APASCUReqSts "APASCUReqSts";
BA_ "CompuMethodName" SG_ 360 APACmdEPSSts "APACmdEPSSts";
BA_ "ISignalName" SG_ 360 APACmdEPSSts "IAPACmdEPSSts";
BA_ "LongName" SG_ 360 APACmdEPSSts "Advanced Park Assist Command Electric Power Steering Status";
BA_ "SysSignalName" SG_ 360 APACmdEPSSts "APACmdEPSSts";
BA_ "CompuMethodName" SG_ 360 ICBAD_20ms_Group13_Reserved2 "ICBAD_20ms_Group13_Reserved2";
BA_ "GenSigStartValue" SG_ 360 ICBAD_20ms_Group13_Reserved2 15;
BA_ "ISignalName" SG_ 360 ICBAD_20ms_Group13_Reserved2 "IICBAD_20ms_Group13_Reserved2";
BA_ "SysSignalName" SG_ 360 ICBAD_20ms_Group13_Reserved2 "ICBAD_20ms_Group13_Reserved2";
BA_ "CompuMethodName" SG_ 360 ICBAD_20ms_Group13_Reserved4 "ICBAD_20ms_Group13_Reserved4";
BA_ "GenSigStartValue" SG_ 360 ICBAD_20ms_Group13_Reserved4 15;
BA_ "ISignalName" SG_ 360 ICBAD_20ms_Group13_Reserved4 "IICBAD_20ms_Group13_Reserved4";
BA_ "SysSignalName" SG_ 360 ICBAD_20ms_Group13_Reserved4 "ICBAD_20ms_Group13_Reserved4";
BA_ "CompuMethodName" SG_ 360 APAShifterPosReqdV "APAShifterPosReqdV";
BA_ "ISignalName" SG_ 360 APAShifterPosReqdV "IAPAShifterPosReqdV";
BA_ "LongName" SG_ 360 APAShifterPosReqdV "Advanced Park Assist Shifter Position Requested Validity";
BA_ "SysSignalName" SG_ 360 APAShifterPosReqdV "APAShifterPosReqdV";
BA_ "CompuMethodName" SG_ 360 APASCUReqStsV "APASCUReqStsV";
BA_ "ISignalName" SG_ 360 APASCUReqStsV "IAPASCUReqStsV";
BA_ "LongName" SG_ 360 APASCUReqStsV "Advanced Park Assist Shifter Control Unit Request Status Validity";
BA_ "SysSignalName" SG_ 360 APASCUReqStsV "APASCUReqStsV";
BA_ "CompuMethodName" SG_ 360 APAF "APAF";
BA_ "ISignalName" SG_ 360 APAF "IAPAF";
BA_ "LongName" SG_ 360 APAF "Advanced Park Assist Failed";
BA_ "SysSignalName" SG_ 360 APAF "APAF";
BA_ "CompuMethodName" SG_ 360 ICBAD_20ms_Group13_Reserved3 "ICBAD_20ms_Group13_Reserved3";
BA_ "GenSigStartValue" SG_ 360 ICBAD_20ms_Group13_Reserved3 1;
BA_ "ISignalName" SG_ 360 ICBAD_20ms_Group13_Reserved3 "IICBAD_20ms_Group13_Reserved3";
BA_ "SysSignalName" SG_ 360 ICBAD_20ms_Group13_Reserved3 "ICBAD_20ms_Group13_Reserved3";
BA_ "CompuMethodName" SG_ 360 ICBAD_20ms_Group13_Reserved5 "ICBAD_20ms_Group13_Reserved5";
BA_ "GenSigStartValue" SG_ 360 ICBAD_20ms_Group13_Reserved5 255;
BA_ "ISignalName" SG_ 360 ICBAD_20ms_Group13_Reserved5 "IICBAD_20ms_Group13_Reserved5";
BA_ "SysSignalName" SG_ 360 ICBAD_20ms_Group13_Reserved5 "ICBAD_20ms_Group13_Reserved5";
BA_ "CompuMethodName" SG_ 1122 ACCStsForEdr "ACCStsForEdr";
BA_ "ISignalName" SG_ 1122 ACCStsForEdr "IACCStsForEdr";
BA_ "LongName" SG_ 1122 ACCStsForEdr "Adaptive Cruise Control Status For Edr";
BA_ "SysSignalName" SG_ 1122 ACCStsForEdr "ACCStsForEdr";
BA_ "CompuMethodName" SG_ 1122 LDWStsForEdr "LDWStsForEdr";
BA_ "ISignalName" SG_ 1122 LDWStsForEdr "ILDWStsForEdr";
BA_ "LongName" SG_ 1122 LDWStsForEdr "Lane Departure Warning Status For Edr";
BA_ "SysSignalName" SG_ 1122 LDWStsForEdr "LDWStsForEdr";
BA_ "CompuMethodName" SG_ 1122 AEBStsForEdr "AEBStsForEdr";
BA_ "ISignalName" SG_ 1122 AEBStsForEdr "IAEBStsForEdr";
BA_ "LongName" SG_ 1122 AEBStsForEdr "Autonomous Emergency Braking Status For Edr";
BA_ "SysSignalName" SG_ 1122 AEBStsForEdr "AEBStsForEdr";
BA_ "CompuMethodName" SG_ 1122 ESFStsForEdr "ESFStsForEdr";
BA_ "ISignalName" SG_ 1122 ESFStsForEdr "IESFStsForEdr";
BA_ "LongName" SG_ 1122 ESFStsForEdr "Emergency Steering Function Status For Edr";
BA_ "SysSignalName" SG_ 1122 ESFStsForEdr "ESFStsForEdr";
BA_ "CompuMethodName" SG_ 1122 CSFStsForEdr "CSFStsForEdr";
BA_ "ISignalName" SG_ 1122 CSFStsForEdr "ICSFStsForEdr";
BA_ "LongName" SG_ 1122 CSFStsForEdr "Corrective Steering Function Status For Edr";
BA_ "SysSignalName" SG_ 1122 CSFStsForEdr "CSFStsForEdr";
BA_ "CompuMethodName" SG_ 1122 ACSFCatgrB1StsForEdr "ACSFCatgrB1StsForEdr";
BA_ "ISignalName" SG_ 1122 ACSFCatgrB1StsForEdr "IACSFCatgrB1StsForEdr";
BA_ "LongName" SG_ 1122 ACSFCatgrB1StsForEdr "Automatically Commanded Steering Function Category B1 Status For Edr";
BA_ "SysSignalName" SG_ 1122 ACSFCatgrB1StsForEdr "ACSFCatgrB1StsForEdr";
BA_ "CompuMethodName" SG_ 1122 ACSFCatgrAStsForEdr "ACSFCatgrAStsForEdr";
BA_ "ISignalName" SG_ 1122 ACSFCatgrAStsForEdr "IACSFCatgrAStsForEdr";
BA_ "LongName" SG_ 1122 ACSFCatgrAStsForEdr "Automatically Commanded Steering Function Category A Status For Edr";
BA_ "SysSignalName" SG_ 1122 ACSFCatgrAStsForEdr "ACSFCatgrAStsForEdr";
BA_ "CompuMethodName" SG_ 1122 ACSFCatgrCStsForEdr "ACSFCatgrCStsForEdr";
BA_ "ISignalName" SG_ 1122 ACSFCatgrCStsForEdr "IACSFCatgrCStsForEdr";
BA_ "LongName" SG_ 1122 ACSFCatgrCStsForEdr "Automatically Commanded Steering Function Category C Status For Edr";
BA_ "SysSignalName" SG_ 1122 ACSFCatgrCStsForEdr "ACSFCatgrCStsForEdr";
BA_ "CompuMethodName" SG_ 1122 ACSFCatgrB2StsForEdr "ACSFCatgrB2StsForEdr";
BA_ "ISignalName" SG_ 1122 ACSFCatgrB2StsForEdr "IACSFCatgrB2StsForEdr";
BA_ "LongName" SG_ 1122 ACSFCatgrB2StsForEdr "Automatically Commanded Steering Function Category B2 Status For Edr";
BA_ "SysSignalName" SG_ 1122 ACSFCatgrB2StsForEdr "ACSFCatgrB2StsForEdr";
BA_ "CompuMethodName" SG_ 1122 ACSFCatgrEStsForEdr "ACSFCatgrEStsForEdr";
BA_ "ISignalName" SG_ 1122 ACSFCatgrEStsForEdr "IACSFCatgrEStsForEdr";
BA_ "LongName" SG_ 1122 ACSFCatgrEStsForEdr "Automatically Commanded Steering Function Category E Status For Edr";
BA_ "SysSignalName" SG_ 1122 ACSFCatgrEStsForEdr "ACSFCatgrEStsForEdr";
BA_ "CompuMethodName" SG_ 1122 ACSFCatgrDStsForEdr "ACSFCatgrDStsForEdr";
BA_ "ISignalName" SG_ 1122 ACSFCatgrDStsForEdr "IACSFCatgrDStsForEdr";
BA_ "LongName" SG_ 1122 ACSFCatgrDStsForEdr "Automatically Commanded Steering Function Category D Status For Edr";
BA_ "SysSignalName" SG_ 1122 ACSFCatgrDStsForEdr "ACSFCatgrDStsForEdr";
BA_ "CompuMethodName" SG_ 474 ICBAD_20ms_Group48_CRC "ICBAD_20ms_Group48_CRC";
BA_ "ISignalName" SG_ 474 ICBAD_20ms_Group48_CRC "IICBAD_20ms_Group48_CRC";
BA_ "LongName" SG_ 474 ICBAD_20ms_Group48_CRC "ICBAD_20ms_Group48_CRC";
BA_ "SysSignalName" SG_ 474 ICBAD_20ms_Group48_CRC "ICBAD_20ms_Group48_CRC";
BA_ "CompuMethodName" SG_ 474 ICBAD_20ms_Group48_RC "ICBAD_20ms_Group48_RC";
BA_ "ISignalName" SG_ 474 ICBAD_20ms_Group48_RC "IICBAD_20ms_Group48_RC";
BA_ "LongName" SG_ 474 ICBAD_20ms_Group48_RC "ICBAD_20ms_Group48_RC";
BA_ "SysSignalName" SG_ 474 ICBAD_20ms_Group48_RC "ICBAD_20ms_Group48_RC";
BA_ "CompuMethodName" SG_ 474 ICBAD_20ms_Group48_Reserved1 "ICBAD_20ms_Group48_Reserved1";
BA_ "GenSigStartValue" SG_ 474 ICBAD_20ms_Group48_Reserved1 1;
BA_ "ISignalName" SG_ 474 ICBAD_20ms_Group48_Reserved1 "IICBAD_20ms_Group48_Reserved1";
BA_ "SysSignalName" SG_ 474 ICBAD_20ms_Group48_Reserved1 "ICBAD_20ms_Group48_Reserved1";
BA_ "CompuMethodName" SG_ 474 LDWLKARVsulznReq "LDWLKARVsulznReq";
BA_ "ISignalName" SG_ 474 LDWLKARVsulznReq "ILDWLKARVsulznReq";
BA_ "LongName" SG_ 474 LDWLKARVsulznReq "Lane Departure Warning Lane Keeping Assist Right Visualization Request";
BA_ "SysSignalName" SG_ 474 LDWLKARVsulznReq "LDWLKARVsulznReq";
BA_ "CompuMethodName" SG_ 474 LDWLKAVbnLvlReq "LDWLKAVbnLvlReq";
BA_ "ISignalName" SG_ 474 LDWLKAVbnLvlReq "ILDWLKAVbnLvlReq";
BA_ "LongName" SG_ 474 LDWLKAVbnLvlReq "Lane Departure Warning Lane Keeping Assist Vibration Level Request";
BA_ "SysSignalName" SG_ 474 LDWLKAVbnLvlReq "LDWLKAVbnLvlReq";
BA_ "CompuMethodName" SG_ 474 LDWSysFltSts "LDWSysFltSts";
BA_ "ISignalName" SG_ 474 LDWSysFltSts "ILDWSysFltSts";
BA_ "LongName" SG_ 474 LDWSysFltSts "Lane Departure Warning System Fault Status";
BA_ "SysSignalName" SG_ 474 LDWSysFltSts "LDWSysFltSts";
BA_ "CompuMethodName" SG_ 474 LDWSysSts "LDWSysSts";
BA_ "ISignalName" SG_ 474 LDWSysSts "ILDWSysSts";
BA_ "LongName" SG_ 474 LDWSysSts "Lane Departure Warning System Status";
BA_ "SysSignalName" SG_ 474 LDWSysSts "LDWSysSts";
BA_ "CompuMethodName" SG_ 474 ICBAD_20ms_Group48_Reserved2 "ICBAD_20ms_Group48_Reserved2";
BA_ "GenSigStartValue" SG_ 474 ICBAD_20ms_Group48_Reserved2 255;
BA_ "ISignalName" SG_ 474 ICBAD_20ms_Group48_Reserved2 "IICBAD_20ms_Group48_Reserved2";
BA_ "SysSignalName" SG_ 474 ICBAD_20ms_Group48_Reserved2 "ICBAD_20ms_Group48_Reserved2";
BA_ "CompuMethodName" SG_ 474 ICBAD_20ms_Group48_Reserved3 "ICBAD_20ms_Group48_Reserved3";
BA_ "GenSigStartValue" SG_ 474 ICBAD_20ms_Group48_Reserved3 255;
BA_ "ISignalName" SG_ 474 ICBAD_20ms_Group48_Reserved3 "IICBAD_20ms_Group48_Reserved3";
BA_ "SysSignalName" SG_ 474 ICBAD_20ms_Group48_Reserved3 "ICBAD_20ms_Group48_Reserved3";
BA_ "CompuMethodName" SG_ 474 ICBAD_20ms_Group48_Reserved4 "ICBAD_20ms_Group48_Reserved4";
BA_ "GenSigStartValue" SG_ 474 ICBAD_20ms_Group48_Reserved4 31;
BA_ "ISignalName" SG_ 474 ICBAD_20ms_Group48_Reserved4 "IICBAD_20ms_Group48_Reserved4";
BA_ "SysSignalName" SG_ 474 ICBAD_20ms_Group48_Reserved4 "ICBAD_20ms_Group48_Reserved4";
BA_ "CompuMethodName" SG_ 474 LDWLKALVsulznReq "LDWLKALVsulznReq";
BA_ "ISignalName" SG_ 474 LDWLKALVsulznReq "ILDWLKALVsulznReq";
BA_ "LongName" SG_ 474 LDWLKALVsulznReq "Lane Departure Warning Lane Keeping Assist Left Visualization Request";
BA_ "SysSignalName" SG_ 474 LDWLKALVsulznReq "LDWLKALVsulznReq";
BA_ "CompuMethodName" SG_ 474 ICBAD_20ms_Group48_Reserved5 "ICBAD_20ms_Group48_Reserved5";
BA_ "GenSigStartValue" SG_ 474 ICBAD_20ms_Group48_Reserved5 255;
BA_ "ISignalName" SG_ 474 ICBAD_20ms_Group48_Reserved5 "IICBAD_20ms_Group48_Reserved5";
BA_ "SysSignalName" SG_ 474 ICBAD_20ms_Group48_Reserved5 "ICBAD_20ms_Group48_Reserved5";
BA_ "CompuMethodName" SG_ 474 ICBAD_20ms_Group48_Reserved6 "ICBAD_20ms_Group48_Reserved6";
BA_ "GenSigStartValue" SG_ 474 ICBAD_20ms_Group48_Reserved6 255;
BA_ "ISignalName" SG_ 474 ICBAD_20ms_Group48_Reserved6 "IICBAD_20ms_Group48_Reserved6";
BA_ "SysSignalName" SG_ 474 ICBAD_20ms_Group48_Reserved6 "ICBAD_20ms_Group48_Reserved6";
BA_ "CompuMethodName" SG_ 47 ToEPSMsgChlg "ToEPSMsgChlg";
BA_ "ISignalName" SG_ 47 ToEPSMsgChlg "IToEPSMsgChlg";
BA_ "LongName" SG_ 47 ToEPSMsgChlg "To Electric Power Steering Message Challenge";
BA_ "SysSignalName" SG_ 47 ToEPSMsgChlg "ToEPSMsgChlg";
BA_ "CompuMethodName" SG_ 424 ICBAD_20ms_Group12_CRC "ICBAD_20ms_Group12_CRC";
BA_ "ISignalName" SG_ 424 ICBAD_20ms_Group12_CRC "IICBAD_20ms_Group12_CRC";
BA_ "LongName" SG_ 424 ICBAD_20ms_Group12_CRC "ICBAD_20ms_Group12_CRC";
BA_ "SysSignalName" SG_ 424 ICBAD_20ms_Group12_CRC "ICBAD_20ms_Group12_CRC";
BA_ "CompuMethodName" SG_ 424 ICBAD_20ms_Group12_RC "ICBAD_20ms_Group12_RC";
BA_ "ISignalName" SG_ 424 ICBAD_20ms_Group12_RC "IICBAD_20ms_Group12_RC";
BA_ "LongName" SG_ 424 ICBAD_20ms_Group12_RC "ICBAD_20ms_Group12_RC";
BA_ "SysSignalName" SG_ 424 ICBAD_20ms_Group12_RC "ICBAD_20ms_Group12_RC";
BA_ "CompuMethodName" SG_ 424 AutodDrvngSysStsV "AutodDrvngSysStsV";
BA_ "ISignalName" SG_ 424 AutodDrvngSysStsV "IAutodDrvngSysStsV";
BA_ "LongName" SG_ 424 AutodDrvngSysStsV "Automated Driving System Status Validity";
BA_ "SysSignalName" SG_ 424 AutodDrvngSysStsV "AutodDrvngSysStsV";
BA_ "CompuMethodName" SG_ 424 ICBAD_20ms_Group12_Reserved1 "ICBAD_20ms_Group12_Reserved1";
BA_ "GenSigStartValue" SG_ 424 ICBAD_20ms_Group12_Reserved1 7;
BA_ "ISignalName" SG_ 424 ICBAD_20ms_Group12_Reserved1 "IICBAD_20ms_Group12_Reserved1";
BA_ "SysSignalName" SG_ 424 ICBAD_20ms_Group12_Reserved1 "ICBAD_20ms_Group12_Reserved1";
BA_ "CompuMethodName" SG_ 424 ICBAD_20ms_Group12_Reserved2 "ICBAD_20ms_Group12_Reserved2";
BA_ "GenSigStartValue" SG_ 424 ICBAD_20ms_Group12_Reserved2 31;
BA_ "ISignalName" SG_ 424 ICBAD_20ms_Group12_Reserved2 "IICBAD_20ms_Group12_Reserved2";
BA_ "SysSignalName" SG_ 424 ICBAD_20ms_Group12_Reserved2 "ICBAD_20ms_Group12_Reserved2";
BA_ "CompuMethodName" SG_ 424 APASts "APASts";
BA_ "ISignalName" SG_ 424 APASts "IAPASts";
BA_ "LongName" SG_ 424 APASts "Advanced_Park_Assist_Status";
BA_ "SysSignalName" SG_ 424 APASts "APASts";
BA_ "CompuMethodName" SG_ 424 AutodDrvngSysSts "AutodDrvngSysSts";
BA_ "ISignalName" SG_ 424 AutodDrvngSysSts "IAutodDrvngSysSts";
BA_ "LongName" SG_ 424 AutodDrvngSysSts "Automated_Driving_System_Status";
BA_ "SysSignalName" SG_ 424 AutodDrvngSysSts "AutodDrvngSysSts";
BA_ "CompuMethodName" SG_ 424 ICBAD_20ms_Group12_Reserved3 "ICBAD_20ms_Group12_Reserved3";
BA_ "GenSigStartValue" SG_ 424 ICBAD_20ms_Group12_Reserved3 255;
BA_ "ISignalName" SG_ 424 ICBAD_20ms_Group12_Reserved3 "IICBAD_20ms_Group12_Reserved3";
BA_ "SysSignalName" SG_ 424 ICBAD_20ms_Group12_Reserved3 "ICBAD_20ms_Group12_Reserved3";
BA_ "CompuMethodName" SG_ 424 ICBAD_20ms_Group12_Reserved4 "ICBAD_20ms_Group12_Reserved4";
BA_ "GenSigStartValue" SG_ 424 ICBAD_20ms_Group12_Reserved4 255;
BA_ "ISignalName" SG_ 424 ICBAD_20ms_Group12_Reserved4 "IICBAD_20ms_Group12_Reserved4";
BA_ "SysSignalName" SG_ 424 ICBAD_20ms_Group12_Reserved4 "ICBAD_20ms_Group12_Reserved4";
BA_ "CompuMethodName" SG_ 424 ICBAD_20ms_Group12_Reserved5 "ICBAD_20ms_Group12_Reserved5";
BA_ "GenSigStartValue" SG_ 424 ICBAD_20ms_Group12_Reserved5 255;
BA_ "ISignalName" SG_ 424 ICBAD_20ms_Group12_Reserved5 "IICBAD_20ms_Group12_Reserved5";
BA_ "SysSignalName" SG_ 424 ICBAD_20ms_Group12_Reserved5 "ICBAD_20ms_Group12_Reserved5";
BA_ "CompuMethodName" SG_ 424 ICBAD_20ms_Group12_Reserved6 "ICBAD_20ms_Group12_Reserved6";
BA_ "GenSigStartValue" SG_ 424 ICBAD_20ms_Group12_Reserved6 255;
BA_ "ISignalName" SG_ 424 ICBAD_20ms_Group12_Reserved6 "IICBAD_20ms_Group12_Reserved6";
BA_ "SysSignalName" SG_ 424 ICBAD_20ms_Group12_Reserved6 "ICBAD_20ms_Group12_Reserved6";
BA_ "CompuMethodName" SG_ 520 RPShockDistL "RPShockDistL";
BA_ "ISignalName" SG_ 520 RPShockDistL "IRPShockDistL";
BA_ "LongName" SG_ 520 RPShockDistL "Distance To The Leading Edge Of The First Shock Feature Along The Rolling Path L";
BA_ "SysSignalName" SG_ 520 RPShockDistL "RPShockDistL";
BA_ "CompuMethodName" SG_ 520 RoadProfileShockLevelL "RoadProfileShockLevelL";
BA_ "ISignalName" SG_ 520 RoadProfileShockLevelL "IRoadProfileShockLevelL";
BA_ "LongName" SG_ 520 RoadProfileShockLevelL "Road Profile Shock Level L";
BA_ "SysSignalName" SG_ 520 RoadProfileShockLevelL "RoadProfileShockLevelL";
BA_ "CompuMethodName" SG_ 520 RPShockDistR "RPShockDistR";
BA_ "ISignalName" SG_ 520 RPShockDistR "IRPShockDistR";
BA_ "LongName" SG_ 520 RPShockDistR "Distance To The Leading Edge Of The First Shock Feature Along The Rolling Path R";
BA_ "SysSignalName" SG_ 520 RPShockDistR "RPShockDistR";
BA_ "CompuMethodName" SG_ 520 RoadProfileShockLevelR "RoadProfileShockLevelR";
BA_ "ISignalName" SG_ 520 RoadProfileShockLevelR "IRoadProfileShockLevelR";
BA_ "LongName" SG_ 520 RoadProfileShockLevelR "Road Profile Shock Level R";
BA_ "SysSignalName" SG_ 520 RoadProfileShockLevelR "RoadProfileShockLevelR";
BA_ "CompuMethodName" SG_ 520 RoadProfileShockHeightL "RoadProfileShockHeightL";
BA_ "ISignalName" SG_ 520 RoadProfileShockHeightL "IRoadProfileShockHeightL";
BA_ "LongName" SG_ 520 RoadProfileShockHeightL "The Height Of The Shock Feature L";
BA_ "SysSignalName" SG_ 520 RoadProfileShockHeightL "RoadProfileShockHeightL";
BA_ "CompuMethodName" SG_ 520 RoadProfileShockDetectedL "RoadProfileShockDetectedL";
BA_ "ISignalName" SG_ 520 RoadProfileShockDetectedL "IRoadProfileShockDetectedL";
BA_ "LongName" SG_ 520 RoadProfileShockDetectedL "An Indication That A Shock Feature Has Been Detected L";
BA_ "SysSignalName" SG_ 520 RoadProfileShockDetectedL "RoadProfileShockDetectedL";
BA_ "CompuMethodName" SG_ 520 RoadProfileShockHeightR "RoadProfileShockHeightR";
BA_ "ISignalName" SG_ 520 RoadProfileShockHeightR "IRoadProfileShockHeightR";
BA_ "LongName" SG_ 520 RoadProfileShockHeightR "The Height Of The Shock Feature R";
BA_ "SysSignalName" SG_ 520 RoadProfileShockHeightR "RoadProfileShockHeightR";
BA_ "CompuMethodName" SG_ 520 RoadProfileShockDetectedR "RoadProfileShockDetectedR";
BA_ "ISignalName" SG_ 520 RoadProfileShockDetectedR "IRoadProfileShockDetectedR";
BA_ "LongName" SG_ 520 RoadProfileShockDetectedR "An Indication That A Shock Feature Has Been Detected R";
BA_ "SysSignalName" SG_ 520 RoadProfileShockDetectedR "RoadProfileShockDetectedR";
BA_ "CompuMethodName" SG_ 520 RoadProfileShockConfidenceL "RoadProfileShockConfidenceL";
BA_ "ISignalName" SG_ 520 RoadProfileShockConfidenceL "IRoadProfileShockConfidenceL";
BA_ "LongName" SG_ 520 RoadProfileShockConfidenceL "The Confidence Of The Shock Detection L";
BA_ "SysSignalName" SG_ 520 RoadProfileShockConfidenceL "RoadProfileShockConfidenceL";
BA_ "CompuMethodName" SG_ 520 RoadProfileShockConfidenceR "RoadProfileShockConfidenceR";
BA_ "ISignalName" SG_ 520 RoadProfileShockConfidenceR "IRoadProfileShockConfidenceR";
BA_ "LongName" SG_ 520 RoadProfileShockConfidenceR "The Confidence Of The Shock Detection R";
BA_ "SysSignalName" SG_ 520 RoadProfileShockConfidenceR "RoadProfileShockConfidenceR";

VAL_ 430 EPSAPASts 0 "EPSAPASts_0_Inhibit" 1 "EPSAPASts_1_Available" 2 "EPSAPASts_2_Active" 3 "EPSAPASts_3_Abort" 4 "EPSAPASts_4_ReplyForControl" 5 "EPSAPASts_5_NrcdActive" 6 "EPSAPASts_6_AdasActive" 7 "EPSAPASts_7_Failure";
VAL_ 430 EPSAPAInh 0 "EPSAPAInh_0_Normal_Operation" 1 "EPSAPAInh_1_Over_Speed" 2 "EPSAPAInh_2_Driver_Interference" 4 "EPSAPAInh_4_Abnormal_CAN_input" 8 "EPSAPAInh_8_Excess_Angle_Deviation" 16 "EPSAPAInh_16_EPS_failure";
VAL_ 1252 EPS_NM_BSMtoRMS_CHCANFD 0 "EPS_NM_BSMtoRMS_CHCANFD_0_False" 1 "EPS_NM_BSMtoRMS_CHCANFD_1_True";
VAL_ 1252 EPS_NM_PBSMtoRMS_CHCANFD 0 "EPS_NM_PBSMtoRMS_CHCANFD_0_False" 1 "EPS_NM_PBSMtoRMS_CHCANFD_1_True";
VAL_ 1252 EPS_NM_RMStoNOS_CHCANFD 0 "EPS_NM_RMStoNOS_CHCANFD_0_False" 1 "EPS_NM_RMStoNOS_CHCANFD_1_True";
VAL_ 1252 EPS_NM_RSStoNOS_CHCANFD 0 "EPS_NM_RSStoNOS_CHCANFD_0_False" 1 "EPS_NM_RSStoNOS_CHCANFD_1_True";
VAL_ 1252 EPS_NM_RSStoRMS_CHCANFD 0 "EPS_NM_RSStoRMS_CHCANFD_0_False" 1 "EPS_NM_RSStoRMS_CHCANFD_1_True";
VAL_ 1252 EPS_NM_NOStoRMS_CHCANFD 0 "EPS_NM_NOStoRMS_CHCANFD_0_False" 1 "EPS_NM_NOStoRMS_CHCANFD_1_True";
VAL_ 1252 EPS_NM_NOSSta_CHCANFD 0 "EPS_NM_NOSSta_CHCANFD_0_False" 1 "EPS_NM_NOSSta_CHCANFD_1_True";
VAL_ 1252 EPS_NM_RMSSta_CHCANFD 0 "EPS_NM_RMSSta_CHCANFD_0_False" 1 "EPS_NM_RMSSta_CHCANFD_1_True";
VAL_ 1252 EPS_NWI_CHCANFD 0 "EPS_NWI_CHCANFD_0_NoWakeNetworkSource" 1 "EPS_NWI_CHCANFD_1_PowerModeIsNonOFF";
VAL_ 1252 EPS_NOI_CHCANFD 0 "EPS_NOI_CHCANFD_0_NoRequest" 65535 "EPS_NOI_CHCANFD_65535_AllNetworkOperationActive";
VAL_ 1252 EPS_NKI_CHCANFD 0 "EPS_NKI_CHCANFD_0_NoRequest" 1 "EPS_NKI_CHCANFD_1_PowerModeIsNonOFF";
VAL_ 956 PilotSysMsg 0 "PilotSysMsg_0_No_display" 1 "PilotSysMsg_1_ACC_Active" 2 "PilotSysMsg_2_ACC_Exit" 3 "PilotSysMsg_3_LCC_Active" 4 "PilotSysMsg_4_LCC_UpgradeFromACC" 5 "PilotSysMsg_5_LCC_DegradationToACC" 6 "PilotSysMsg_6_LCC_Exit" 7 "PilotSysMsg_7_NOA_Active" 8 "PilotSysMsg_8_NOA_Upgrade" 9 "PilotSysMsg_9_NOA_DegradationToLCC" 10 "PilotSysMsg_10_NOA_DegradationToACC" 11 "PilotSysMsg_11_NOA_Exit" 12 "PilotSysMsg_12_Reserved" 13 "PilotSysMsg_13_Reserved" 14 "PilotSysMsg_14_Reserved" 15 "PilotSysMsg_15_Reserved";
VAL_ 956 TLRMsgReq 0 "TLRMsgReq_0_NoDisplay" 1 "TLRMsgReq_1_Countdown" 2 "TLRMsgReq_2_Reserved" 3 "TLRMsgReq_3_Reserved";
VAL_ 956 Lane0_MarkerColor 0 "Lane0_MarkerColor_00_no_line" 1 "Lane0_MarkerColor_01_white" 2 "Lane0_MarkerColor_02_red" 3 "Lane0_MarkerColor_03_yellow" 4 "Lane0_MarkerColor_04_other";
VAL_ 956 Lane0_location 0 "Lane0_location_0_Left" 1 "Lane0_location_1_Right" 2 "Lane0_location_2_NextLeft" 3 "Lane0_location_3_NextRight";
VAL_ 956 TLRSysSts 0 "TLRSysSts_0_Off" 1 "TLRSysSts_1_StandBy" 2 "TLRSysSts_2_Active" 3 "TLRSysSts_3_Error";
VAL_ 956 Lane1_location 0 "Lane1_location_0_Left" 1 "Lane1_location_1_Right" 2 "Lane1_location_2_NextLeft" 3 "Lane1_location_3_NextRight";
VAL_ 956 Lane0_MarkerType 0 "Lane0_MarkerType_00_no_line" 1 "Lane0_MarkerType_01_solid" 2 "Lane0_MarkerType_02_dashed" 3 "Lane0_MarkerType_03_curbstone" 4 "Lane0_MarkerType_04_grass" 5 "Lane0_MarkerType_05_Bot_Dott" 6 "Lane0_MarkerType_06_other";
VAL_ 956 Lane1_MarkerType 0 "Lane1_MarkerType_00_no_line" 1 "Lane1_MarkerType_01_solid" 2 "Lane1_MarkerType_02_dashed" 3 "Lane1_MarkerType_03_curbstone" 4 "Lane1_MarkerType_04_grass" 5 "Lane1_MarkerType_05_Bot_Dott" 6 "Lane1_MarkerType_06_other";
VAL_ 956 Lane1_MarkerColor 0 "Lane1_MarkerColor_00_no_line" 1 "Lane1_MarkerColor_01_white" 2 "Lane1_MarkerColor_02_red" 3 "Lane1_MarkerColor_03_yellow" 4 "Lane1_MarkerColor_04_other";
VAL_ 956 Lane2_MarkerColor 0 "Lane2_MarkerColor_00_no_line" 1 "Lane2_MarkerColor_01_white" 2 "Lane2_MarkerColor_02_red" 3 "Lane2_MarkerColor_03_yellow" 4 "Lane2_MarkerColor_04_other";
VAL_ 956 Lane2_location 0 "Lane2_location_0_Left" 1 "Lane2_location_1_Right" 2 "Lane2_location_2_NextLeft" 3 "Lane2_location_3_NextRight";
VAL_ 956 Lane3_location 0 "Lane3_location_0_Left" 1 "Lane3_location_1_Right" 2 "Lane3_location_2_NextLeft" 3 "Lane3_location_3_NextRight";
VAL_ 956 Lane2_MarkerType 0 "Lane2_MarkerType_00_no_line" 1 "Lane2_MarkerType_01_solid" 2 "Lane2_MarkerType_02_dashed" 3 "Lane2_MarkerType_03_curbstone" 4 "Lane2_MarkerType_04_grass" 5 "Lane2_MarkerType_05_Bot_Dott" 6 "Lane2_MarkerType_06_other";
VAL_ 956 Lane3_MarkerType 0 "Lane3_MarkerType_00_no_line" 1 "Lane3_MarkerType_01_solid" 2 "Lane3_MarkerType_02_dashed" 3 "Lane3_MarkerType_03_curbstone" 4 "Lane3_MarkerType_04_grass" 5 "Lane3_MarkerType_05_Bot_Dott" 6 "Lane3_MarkerType_06_other";
VAL_ 956 Lane3_MarkerColor 0 "Lane3_MarkerColor_00_no_line" 1 "Lane3_MarkerColor_01_white" 2 "Lane3_MarkerColor_02_red" 3 "Lane3_MarkerColor_03_yellow" 4 "Lane3_MarkerColor_04_other";
VAL_ 956 TLRWarning 0 "TLRWarning_0_NoRequest" 1 "TLRWarning_1_GreenLightStartAlert_lvl1" 2 "TLRWarning_2_GreenLightStartAlert_lvl2" 3 "TLRWarning_3_RedLightRunAlert_lvl1" 4 "TLRWarning_4_RedLightRunAlert_lvl2" 5 "TLRWarning_5_Reserved" 6 "TLRWarning_6_Reserved";
VAL_ 956 TLRMdSwDspCmd 0 "TLRMdSwDspCmd_0_unavailable" 1 "TLRMdSwDspCmd_1_TLR_on" 2 "TLRMdSwDspCmd_2_TLR_off" 3 "TLRMdSwDspCmd_3_TLR_alert_off" 4 "TLRMdSwDspCmd_4_TLR_alert_on" 5 "TLRMdSwDspCmd_5_Reserved" 6 "TLRMdSwDspCmd_6_Reserved";
VAL_ 956 CCSpdVcCmdCnfm 0 "CCSpdVcCmdCnfm_0_NoResponse" 1 "CCSpdVcCmdCnfm_1_SpeedIsConfirmed" 2 "CCSpdVcCmdCnfm_2_DistanceIsConfirmed" 3 "CCSpdVcCmdCnfm_3_NotInTheRange" 4 "CCSpdVcCmdCnfm_4_AlreadyInMaximunRange" 5 "CCSpdVcCmdCnfm_5_AlreadyInMinimumRange" 6 "CCSpdVcCmdCnfm_6_ACCisActived" 7 "CCSpdVcCmdCnfm_7_ACCisDeactived";
VAL_ 163 LKAReqToqSts 0 "LKAReqToqSts_0_no_request" 1 "LKAReqToqSts_1_torque_request_HO" 2 "LKAReqToqSts_2_reserved_HF" 3 "LKAReqToqSts_3_reserved";
VAL_ 163 LKAReqAngSts 0 "LKAReqAngSts_0_LKAReq_AngSts_0_no_request" 1 "LKAReqAngSts_1_Angle_request_HO" 2 "LKAReqAngSts_2_angle_request_HF" 3 "LKAReqAngSts_3_EMA";
VAL_ 988 BrkFltAlrm_GB 0 "BrkFltAlrm_GB_0_NoAlarm" 1 "BrkFltAlrm_GB_1_Alarm";
VAL_ 988 BrkFrc_GB 0 "BrkFrc_GB_0_False" 1 "BrkFrc_GB_1_True";
VAL_ 988 DistRCAvgDrvnSrc 0 "DistRCAvgDrvnSrc_0_Transmission_Output_Speed" 1 "DistRCAvgDrvnSrc_1_Wheel_Speed";
VAL_ 988 DistRCAvgDrvnRstOcd 0 "DistRCAvgDrvnRstOcd_0_False" 1 "DistRCAvgDrvnRstOcd_1_True";
VAL_ 988 CsbLvlSts 0 "CsbLvlSts_0_off" 1 "CsbLvlSts_1_low" 2 "CsbLvlSts_2_standard" 3 "CsbLvlSts_3_high" 4 "CsbLvlSts_4_reserved" 5 "CsbLvlSts_5_reserved";
VAL_ 988 IBSABSlvlResp 0 "IBSABSlvlResp_0_Normal" 1 "IBSABSlvlResp_1_Reserve" 2 "IBSABSlvlResp_2_Offroad" 3 "IBSABSlvlResp_3_Race" 4 "IBSABSlvlResp_4_Reserve" 5 "IBSABSlvlResp_5_Reserve" 6 "IBSABSlvlResp_6_Reserve" 7 "IBSABSlvlResp_7_Reserve";
VAL_ 988 DistRCAvgDrvnV 0 "DistRCAvgDrvnV_0_Valid" 1 "DistRCAvgDrvnV_1_Invalid";
VAL_ 988 IBSESPlvlResp 0 "IBSESPlvlResp_0_Normal" 1 "IBSESPlvlResp_1_Sport" 2 "IBSESPlvlResp_2_Offroad" 3 "IBSESPlvlResp_3_Race" 4 "IBSESPlvlResp_4_Drift" 5 "IBSESPlvlResp_5_Reserve" 6 "IBSESPlvlResp_6_Reserve" 7 "IBSESPlvlResp_7_Off";
VAL_ 988 IBSTCSlvlResp 0 "IBSTCSlvlResp_0_Normal" 1 "IBSTCSlvlResp_1_Sport" 2 "IBSTCSlvlResp_2_Offroad" 3 "IBSTCSlvlResp_3_Race" 4 "IBSTCSlvlResp_4_Drift" 5 "IBSTCSlvlResp_5_Reserve" 6 "IBSTCSlvlResp_6_Reserve" 7 "IBSTCSlvlResp_7_Off";
VAL_ 318 LDrvnWhlRotlRstOcd 0 "LDrvnWhlRotlRstOcd_0_False" 1 "LDrvnWhlRotlRstOcd_1_True";
VAL_ 318 LDrvnWhlRotlDistV 0 "LDrvnWhlRotlDistV_0_Valid" 1 "LDrvnWhlRotlDistV_1_Invalid";
VAL_ 318 RDrvnWhlRotlRstOcd 0 "RDrvnWhlRotlRstOcd_0_False" 1 "RDrvnWhlRotlRstOcd_1_True";
VAL_ 318 RDrvnWhlRotlDistV 0 "RDrvnWhlRotlDistV_0_Valid" 1 "RDrvnWhlRotlDistV_1_Invalid";
VAL_ 319 LNonDrvnWhlRotlRstOcd 0 "LNonDrvnWhlRotlRstOcd_0_False" 1 "LNonDrvnWhlRotlRstOcd_1_True";
VAL_ 319 LNonDrvnWhlRotlDistV 0 "LNonDrvnWhlRotlDistV_0_Valid" 1 "LNonDrvnWhlRotlDistV_1_Invalid";
VAL_ 319 RNonDrvnWhlRotlRstOcd 0 "RNonDrvnWhlRotlRstOcd_0_False" 1 "RNonDrvnWhlRotlRstOcd_1_True";
VAL_ 319 RNonDrvnWhlRotlDistV 0 "RNonDrvnWhlRotlDistV_0_Valid" 1 "RNonDrvnWhlRotlDistV_1_Invalid";
VAL_ 423 HDCSysSts 0 "HDCSysSts_0_Normal" 1 "HDCSysSts_1_Enabled" 2 "HDCSysSts_2_Active" 3 "HDCSysSts_3_Failed" 4 "HDCSysSts_4_Temporarily_Inhibited";
VAL_ 423 ABSIO 0 "ABSIO_0_False" 1 "ABSIO_1_True";
VAL_ 423 VSESysA 0 "VSESysA_0_False" 1 "VSESysA_1_True";
VAL_ 423 BrkSysYlwBrkTlltReq 0 "BrkSysYlwBrkTlltReq_0_False" 1 "BrkSysYlwBrkTlltReq_1_True";
VAL_ 423 VSESts 0 "VSESts_0_Inactive" 1 "VSESts_1_Active" 2 "VSESts_2_Fault" 3 "VSESts_3_WarmingUp" 4 "VSESts_4_NotReady";
VAL_ 423 VSEMd 0 "VSEMd_0_Off" 1 "VSEMd_1_Normal" 2 "VSEMd_2_Competitive" 3 "VSEMd_3_TraceMd";
VAL_ 423 MultColBrkEnbA 0 "MultColBrkEnbA_0_NoActive" 1 "MultColBrkEnbA_1_Active";
VAL_ 423 EBDFaultSt 0 "EBDFaultSt_0_False" 1 "EBDFaultSt_1_True";
VAL_ 423 TCSOpngSts 0 "TCSOpngSts_0_Inactive" 1 "TCSOpngSts_1_Active" 2 "TCSOpngSts_2_Fault";
VAL_ 423 TCSOpngMd 0 "TCSOpngMd_0_Off" 1 "TCSOpngMd_1_Normal" 2 "TCSOpngMd_2_OffRoad" 3 "TCSOpngMd_3_TraceMd";
VAL_ 423 BrkSysHillStAstAvlbl 0 "BrkSysHillStAstAvlbl_0_False" 1 "BrkSysHillStAstAvlbl_1_True";
VAL_ 423 RgtvBrkFnFltSts 0 "RgtvBrkFnFltSts_0_False" 1 "RgtvBrkFnFltSts_1_True";
VAL_ 423 MSRF 0 "MSRF_0_False" 1 "MSRF_1_True";
VAL_ 423 AutoHoldSysSts 0 "AutoHoldSysSts_0_Off" 1 "AutoHoldSysSts_1_intervention" 2 "AutoHoldSysSts_2_standby" 3 "AutoHoldSysSts_3_error";
VAL_ 423 AutoHoldMsg 0 "AutoHoldMsg_0_reserved" 1 "AutoHoldMsg_1_Seat_belt_not_fastend" 2 "AutoHoldMsg_2_Press_brake_pedal" 3 "AutoHoldMsg_3_Autohold_standby" 4 "AutoHoldMsg_4_Autohold_Off" 5 "AutoHoldMsg_5_Autohold_release" 6 "AutoHoldMsg_6_reserved" 7 "AutoHoldMsg_7_reserved";
VAL_ 423 EBDA 0 "EBDA_0_Notactive" 1 "EBDA_1_Active";
VAL_ 423 RgtvBrkFnSts 0 "RgtvBrkFnSts_0_On" 1 "RgtvBrkFnSts_1_Off";
VAL_ 423 TCSEnbd 0 "TCSEnbd_0_False" 1 "TCSEnbd_1_True";
VAL_ 423 HBAActiveSt 0 "HBAActiveSt_0_False" 1 "HBAActiveSt_1_True";
VAL_ 423 TCSA 0 "TCSA_0_False" 1 "TCSA_1_True";
VAL_ 423 EnDragToqRducnA 0 "EnDragToqRducnA_0_False" 1 "EnDragToqRducnA_1_True";
VAL_ 423 ABSF 0 "ABSF_0_False" 1 "ABSF_1_True";
VAL_ 423 ABSA 0 "ABSA_0_False" 1 "ABSA_1_True";
VAL_ 423 HBAValidSt 0 "HBAValidSt_0_Valid" 1 "HBAValidSt_1_Invalid";
VAL_ 423 MSRA 0 "MSRA_0_MSRActive" 1 "MSRA_1_MSRInactive";
VAL_ 423 EmgcBrkAV 0 "EmgcBrkAV_0_Valid" 1 "EmgcBrkAV_1_Invalid";
VAL_ 423 EmgcBrkA 0 "EmgcBrkA_0_False" 1 "EmgcBrkA_1_True";
VAL_ 423 BrkSysRedBrkTlltReq 0 "BrkSysRedBrkTlltReq_0_False" 1 "BrkSysRedBrkTlltReq_1_True";
VAL_ 423 BrkSysHillStAstSts 0 "BrkSysHillStAstSts_0_Inactive" 1 "BrkSysHillStAstSts_1_Brake_Pressure_Hold" 2 "BrkSysHillStAstSts_2_Normal_Pressure_Decay" 3 "BrkSysHillStAstSts_3_Drive_Off_Pressure_Decay" 4 "BrkSysHillStAstSts_4_Reserved" 5 "BrkSysHillStAstSts_5_Reserved" 6 "BrkSysHillStAstSts_6_Reserved" 7 "BrkSysHillStAstSts_7_Reserved";
VAL_ 423 AVHSigPdlSts 0 "AVHSigPdlSts_0_Off" 1 "AVHSigPdlSts_1_On" 2 "AVHSigPdlSts_2_error" 3 "AVHSigPdlSts_3_reserved";
VAL_ 423 AutoHoldMdSts 0 "AutoHoldMdSts_0_Off" 1 "AutoHoldMdSts_1_normal" 2 "AutoHoldMdSts_2_classic" 3 "AutoHoldMdSts_3_error";
VAL_ 423 SoftSpSysSts 0 "SoftSpSysSts_0_normal" 1 "SoftSpSysSts_1_Enabled" 2 "SoftSpSysSts_2_Active" 3 "SoftSpSysSts_3_Failed";
VAL_ 423 MulColBrkA 0 "MulColBrkA_0_NoActive" 1 "MulColBrkA_1_Active";
VAL_ 423 MulColBrkAvlblySts 0 "MulColBrkAvlblySts_0_False" 1 "MulColBrkAvlblySts_1_True";
VAL_ 342 EPBSts 0 "EPBSts_0_Released" 1 "EPBSts_1_Applied" 2 "EPBSts_2_Fault";
VAL_ 342 EPBAppcnSts 0 "EPBAppcnSts_0_Unknown" 1 "EPBAppcnSts_1_ParkBrakeApplied" 2 "EPBAppcnSts_2_ParkBrakeReleased" 3 "EPBAppcnSts_3_ParkBrakeApplicationInProgress";
VAL_ 342 EPBCCCanclReqd 0 "EPBCCCanclReqd_0_False" 1 "EPBCCCanclReqd_1_True";
VAL_ 342 EPBSysStsIndReq 0 "EPBSysStsIndReq_0_No_Indication" 1 "EPBSysStsIndReq_1_Continuous_Indication" 2 "EPBSysStsIndReq_2_Flash_Rate_1_Indication" 3 "EPBSysStsIndReq_3_Flash_Rate_2_Indication";
VAL_ 342 EPBSwSts 0 "EPBSwSts_0_NotActive" 1 "EPBSwSts_1_Release" 2 "EPBSwSts_2_Apply";
VAL_ 342 EPBAvlblySts 0 "EPBAvlblySts_0_Unavailable_Not_Failed" 1 "EPBAvlblySts_1_Available_Not_Failed" 2 "EPBAvlblySts_2_Unavailable_Failed_Applied" 3 "EPBAvlblySts_3_Unavailable_Failed_Released" 4 "EPBAvlblySts_4_Unavailable_Failed_other" 5 "EPBAvlblySts_5_Unused_and_Reserved_1" 6 "EPBAvlblySts_6_Unused_and_Reserved_2" 7 "EPBAvlblySts_7_Unused_and_Reserved_3";
VAL_ 342 EPBSysAudWrnngReq 0 "EPBSysAudWrnngReq_0_Off" 1 "EPBSysAudWrnngReq_1_Warning_1" 2 "EPBSysAudWrnngReq_2_Warning_2";
VAL_ 342 EPBSwStsV 0 "EPBSwStsV_0_Valid" 1 "EPBSwStsV_1_Invalid";
VAL_ 342 EPBSysWrnngIndReq 0 "EPBSysWrnngIndReq_0_No_Indication" 1 "EPBSysWrnngIndReq_1_Continuous_Indication" 2 "EPBSysWrnngIndReq_2_Flash_Rate_1_Indication" 3 "EPBSysWrnngIndReq_3_Flash_Rate_2_Indication";
VAL_ 342 EPBSysDspMsgReq 0 "EPBSysDspMsgReq_0_Off" 1 "EPBSysDspMsgReq_1_Message_1" 2 "EPBSysDspMsgReq_2_Message_2" 3 "EPBSysDspMsgReq_3_Message_3" 4 "EPBSysDspMsgReq_4_Message_4" 5 "EPBSysDspMsgReq_5_Message_5" 6 "EPBSysDspMsgReq_6_Message_6" 7 "EPBSysDspMsgReq_7_Message_7";
VAL_ 342 EPBAPAAvlbl 0 "EPBAPAAvlbl_0_Unavailable" 1 "EPBAPAAvlbl_1_available";
VAL_ 342 EPBFlrSts 0 "EPBFlrSts_0_NoErrorInEpb" 1 "EPBFlrSts_1_ErrorInEpb";
VAL_ 342 ChSysSecyBrkAxleToqValV 0 "ChSysSecyBrkAxleToqValV_0_valid" 1 "ChSysSecyBrkAxleToqValV_1_invalid";
VAL_ 342 ChSysTrBrkAxleToqValV 0 "ChSysTrBrkAxleToqValV_0_valid" 1 "ChSysTrBrkAxleToqValV_1_invalid";
VAL_ 329 LDrvnWhlRotlDircn 0 "LDrvnWhlRotlDircn_0_Unknown" 1 "LDrvnWhlRotlDircn_1_Forward" 2 "LDrvnWhlRotlDircn_2_Backward" 3 "LDrvnWhlRotlDircn_3_Initial_Invalid";
VAL_ 329 RDrvnWhlRotlDircn 0 "RDrvnWhlRotlDircn_0_Unknown" 1 "RDrvnWhlRotlDircn_1_Forward" 2 "RDrvnWhlRotlDircn_2_Backward" 3 "RDrvnWhlRotlDircn_3_Initial_Invalid";
VAL_ 329 WhlGndVelRDrvnV 0 "WhlGndVelRDrvnV_0_Valid" 1 "WhlGndVelRDrvnV_1_Invalid";
VAL_ 329 WhlGndVelLDrvnV 0 "WhlGndVelLDrvnV_0_Valid" 1 "WhlGndVelLDrvnV_1_Invalid";
VAL_ 329 RDrvnWhlRotlDircnSdslSts 0 "RDrvnWhlRotlDircnSdslSts_0_Notstandstill" 1 "RDrvnWhlRotlDircnSdslSts_1_Standstill";
VAL_ 329 LDrvnWhlRotlDircnSdslSts 0 "LDrvnWhlRotlDircnSdslSts_0_Notstandstill" 1 "LDrvnWhlRotlDircnSdslSts_1_Standstill";
VAL_ 329 ChSysTotBrkAxleToqValV 0 "ChSysTotBrkAxleToqValV_0_Valid" 1 "ChSysTotBrkAxleToqValV_1_Invalid";
VAL_ 425 VehSpdAvgNonDrvnV 0 "VehSpdAvgNonDrvnV_0_Valid" 1 "VehSpdAvgNonDrvnV_1_Invalid";
VAL_ 425 VehSpdAvgV 0 "VehSpdAvgV_0_Valid" 1 "VehSpdAvgV_1_Invalid";
VAL_ 425 VehSpdAvgDrvnV 0 "VehSpdAvgDrvnV_0_Valid" 1 "VehSpdAvgDrvnV_1_Invalid";
VAL_ 425 VehSpdAvgDrvnSrc 0 "VehSpdAvgDrvnSrc_0_Transmission_Output_Speed" 1 "VehSpdAvgDrvnSrc_1_Wheel_Speed";
VAL_ 339 RNonDrvnWhlRotlDircn 0 "RNonDrvnWhlRotlDircn_0_Unknown" 1 "RNonDrvnWhlRotlDircn_1_Forward" 2 "RNonDrvnWhlRotlDircn_2_Backward" 3 "RNonDrvnWhlRotlDircn_3_Initial_Invalid";
VAL_ 339 LNonDrvnWhlRotlDircn 0 "LNonDrvnWhlRotlDircn_0_Unknown" 1 "LNonDrvnWhlRotlDircn_1_Forward" 2 "LNonDrvnWhlRotlDircn_2_Backward" 3 "LNonDrvnWhlRotlDircn_3_Initial_Invalid";
VAL_ 339 WhlGndVelRNonDrvnV 0 "WhlGndVelRNonDrvnV_0_Valid" 1 "WhlGndVelRNonDrvnV_1_Invalid";
VAL_ 339 WhlGndVelLNonDrvnV 0 "WhlGndVelLNonDrvnV_0_Valid" 1 "WhlGndVelLNonDrvnV_1_Invalid";
VAL_ 339 RNonDrvnWhlRotlDircnSdslSts 0 "RNonDrvnWhlRotlDircnSdslSts_0_Notstandstill" 1 "RNonDrvnWhlRotlDircnSdslSts_1_Standstill";
VAL_ 339 LNonDrvnWhlRotlDircnSdslSts 0 "LNonDrvnWhlRotlDircnSdslSts_0_Notstandstill" 1 "LNonDrvnWhlRotlDircnSdslSts_1_Standstill";
VAL_ 1272 IBS_NM_BSMtoRMS_CHCANFD 0 "IBS_NM_BSMtoRMS_CHCANFD_0_False" 1 "IBS_NM_BSMtoRMS_CHCANFD_1_True";
VAL_ 1272 IBS_NM_PBSMtoRMS_CHCANFD 0 "IBS_NM_PBSMtoRMS_CHCANFD_0_False" 1 "IBS_NM_PBSMtoRMS_CHCANFD_1_True";
VAL_ 1272 IBS_NM_RMStoNOS_CHCANFD 0 "IBS_NM_RMStoNOS_CHCANFD_0_False" 1 "IBS_NM_RMStoNOS_CHCANFD_1_True";
VAL_ 1272 IBS_NM_RSStoNOS_CHCANFD 0 "IBS_NM_RSStoNOS_CHCANFD_0_False" 1 "IBS_NM_RSStoNOS_CHCANFD_1_True";
VAL_ 1272 IBS_NM_RSStoRMS_CHCANFD 0 "IBS_NM_RSStoRMS_CHCANFD_0_False" 1 "IBS_NM_RSStoRMS_CHCANFD_1_True";
VAL_ 1272 IBS_NM_NOStoRMS_CHCANFD 0 "IBS_NM_NOStoRMS_CHCANFD_0_False" 1 "IBS_NM_NOStoRMS_CHCANFD_1_True";
VAL_ 1272 IBS_NM_NOSSta_CHCANFD 0 "IBS_NM_NOSSta_CHCANFD_0_False" 1 "IBS_NM_NOSSta_CHCANFD_1_True";
VAL_ 1272 IBS_NM_RMSSta_CHCANFD 0 "IBS_NM_RMSSta_CHCANFD_0_False" 1 "IBS_NM_RMSSta_CHCANFD_1_True";
VAL_ 1272 IBS_NWI_CHCANFD 0 "IBS_NWI_CHCANFD_0_NoWakeNetworkSource" 1 "IBS_NWI_CHCANFD_1_PowerModeIsNonOFF" 2 "IBS_NWI_CHCANFD_2_EpbApplySwitchActive";
VAL_ 1272 IBS_NOI_CHCANFD 0 "IBS_NOI_CHCANFD_0_NoRequest" 65535 "IBS_NOI_CHCANFD_65535_AllNetworkOperationActive";
VAL_ 1272 IBS_NKI_CHCANFD 0 "IBS_NKI_CHCANFD_0_NoRequest" 1 "IBS_NKI_CHCANFD_1_PowerModeIsNonOFF" 2 "IBS_NKI_CHCANFD_2_EPBLampON" 4 "IBS_NKI_CHCANFD_4_EPBSwitchApplied" 8 "IBS_NKI_CHCANFD_8_KeepEPSWorking" 32768 "IBS_NKI_CHCANFD_32768_diagnose_keep";
VAL_ 283 WhlRghRoadV 0 "WhlRghRoadV_0_Valid" 1 "WhlRghRoadV_1_Invalid";
VAL_ 283 SCSMdSts 0 "SCSMdSts_0__Unavailable" 1 "SCSMdSts_1__Normal_Mode" 2 "SCSMdSts_2__TCS_OFF_Mode" 3 "SCSMdSts_3__ESP_OFF_Mode";
VAL_ 283 BrkSysHillRlbkCtrlAvlbl 0 "BrkSysHillRlbkCtrlAvlbl_0_False" 1 "BrkSysHillRlbkCtrlAvlbl_1_True";
VAL_ 283 BrkSysHillRlbkCtrlSts 0 "BrkSysHillRlbkCtrlSts_0_Inactive" 1 "BrkSysHillRlbkCtrlSts_1__Control_Target_Vehicle_Speed" 2 "BrkSysHillRlbkCtrlSts_2_Reserved" 3 "BrkSysHillRlbkCtrlSts_3_Reserved";
VAL_ 507 EPBAppcnSts_M 0 "EPBAppcnSts_M_0_ParkApplied" 1 "EPBAppcnSts_M_1_Released" 2 "EPBAppcnSts_M_2_Unknown" 3 "EPBAppcnSts_M_3_HoldApplied" 4 "EPBAppcnSts_M_4_CompletelyReleased" 5 "EPBAppcnSts_M_5_Applying" 6 "EPBAppcnSts_M_6_Releasing";
VAL_ 507 BrkBstFnSts 0 "BrkBstFnSts_0_normal" 1 "BrkBstFnSts_1_pedal_feelling_error" 2 "BrkBstFnSts_2_partial_fallback" 3 "BrkBstFnSts_3_fallback" 4 "BrkBstFnSts_4_selfcheck";
VAL_ 382 ACCSdslReq 0 "ACCSdslReq_0_No_Request" 1 "ACCSdslReq_1_Request";
VAL_ 382 ACCGoReq 0 "ACCGoReq_0_NoRequest" 1 "ACCGoReq_1_Request";
VAL_ 382 ACCAccReqSts_CH 0 "ACCAccReqSts_CH_0_No_Request" 1 "ACCAccReqSts_CH_1_ACC_Acceleration_Request";
VAL_ 382 APAEPBOPReq 0 "APAEPBOPReq_0_No_Request" 1 "APAEPBOPReq_1_Apply" 2 "APAEPBOPReq_2_Release";
VAL_ 382 ACCSysFltSts 0 "ACCSysFltSts_0_NoError" 1 "ACCSysFltSts_1_PerformanceDegradation" 2 "ACCSysFltSts_2_SystemTemporaryUnvailable" 3 "ACCSysFltSts_3_ServiceRequired" 4 "ACCSysFltSts_4_Reserved" 5 "ACCSysFltSts_5_Reserved" 6 "ACCSysFltSts_6_Reserved" 7 "ACCSysFltSts_7_Reserved";
VAL_ 382 ACCSysSts 0 "ACCSysSts_0_Off" 1 "ACCSysSts_1_StandBy" 2 "ACCSysSts_2_Active" 3 "ACCSysSts_3_Override" 4 "ACCSysSts_4_BrakeOnly" 5 "ACCSysSts_5_StandstillActive" 6 "ACCSysSts_6_StandstillWait" 7 "ACCSysSts_7_Passive";
VAL_ 382 APASCSAcclReqSts 0 "APASCSAcclReqSts_0_NoRequest" 1 "APASCSAcclReqSts_1_DecelerationRequest";
VAL_ 382 APAEPBOPReqV 0 "APAEPBOPReqV_0_Valid" 1 "APAEPBOPReqV_1_Invalid";
VAL_ 382 AutodDrvngSysSCSSdslReqV 0 "AutodDrvngSysSCSSdslReqV_0_Valid" 1 "AutodDrvngSysSCSSdslReqV_1_Invalid";
VAL_ 382 AutodDrvngSysSCSSdslReq 0 "AutodDrvngSysSCSSdslReq_0_NoRequest" 1 "AutodDrvngSysSCSSdslReq_1_request";
VAL_ 382 AutodDrvngSysEmgcBrkReqV 0 "AutodDrvngSysEmgcBrkReqV_0_Valid" 1 "AutodDrvngSysEmgcBrkReqV_1_Invalid";
VAL_ 382 AutodDrvngSysEmgcBrkReq 0 "AutodDrvngSysEmgcBrkReq_0_NoRequest" 1 "AutodDrvngSysEmgcBrkReq_1_EmergencyBrakeRequest";
VAL_ 382 AutodDrvngSysSCSDrvOffReqV 0 "AutodDrvngSysSCSDrvOffReqV_0_Valid" 1 "AutodDrvngSysSCSDrvOffReqV_1_Invalid";
VAL_ 382 AutodDrvngSysSCSDrvOffReq 0 "AutodDrvngSysSCSDrvOffReq_0_NoRequest" 1 "AutodDrvngSysSCSDrvOffReq_1_DriveOffRequest";
VAL_ 382 AutodDrvngSysMdReqV 0 "AutodDrvngSysMdReqV_0_Valid" 1 "AutodDrvngSysMdReqV_1_Invalid";
VAL_ 382 AutodDrvngSysMdReq 0 "AutodDrvngSysMdReq_0_DriverModeRequest" 1 "AutodDrvngSysMdReq_1_AutomatedDriverModeRequest";
VAL_ 382 AutodDrvngSysFlrStsV 0 "AutodDrvngSysFlrStsV_0_Valid" 1 "AutodDrvngSysFlrStsV_1_Invalid";
VAL_ 382 AutodDrvngSysFlrSts 0 "AutodDrvngSysFlrSts_0_NoError" 1 "AutodDrvngSysFlrSts_1_PerformanceDegradation" 2 "AutodDrvngSysFlrSts_2_SystemUnavailable" 3 "AutodDrvngSysFlrSts_3_Reserved" 4 "AutodDrvngSysFlrSts_4_Reserved" 5 "AutodDrvngSysFlrSts_5_Reserved" 6 "AutodDrvngSysFlrSts_6_Reserved" 7 "AutodDrvngSysFlrSts_7_Reserved";
VAL_ 385 NSAReqAVMDis 0 "NSAReqAVMDis_0_NoRequest" 1 "NSAReqAVMDis_1_Request";
VAL_ 385 NSADisFucSts 0 "NSADisFucSts_0_Off" 1 "NSADisFucSts_1_Standby" 2 "NSADisFucSts_2_Active" 3 "NSADisFucSts_3_Fault";
VAL_ 385 NSABacSysSts 0 "NSABacSysSts_0_Off" 1 "NSABacSysSts_1_Standby" 2 "NSABacSysSts_2_BackwardActive" 3 "NSABacSysSts_3_Quit" 4 "NSABacSysSts_4_Error";
VAL_ 385 NSAForSysSts 0 "NSAForSysSts_0_Off" 1 "NSAForSysSts_1_Standby" 2 "NSAForSysSts_2_ForwardActive" 3 "NSAForSysSts_3_Quit" 4 "NSAForSysSts_4_Error" 5 "NSAForSysSts_5_Pause" 6 "NSAForSysSts_6_Complete" 7 "NSAForSysSts_7_Passive";
VAL_ 343 AEBPrflReq 0 "AEBPrflReq_0_False" 1 "AEBPrflReq_1_True";
VAL_ 343 AEBSysSts 0 "AEBSysSts_0_Off" 1 "AEBSysSts_1_Standby" 2 "AEBSysSts_2_Disable" 3 "AEBSysSts_3_Override" 4 "AEBSysSts_4_Active" 5 "AEBSysSts_5_Reserved" 6 "AEBSysSts_6_Reserved" 7 "AEBSysSts_7_Reserved";
VAL_ 343 AEBDclReqSts 0 "AEBDclReqSts_0_NoRequest" 1 "AEBDclReqSts_1_AebDecelerationRequest" 2 "AEBDclReqSts_2_PebDecelerationRequest";
VAL_ 343 AEBBrkJerkLvlReq 0 "AEBBrkJerkLvlReq_0_NoRequest" 1 "AEBBrkJerkLvlReq_1_Level1_low" 2 "AEBBrkJerkLvlReq_2_Level2_middle" 3 "AEBBrkJerkLvlReq_3_Level3_high";
VAL_ 343 AEBHydBrkAstLvlReq 0 "AEBHydBrkAstLvlReq_0_NoRequest" 1 "AEBHydBrkAstLvlReq_1_Level1_low" 2 "AEBHydBrkAstLvlReq_2_Level2_middle" 3 "AEBHydBrkAstLvlReq_3_Level3_high" 4 "AEBHydBrkAstLvlReq_4_Reserved" 5 "AEBHydBrkAstLvlReq_5_Reserved" 6 "AEBHydBrkAstLvlReq_6_Reserved" 7 "AEBHydBrkAstLvlReq_7_Reserved";
VAL_ 343 AEBSysFltSts 0 "AEBSysFltSts_0_NoError" 1 "AEBSysFltSts_1_PerformanceDegradation" 2 "AEBSysFltSts_2_SystemTemporaryUnvailable" 3 "AEBSysFltSts_3_ServiceRequired" 4 "AEBSysFltSts_4_Reserved" 5 "AEBSysFltSts_5_Reserved" 6 "AEBSysFltSts_6_Reserved" 7 "AEBSysFltSts_7_Reserved";
VAL_ 102 PltEPSRdWhlAngReqStsV 0 "PltEPSRdWhlAngReqStsV_0_Valid" 1 "PltEPSRdWhlAngReqStsV_1_Invalid";
VAL_ 102 PltEPSRdWhlAngReqSts 0 "PltEPSRdWhlAngReqSts_0_Off" 1 "PltEPSRdWhlAngReqSts_1_Hands_On_Request_Ready" 2 "PltEPSRdWhlAngReqSts_2_Hands_On_Request_Active" 3 "PltEPSRdWhlAngReqSts_3_Hands_Free_Request_Ready" 4 "PltEPSRdWhlAngReqSts_4_Hands_Free_Request_Active" 5 "PltEPSRdWhlAngReqSts_5_Emergency_function";
VAL_ 360 APAShifterPosReqd 0 "APAShifterPosReqd_0_ScuInitialization" 1 "APAShifterPosReqd_1_S" 2 "APAShifterPosReqd_2_W" 3 "APAShifterPosReqd_3_M" 5 "APAShifterPosReqd_5_D" 6 "APAShifterPosReqd_6_N" 7 "APAShifterPosReqd_7_R" 8 "APAShifterPosReqd_8_P" 9 "APAShifterPosReqd_9_Reserved" 10 "APAShifterPosReqd_10_Error";
VAL_ 360 APASCUReqSts 0 "APASCUReqSts_0_No_Request" 1 "APASCUReqSts_1_Request" 2 "APASCUReqSts_2_Active" 3 "APASCUReqSts_3_Reversed";
VAL_ 360 APACmdEPSSts 0 "APACmdEPSSts_0_No_request" 1 "APACmdEPSSts_1_Control_EPS_request" 2 "APACmdEPSSts_2_EPS_control";
VAL_ 360 APAShifterPosReqdV 0 "APAShifterPosReqdV_0_Valid" 1 "APAShifterPosReqdV_1_Invalid";
VAL_ 360 APASCUReqStsV 0 "APASCUReqStsV_0_Valid" 1 "APASCUReqStsV_1_Invalid";
VAL_ 360 APAF 0 "APAF_0_Normal" 1 "APAF_1_APA_failure";
VAL_ 1122 ACCStsForEdr 0 "ACCStsForEdr_0_Off" 1 "ACCStsForEdr_1_OnbutNotControlling" 2 "ACCStsForEdr_2_ActivelyControlling" 3 "ACCStsForEdr_3_Faulted" 4 "ACCStsForEdr_4_Reserved" 5 "ACCStsForEdr_5_Reserved" 6 "ACCStsForEdr_6_Reserved" 7 "ACCStsForEdr_7_Non_Function";
VAL_ 1122 LDWStsForEdr 0 "LDWStsForEdr_0_Deactivated" 1 "LDWStsForEdr_1_OnbutNotWarning" 2 "LDWStsForEdr_2_WarningLeft" 3 "LDWStsForEdr_3_WarningRight" 4 "LDWStsForEdr_4_Faulted" 5 "LDWStsForEdr_5_Reserved" 6 "LDWStsForEdr_6_Reserved" 7 "LDWStsForEdr_7_Non_Function";
VAL_ 1122 AEBStsForEdr 0 "AEBStsForEdr_0_Deactivated" 1 "AEBStsForEdr_1_OnbutNotIntervening" 2 "AEBStsForEdr_2_WarningbutNotIntervening" 3 "AEBStsForEdr_3_Intervening" 4 "AEBStsForEdr_4_Faulted" 5 "AEBStsForEdr_5_Reserved" 6 "AEBStsForEdr_6_Reserved" 7 "AEBStsForEdr_7_Non_Function";
VAL_ 1122 ESFStsForEdr 0 "ESFStsForEdr_0_Off" 1 "ESFStsForEdr_1_On_but_Not_Intervening" 2 "ESFStsForEdr_2_Intervening" 3 "ESFStsForEdr_3_Faulted" 4 "ESFStsForEdr_4_Reserved" 5 "ESFStsForEdr_5_Reserved" 6 "ESFStsForEdr_6_Reserved" 7 "ESFStsForEdr_7_Non_Function";
VAL_ 1122 CSFStsForEdr 0 "CSFStsForEdr_0_Off" 1 "CSFStsForEdr_1_OnbutNotIntervening" 2 "CSFStsForEdr_2_Intervening" 3 "CSFStsForEdr_3_Faulted" 4 "CSFStsForEdr_4_Reserved" 5 "CSFStsForEdr_5_Reserved" 6 "CSFStsForEdr_6_Reserved" 7 "CSFStsForEdr_7_Non_Function";
VAL_ 1122 ACSFCatgrB1StsForEdr 0 "ACSFCatgrB1StsForEdr_0_Off" 1 "ACSFCatgrB1StsForEdr_1_Standby" 2 "ACSFCatgrB1StsForEdr_2_Active" 3 "ACSFCatgrB1StsForEdr_3_Faulted" 4 "ACSFCatgrB1StsForEdr_4_Reserved" 5 "ACSFCatgrB1StsForEdr_5_Reserved" 6 "ACSFCatgrB1StsForEdr_6_Reserved" 7 "ACSFCatgrB1StsForEdr_7_Non_Function";
VAL_ 1122 ACSFCatgrAStsForEdr 0 "ACSFCatgrAStsForEdr_0_Off" 1 "ACSFCatgrAStsForEdr_1_Standby" 2 "ACSFCatgrAStsForEdr_2_Active" 3 "ACSFCatgrAStsForEdr_3_Faulted" 4 "ACSFCatgrAStsForEdr_4_Reserved" 5 "ACSFCatgrAStsForEdr_5_Reserved" 6 "ACSFCatgrAStsForEdr_6_Reserved" 7 "ACSFCatgrAStsForEdr_7_Non_Function";
VAL_ 1122 ACSFCatgrCStsForEdr 0 "ACSFCatgrCStsForEdr_0_Off" 1 "ACSFCatgrCStsForEdr_1_Standby" 2 "ACSFCatgrCStsForEdr_2_Active" 3 "ACSFCatgrCStsForEdr_3_Faulted" 4 "ACSFCatgrCStsForEdr_4_Reserved" 5 "ACSFCatgrCStsForEdr_5_Reserved" 6 "ACSFCatgrCStsForEdr_6_Reserved" 7 "ACSFCatgrCStsForEdr_7_Non_Function";
VAL_ 1122 ACSFCatgrB2StsForEdr 0 "ACSFCatgrB2StsForEdr_0_Off" 1 "ACSFCatgrB2StsForEdr_1_Standby" 2 "ACSFCatgrB2StsForEdr_2_Active" 3 "ACSFCatgrB2StsForEdr_3_Faulted" 4 "ACSFCatgrB2StsForEdr_4_Reserved" 5 "ACSFCatgrB2StsForEdr_5_Reserved" 6 "ACSFCatgrB2StsForEdr_6_Reserved" 7 "ACSFCatgrB2StsForEdr_7_Non_Function";
VAL_ 1122 ACSFCatgrEStsForEdr 0 "ACSFCatgrEStsForEdr_0_Off" 1 "ACSFCatgrEStsForEdr_1_Standby" 2 "ACSFCatgrEStsForEdr_2_Active" 3 "ACSFCatgrEStsForEdr_3_Faulted" 4 "ACSFCatgrEStsForEdr_4_Reserved" 5 "ACSFCatgrEStsForEdr_5_Reserved" 6 "ACSFCatgrEStsForEdr_6_Reserved" 7 "ACSFCatgrEStsForEdr_7_Non_Function";
VAL_ 1122 ACSFCatgrDStsForEdr 0 "ACSFCatgrDStsForEdr_0_Off" 1 "ACSFCatgrDStsForEdr_1_Standby" 2 "ACSFCatgrDStsForEdr_2_Active" 3 "ACSFCatgrDStsForEdr_3_Faulted" 4 "ACSFCatgrDStsForEdr_4_Reserved" 5 "ACSFCatgrDStsForEdr_5_Reserved" 6 "ACSFCatgrDStsForEdr_6_Reserved" 7 "ACSFCatgrDStsForEdr_7_Non_Function";
VAL_ 474 LDWLKARVsulznReq 0 "LDWLKARVsulznReq_0_no_display" 1 "LDWLKARVsulznReq_1_line_tracking" 2 "LDWLKARVsulznReq_2_intervention" 3 "LDWLKARVsulznReq_3_warning" 4 "LDWLKARVsulznReq_4_intervention_and_warning" 5 "LDWLKARVsulznReq_5_Reserved" 6 "LDWLKARVsulznReq_6_Reserved" 7 "LDWLKARVsulznReq_7_Reserved";
VAL_ 474 LDWLKAVbnLvlReq 0 "LDWLKAVbnLvlReq_0_NoRequest" 1 "LDWLKAVbnLvlReq_1_Level1" 2 "LDWLKAVbnLvlReq_2_Level2" 3 "LDWLKAVbnLvlReq_3_Level3";
VAL_ 474 LDWSysFltSts 0 "LDWSysFltSts_0_no_error" 1 "LDWSysFltSts_1_performance_degradation" 2 "LDWSysFltSts_2_system_temporary_unavailable" 3 "LDWSysFltSts_3_service_required" 4 "LDWSysFltSts_4_Reserved" 5 "LDWSysFltSts_5_Reserved" 6 "LDWSysFltSts_6_Reserved" 7 "LDWSysFltSts_7_Reserved";
VAL_ 474 LDWSysSts 0 "LDWSysSts_0_Off" 1 "LDWSysSts_1_Stand_by" 2 "LDWSysSts_2_Active" 3 "LDWSysSts_3_Override" 4 "LDWSysSts_4_service_required" 5 "LDWSysSts_5_system_temporary_unavailable" 6 "LDWSysSts_6_Active_no_warning" 7 "LDWSysSts_7_reserved";
VAL_ 474 LDWLKALVsulznReq 0 "LDWLKALVsulznReq_0_no_display" 1 "LDWLKALVsulznReq_1_line_tracking" 2 "LDWLKALVsulznReq_2_intervention" 3 "LDWLKALVsulznReq_3_warning" 4 "LDWLKALVsulznReq_4_intervention_and_warning" 5 "LDWLKALVsulznReq_5_Reserved" 6 "LDWLKALVsulznReq_6_Reserved" 7 "LDWLKALVsulznReq_7_Reserved";
VAL_ 424 AutodDrvngSysStsV 0 "AutodDrvngSysStsV_0_Valid" 1 "AutodDrvngSysStsV_1_Invalid";
VAL_ 424 APASts 0 "APASts_0_Disable" 1 "APASts_1_Standby" 2 "APASts_2_Semi_apaActive" 3 "APASts_3_Fully_apaActive" 4 "APASts_4_Failed";
VAL_ 424 AutodDrvngSysSts 0 "AutodDrvngSysSts_CH_0_Off" 1 "AutodDrvngSysSts_CH_1_APA_Disable" 2 "AutodDrvngSysSts_CH_2_APA_Standby" 3 "AutodDrvngSysSts_CH_3_Semi_APA_Active" 4 "AutodDrvngSysSts_CH_4_Fully_APA_Active" 5 "AutodDrvngSysSts_CH_5_APA_Failed" 6 "AutodDrvngSysSts_CH_6_Automated_driving_system_Disable" 7 "AutodDrvngSysSts_CH_7_Automated_driving_system_Standby" 8 "AutodDrvngSysSts_CH_8_Automated_driving_system_Failed" 9 "AutodDrvngSysSts_CH_9_Automated_driving_system_active";
VAL_ 520 RoadProfileShockLevelL 0 "RoadProfileShockLevelL_0_NotDefined" 1 "RoadProfileShockLevelL_1_level1" 2 "RoadProfileShockLevelL_2_level2" 3 "RoadProfileShockLevelL_3_level3" 4 "RoadProfileShockLevelL_4_level4" 5 "RoadProfileShockLevelL_5_level5" 6 "RoadProfileShockLevelL_6_level6" 7 "RoadProfileShockLevelL_7_level7" 8 "RoadProfileShockLevelL_8_level8";
VAL_ 520 RoadProfileShockLevelR 0 "RoadProfileShockLevelR_0_NotDefined" 1 "RoadProfileShockLevelR_1_level1" 2 "RoadProfileShockLevelR_2_level2" 3 "RoadProfileShockLevelR_3_level3" 4 "RoadProfileShockLevelR_4_level4" 5 "RoadProfileShockLevelR_5_level5" 6 "RoadProfileShockLevelR_6_level6" 7 "RoadProfileShockLevelR_7_level7" 8 "RoadProfileShockLevelR_8_level8";
VAL_ 520 RoadProfileShockDetectedL 0 "RoadProfileShockDetectedL_0_NotDetected" 1 "RoadProfileShockDetectedL_1_Detected";
VAL_ 520 RoadProfileShockDetectedR 0 "RoadProfileShockDetectedR_0_NotDetected" 1 "RoadProfileShockDetectedR_1_Detected";
SIG_GROUP_ 430 IEPS_20ms_Group03 1 : EPSAPAInh EPSAPASts EPS_20ms_Group03_CRC EPS_20ms_Group03_RC EPS_20ms_Group03_Reserved1 EPS_20ms_Group03_Reserved2 EPS_20ms_Group03_Reserved3 EPS_20ms_Group03_Reserved4 EPS_20ms_Group03_Reserved5;
SIG_GROUP_ 163 IFVCM_10ms_Group01 1 : FVCM_10ms_Group01_CRC FVCM_10ms_Group01_RC FVCM_10ms_Group01_Reserved1 FVCM_10ms_Group01_Reserved2 FVCM_10ms_Group01_Reserved3 FVCM_10ms_Group01_Reserved4 FVCM_10ms_Group01_Reserved5 FVCM_10ms_Group01_Reserved6 FVCM_10ms_Group01_Reserved7 LKAReqAng LKAReqAngSts LKAReqToq LKAReqToqSts;
SIG_GROUP_ 988 IIBS_100ms_Group15 1 : BrkFltAlrm_GB BrkFrc_GB CsbLvlSts DistRCAvgDrvn DistRCAvgDrvnRstOcd DistRCAvgDrvnSrc DistRCAvgDrvnV IBSABSlvlResp IBSESPlvlResp IBSTCSlvlResp IBS_100ms_Group15_CRC IBS_100ms_Group15_RC IBS_100ms_Group15_Reserved1 IBS_100ms_Group15_Reserved2 IBS_100ms_Group15_Reserved3 IBS_100ms_Group15_Reserved4 IBS_100ms_Group15_Reserved5 IBS_100ms_Group15_Reserved6;
SIG_GROUP_ 318 IIBS_10ms_Group01 1 : LDrvnWhlRotlDistPlsCtr LDrvnWhlRotlDistTRC LDrvnWhlRotlDistTmsp LDrvnWhlRotlDistV LDrvnWhlRotlRstOcd LDrvnWhlRotlSeqNum RDrvnWhlRotlDistPlsCtr RDrvnWhlRotlDistTRC RDrvnWhlRotlDistTmsp RDrvnWhlRotlDistV RDrvnWhlRotlRstOcd RDrvnWhlRotlSeqNum;
SIG_GROUP_ 319 IIBS_10ms_Group02 1 : LNonDrvnWhlRotlDistPC LNonDrvnWhlRotlDistT LNonDrvnWhlRotlDistTRC LNonDrvnWhlRotlDistV LNonDrvnWhlRotlRstOcd LNonDrvnWhlRotlSeqNum RNonDrvnWhlRotlDistPC RNonDrvnWhlRotlDistT RNonDrvnWhlRotlDistTRC RNonDrvnWhlRotlDistV RNonDrvnWhlRotlRstOcd RNonDrvnWhlRotlSeqNum;
SIG_GROUP_ 423 IIBS_20ms_Group07 1 : ABSA ABSF ABSIO AVHSigPdlSts AutoHoldMdSts AutoHoldMsg AutoHoldSysSts BrkSysHillStAstAvlbl BrkSysHillStAstSts BrkSysRedBrkTlltReq BrkSysYlwBrkTlltReq EBDA EBDFaultSt EmgcBrkA EmgcBrkAV EnDragToqRducnA HBAActiveSt HBAValidSt HDCSysSts IBS_20ms_Group07_CRC IBS_20ms_Group07_RC MSRA MSRF MulColBrkA MulColBrkAvlblySts MultColBrkEnbA RgtvBrkFnFltSts RgtvBrkFnSts SoftSpSysSts TCSA TCSEnbd TCSOpngMd TCSOpngSts VSEMd VSESts VSESysA;
SIG_GROUP_ 342 IIBS_20ms_Group08 1 : ChSysSecyBrkAxleToqVal ChSysSecyBrkAxleToqValV ChSysTrBrkAxleToqVal ChSysTrBrkAxleToqValV EPBAPAAvlbl EPBAppcnSts EPBAvlblySts EPBCCCanclReqd EPBFlrSts EPBSts EPBSwSts EPBSwStsV EPBSysAudWrnngReq EPBSysDspMsgReq EPBSysStsIndReq EPBSysWrnngIndReq IBS_20ms_Group08_CRC IBS_20ms_Group08_RC;
SIG_GROUP_ 329 IIBS_20ms_Group09 1 : ChSysTotBrkAxleToqVal ChSysTotBrkAxleToqValV IBS_20ms_Group09_CRC IBS_20ms_Group09_RC IBS_20ms_Group09_Reserved1 LDrvnWhlRotlDircn LDrvnWhlRotlDircnSdslSts RDrvnWhlRotlDircn RDrvnWhlRotlDircnSdslSts WhlGndVelLDrvn WhlGndVelLDrvnV WhlGndVelRDrvn WhlGndVelRDrvnV;
SIG_GROUP_ 425 IIBS_20ms_Group11 1 : IBS_20ms_Group11_CRC IBS_20ms_Group11_RC IBS_20ms_Group11_Reserved1 VehSpdAvg VehSpdAvgDrvn VehSpdAvgDrvnSrc VehSpdAvgDrvnV VehSpdAvgNonDrvn VehSpdAvgNonDrvnV VehSpdAvgV;
SIG_GROUP_ 339 IIBS_20ms_Group12 1 : IBS_20ms_Group12_CRC IBS_20ms_Group12_RC IBS_20ms_Group12_Reserved1 IBS_20ms_Group12_Reserved2 LNonDrvnWhlRotlDircn LNonDrvnWhlRotlDircnSdslSts RNonDrvnWhlRotlDircn RNonDrvnWhlRotlDircnSdslSts WhlGndVelLNonDrvn WhlGndVelLNonDrvnV WhlGndVelRNonDrvn WhlGndVelRNonDrvnV;
SIG_GROUP_ 507 IIBS_ZONE_20ms_Group08 1 : BrkBstFnSts EPBAppcnSts_M IBSRespAccToqVal IBS_ZONE_20ms_Group08_CRC IBS_ZONE_20ms_Group08_RC IBS_ZONE_20ms_Group08_Reserved1 IBS_ZONE_20ms_Group08_Reserved2 IBS_ZONE_20ms_Group08_Reserved3 IBS_ZONE_20ms_Group08_Reserved4 IBS_ZONE_20ms_Group08_Reserved5;
SIG_GROUP_ 382 IICBAD_20ms_Group07 1 : ACCAccReqSts_CH ACCAccReqVal ACCGoReq ACCSdslReq ACCSysFltSts ACCSysSts AIPkgAPASCSAcclReqVal APAEPBOPReq APAEPBOPReqV APASCSAcclReqSts AutodDrvngSysEmgcBrkReq AutodDrvngSysEmgcBrkReqV AutodDrvngSysFlrSts AutodDrvngSysFlrStsV AutodDrvngSysMdReq AutodDrvngSysMdReqV AutodDrvngSysSCSDrvOffReq AutodDrvngSysSCSDrvOffReqV AutodDrvngSysSCSSdslReq AutodDrvngSysSCSSdslReqV ICBAD_20ms_Group07_CRC ICBAD_20ms_Group07_RC ICBAD_20ms_Group07_Reserved1;
SIG_GROUP_ 385 IICBAD_20ms_Group09 1 : ICBAD_20ms_Group09_CRC ICBAD_20ms_Group09_RC ICBAD_20ms_Group09_Reserved1 ICBAD_20ms_Group09_Reserved2 ICBAD_20ms_Group09_Reserved3 ICBAD_20ms_Group09_Reserved4 ICBAD_20ms_Group09_Reserved5 ICBAD_20ms_Group09_Reserved6 NSABacSysSts NSADisFucSts NSAForSysSts NSAReqAVMDis;
SIG_GROUP_ 343 IICBAD_20ms_Group46 1 : AEBBrkJerkLvlReq AEBDclReqSts AEBDclReqToqVal AEBDclReqVal AEBHydBrkAstLvlReq AEBPrflReq AEBSysFltSts AEBSysSts ICBAD_20ms_Group46_CRC ICBAD_20ms_Group46_RC ICBAD_20ms_Group46_Reserved1 ICBAD_20ms_Group46_Reserved2;
SIG_GROUP_ 102 IICBAD_10ms_Group01 1 : EPSToqAppdCoefnt ICBAD_10ms_Group01_CRC ICBAD_10ms_Group01_RC ICBAD_10ms_Group01_Reserved1 ICBAD_10ms_Group01_Reserved10 ICBAD_10ms_Group01_Reserved11 ICBAD_10ms_Group01_Reserved12 ICBAD_10ms_Group01_Reserved13 ICBAD_10ms_Group01_Reserved14 ICBAD_10ms_Group01_Reserved15 ICBAD_10ms_Group01_Reserved16 ICBAD_10ms_Group01_Reserved17 ICBAD_10ms_Group01_Reserved18 ICBAD_10ms_Group01_Reserved19 ICBAD_10ms_Group01_Reserved2 ICBAD_10ms_Group01_Reserved20 ICBAD_10ms_Group01_Reserved21 ICBAD_10ms_Group01_Reserved22 ICBAD_10ms_Group01_Reserved23 ICBAD_10ms_Group01_Reserved3 ICBAD_10ms_Group01_Reserved4 ICBAD_10ms_Group01_Reserved5 ICBAD_10ms_Group01_Reserved6 ICBAD_10ms_Group01_Reserved7 ICBAD_10ms_Group01_Reserved8 ICBAD_10ms_Group01_Reserved9 PltEPSRdWhlAngReqSts PltEPSRdWhlAngReqStsV;
SIG_GROUP_ 360 IICBAD_20ms_Group13 1 : APACmdEPSSts APAF APASCUReqSts APASCUReqStsV APAShifterPosReqd APAShifterPosReqdV APATrgtEPSStrgWhlAng ICBAD_20ms_Group13_CRC ICBAD_20ms_Group13_RC ICBAD_20ms_Group13_Reserved1 ICBAD_20ms_Group13_Reserved2 ICBAD_20ms_Group13_Reserved3 ICBAD_20ms_Group13_Reserved4 ICBAD_20ms_Group13_Reserved5;
SIG_GROUP_ 474 IICBAD_20ms_Group48 1 : ICBAD_20ms_Group48_CRC ICBAD_20ms_Group48_RC ICBAD_20ms_Group48_Reserved1 ICBAD_20ms_Group48_Reserved2 ICBAD_20ms_Group48_Reserved3 ICBAD_20ms_Group48_Reserved4 ICBAD_20ms_Group48_Reserved5 ICBAD_20ms_Group48_Reserved6 LDWLKALVsulznReq LDWLKARVsulznReq LDWLKAVbnLvlReq LDWSysFltSts LDWSysSts;
SIG_GROUP_ 424 IICBAD_20ms_Group12 1 : APASts AutodDrvngSysSts AutodDrvngSysStsV ICBAD_20ms_Group12_CRC ICBAD_20ms_Group12_RC ICBAD_20ms_Group12_Reserved1 ICBAD_20ms_Group12_Reserved2 ICBAD_20ms_Group12_Reserved3 ICBAD_20ms_Group12_Reserved4 ICBAD_20ms_Group12_Reserved5 ICBAD_20ms_Group12_Reserved6;
